VERSION "dbc-export 1 2025.20.8"

NS_ :

BS_:

BU_: APP BMS CC CMP CMPD CP DAS DI DIF DIR EPBL EPBR EVSE FC GTW HCML HCMR HVP ICR PCS PM PMF PMR PTC SCCM SCM SCS SDCR TAS UMC VC VCFRONT VCLEFT VCRIGHT VCSEC

BO_ 798 CP_alertMatrix: 8 CP
 SG_ CP_matrixIndex M : 0|4@1+ (1,0) [0|15] "" Vector__XXX
 SG_ CP_a001_canRx m0 : 4|1@1+ (1,0) [0|1] "" Vector__XXX
 SG_ CP_a002_canTx m0 : 5|1@1+ (1,0) [0|1] "" Vector__XXX
 SG_ CP_a003_canError m0 : 6|1@1+ (1,0) [0|1] "" Vector__XXX
 SG_ CP_a004_proximityRationality m0 : 7|1@1+ (1,0) [0|1] "" Vector__XXX
 SG_ CP_a005_gbdcLiveDisconnect m0 : 8|1@1+ (1,0) [0|1] "" Vector__XXX
 SG_ CP_a006_lostCommsBMS m0 : 9|1@1+ (1,0) [0|1] "" Vector__XXX
 SG_ CP_a007_watchdog m0 : 10|1@1+ (1,0) [0|1] "" Vector__XXX
 SG_ CP_a008_memoryError m0 : 11|1@1+ (1,0) [0|1] "" Vector__XXX
 SG_ CP_a009_coverOpenAllChgBlocked m0 : 12|1@1+ (1,0) [0|1] "" Vector__XXX
 SG_ CP_a010_pilotRationality m0 : 13|1@1+ (1,0) [0|1] "" Vector__XXX
 SG_ CP_a011_eeprom m0 : 14|1@1+ (1,0) [0|1] "" Vector__XXX
 SG_ CP_a012_ledDriver m0 : 15|1@1+ (1,0) [0|1] "" Vector__XXX
 SG_ CP_a013_lostCommsGTW m0 : 16|1@1+ (1,0) [0|1] "" Vector__XXX
 SG_ CP_a014_lostCommsCHG m0 : 17|1@1+ (1,0) [0|1] "" Vector__XXX
 SG_ CP_a015_apsVov m0 : 18|1@1+ (1,0) [0|1] "" Vector__XXX
 SG_ CP_a016_apsVuv m0 : 19|1@1+ (1,0) [0|1] "" Vector__XXX
 SG_ CP_a017_fiveVov m0 : 20|1@1+ (1,0) [0|1] "" Vector__XXX
 SG_ CP_a018_fiveVuv m0 : 21|1@1+ (1,0) [0|1] "" Vector__XXX
 SG_ CP_a019_threeVov m0 : 22|1@1+ (1,0) [0|1] "" Vector__XXX
 SG_ CP_a020_threeVuv m0 : 23|1@1+ (1,0) [0|1] "" Vector__XXX
 SG_ CP_a021_zeroVov m0 : 24|1@1+ (1,0) [0|1] "" Vector__XXX
 SG_ CP_a022_zeroVuv m0 : 25|1@1+ (1,0) [0|1] "" Vector__XXX
 SG_ CP_a023_gbdcSessionFailed m0 : 26|1@1+ (1,0) [0|1] "" Vector__XXX
 SG_ CP_a024_ledsUC m0 : 27|1@1+ (1,0) [0|1] "" Vector__XXX
 SG_ CP_a025_ledsOC m0 : 28|1@1+ (1,0) [0|1] "" Vector__XXX
 SG_ CP_a026_networkManagement m0 : 29|1@1+ (1,0) [0|1] "" Vector__XXX
 SG_ CP_a027_doorSensorOutOfSpec m0 : 30|1@1+ (1,0) [0|1] "" Vector__XXX
 SG_ CP_a028_insertEnableMismatch m0 : 31|1@1+ (1,0) [0|1] "" Vector__XXX
 SG_ CP_a029_doorClosedProxPilot m0 : 32|1@1+ (1,0) [0|1] "" Vector__XXX
 SG_ CP_a030_busOff m0 : 33|1@1+ (1,0) [0|1] "" Vector__XXX
 SG_ CP_a031_doorClosedCommandedOpen m0 : 34|1@1+ (1,0) [0|1] "" Vector__XXX
 SG_ CP_a032_doorOpenExpectedClosed m0 : 35|1@1+ (1,0) [0|1] "" Vector__XXX
 SG_ CP_a033_spiOpen m0 : 36|1@1+ (1,0) [0|1] "" Vector__XXX
 SG_ CP_a034_calibrationIncomplete m0 : 37|1@1+ (1,0) [0|1] "" Vector__XXX
 SG_ CP_a035_latchMovement_1 m0 : 38|1@1+ (1,0) [0|1] "" Vector__XXX
 SG_ CP_a036_latchNotDisengaged m0 : 39|1@1+ (1,0) [0|1] "" Vector__XXX
 SG_ CP_a037_latchNotEngaged m0 : 40|1@1+ (1,0) [0|1] "" Vector__XXX
 SG_ CP_a038_latchNotBlocking m0 : 41|1@1+ (1,0) [0|1] "" Vector__XXX
 SG_ CP_a039_latchMovement_2 m0 : 42|1@1+ (1,0) [0|1] "" Vector__XXX
 SG_ CP_a040_doNotUse m0 : 43|1@1+ (1,0) [0|1] "" Vector__XXX
 SG_ CP_a041_doorSensorUnplugged m0 : 44|1@1+ (1,0) [0|1] "" Vector__XXX
 SG_ CP_a042_doorAssemblyBroken m0 : 45|1@1+ (1,0) [0|1] "" Vector__XXX
 SG_ CP_a043_doorPotIrrational m0 : 46|1@1+ (1,0) [0|1] "" Vector__XXX
 SG_ CP_a044_lostCommsHVP m0 : 47|1@1+ (1,0) [0|1] "" Vector__XXX
 SG_ CP_a045_lostCommsVCSEC m0 : 48|1@1+ (1,0) [0|1] "" Vector__XXX
 SG_ CP_a046_lostCommsEVSE m0 : 49|1@1+ (1,0) [0|1] "" Vector__XXX
 SG_ CP_a047_lostCommsVCFRONT m0 : 50|1@1+ (1,0) [0|1] "" Vector__XXX
 SG_ CP_a048_lostCommsUI m0 : 51|1@1+ (1,0) [0|1] "" Vector__XXX
 SG_ CP_a049_multipleCablesDetected m0 : 52|1@1+ (1,0) [0|1] "" Vector__XXX
 SG_ CP_a050_latchNotConnected m0 : 53|1@1+ (1,0) [0|1] "" Vector__XXX
 SG_ CP_a051_doorInductiveSensorMIA m0 : 54|1@1+ (1,0) [0|1] "" Vector__XXX
 SG_ CP_a052_chademoNotSupported m0 : 55|1@1+ (1,0) [0|1] "" Vector__XXX
 SG_ CP_a053_proxLatchedNoPilot m0 : 56|1@1+ (1,0) [0|1] "" Vector__XXX
 SG_ CP_a054_cableNotSecured m0 : 57|1@1+ (1,0) [0|1] "" Vector__XXX
 SG_ CP_a055_chargeStoppedNoPilot m0 : 58|1@1+ (1,0) [0|1] "" Vector__XXX
 SG_ CP_a056_proxDisconnected m0 : 59|1@1+ (1,0) [0|1] "" Vector__XXX
 SG_ CP_a057_ccs1AdapterBtnPress m0 : 60|1@1+ (1,0) [0|1] "" Vector__XXX
 SG_ CP_a058_acChargeRetryPending m0 : 61|1@1+ (1,0) [0|1] "" Vector__XXX
 SG_ CP_a059_swcanError m0 : 62|1@1+ (1,0) [0|1] "" Vector__XXX
 SG_ CP_a060_lostCommsPCS m0 : 63|1@1+ (1,0) [0|1] "" Vector__XXX
 SG_ CP_a061_uhfReceiverMIA m1 : 4|1@1+ (1,0) [0|1] "" Vector__XXX
 SG_ CP_a062_scOutOfService m1 : 5|1@1+ (1,0) [0|1] "" Vector__XXX
 SG_ CP_a063_scUpdateInProgress m1 : 6|1@1+ (1,0) [0|1] "" Vector__XXX
 SG_ CP_a064_superchargingBlocked m1 : 7|1@1+ (1,0) [0|1] "" Vector__XXX
 SG_ CP_a065_selfTestFailed m1 : 8|1@1+ (1,0) [0|1] "" Vector__XXX
 SG_ CP_a066_proxLatchedIdlePilot m1 : 9|1@1+ (1,0) [0|1] "" Vector__XXX
 SG_ CP_a067_gbdcConnFault m1 : 10|1@1+ (1,0) [0|1] "" Vector__XXX
 SG_ CP_a068_doorSensorMismatch m1 : 11|1@1+ (1,0) [0|1] "" Vector__XXX
 SG_ CP_a069_doorInductiveSensorError m1 : 12|1@1+ (1,0) [0|1] "" Vector__XXX
 SG_ CP_a070_doorInductiveSensorReset m1 : 13|1@1+ (1,0) [0|1] "" Vector__XXX
 SG_ CP_a071_exiDecodeFailure m1 : 14|1@1+ (1,0) [0|1] "" Vector__XXX
 SG_ CP_a072_v2gEvccTimeout m1 : 15|1@1+ (1,0) [0|1] "" Vector__XXX
 SG_ CP_a073_iecComboShutdown m1 : 16|1@1+ (1,0) [0|1] "" Vector__XXX
 SG_ CP_a074_failedToEstablishV2gComm m1 : 17|1@1+ (1,0) [0|1] "" Vector__XXX
 SG_ CP_a075_v2gCommsFailure m1 : 18|1@1+ (1,0) [0|1] "" Vector__XXX
 SG_ CP_a076_LDC1612errorWatchdog m1 : 19|1@1+ (1,0) [0|1] "" Vector__XXX
 SG_ CP_a077_invalidMacAddress m1 : 20|1@1+ (1,0) [0|1] "" Vector__XXX
 SG_ CP_a078_latchNotDisengagedCold m1 : 21|1@1+ (1,0) [0|1] "" Vector__XXX
 SG_ CP_a079_cableNotSecuredCold m1 : 22|1@1+ (1,0) [0|1] "" Vector__XXX
 SG_ CP_a080_taskStackOverflow m1 : 23|1@1+ (1,0) [0|1] "" Vector__XXX
 SG_ CP_a081_swException m1 : 24|1@1+ (1,0) [0|1] "" Vector__XXX
 SG_ CP_a082_powerOnReset m1 : 25|1@1+ (1,0) [0|1] "" Vector__XXX
 SG_ CP_a083_watchdogTraceData m1 : 26|1@1+ (1,0) [0|1] "" Vector__XXX
 SG_ CP_a084_proxPeDisconnected_gb m1 : 27|1@1+ (1,0) [0|1] "" Vector__XXX
 SG_ CP_a085_dcPinTempFaulted m1 : 28|1@1+ (1,0) [0|1] "" Vector__XXX
 SG_ CP_a086_dcPinTempIrrational m1 : 29|1@1+ (1,0) [0|1] "" Vector__XXX
 SG_ CP_a087_dcTempModelFault m1 : 30|1@1+ (1,0) [0|1] "" Vector__XXX
 SG_ CP_a088_dcTempModelDeviation m1 : 31|1@1+ (1,0) [0|1] "" Vector__XXX
 SG_ CP_a089_plcConfigMismatch m1 : 32|1@1+ (1,0) [0|1] "" Vector__XXX
 SG_ CP_a090_ccsEvseLowIso m1 : 33|1@1+ (1,0) [0|1] "" Vector__XXX
 SG_ CP_a091_wrongSuperchargerHandle m1 : 34|1@1+ (1,0) [0|1] "" Vector__XXX
 SG_ CP_a092_modemAppLoadFailed m1 : 35|1@1+ (1,0) [0|1] "" Vector__XXX
 SG_ CP_a093_modemLoadedWithReset m1 : 36|1@1+ (1,0) [0|1] "" Vector__XXX
 SG_ CP_a094_inductiveResetSuccessful m1 : 37|1@1+ (1,0) [0|1] "" Vector__XXX
 SG_ CP_a095_thermalDcLimitActive m1 : 38|1@1+ (1,0) [0|1] "" Vector__XXX
 SG_ CP_a096_pilotWake m1 : 39|1@1+ (1,0) [0|1] "" Vector__XXX
 SG_ CP_a097_modeTransitionFailure m1 : 40|1@1+ (1,0) [0|1] "" Vector__XXX
 SG_ CP_a098_proximityWake m1 : 41|1@1+ (1,0) [0|1] "" Vector__XXX
 SG_ CP_a099_cableStateUnknown m1 : 42|1@1+ (1,0) [0|1] "" Vector__XXX
 SG_ CP_a100_inletHarnessIdIrrational m1 : 43|1@1+ (1,0) [0|1] "" Vector__XXX
 SG_ CP_a101_wcFoldbackActive m1 : 44|1@1+ (1,0) [0|1] "" Vector__XXX
 SG_ CP_a102_wcOvertempFault m1 : 45|1@1+ (1,0) [0|1] "" Vector__XXX
 SG_ CP_a103_proximityPeDisconnected m1 : 46|1@1+ (1,0) [0|1] "" Vector__XXX
 SG_ CP_a104_uhfResetSuccessful m1 : 47|1@1+ (1,0) [0|1] "" Vector__XXX
 SG_ CP_a105_hwUnableToSleep m1 : 48|1@1+ (1,0) [0|1] "" Vector__XXX
 SG_ CP_a106_uhfReceiverReset m1 : 49|1@1+ (1,0) [0|1] "" Vector__XXX
 SG_ CP_a107_chademoFoldbackActive m1 : 50|1@1+ (1,0) [0|1] "" Vector__XXX
 SG_ CP_a108_chademoOvertempFault m1 : 51|1@1+ (1,0) [0|1] "" Vector__XXX
 SG_ CP_a109_thermistorIrrational m1 : 52|1@1+ (1,0) [0|1] "" Vector__XXX
 SG_ CP_a110_thermalVelocityHigh m1 : 53|1@1+ (1,0) [0|1] "" Vector__XXX
 SG_ CP_a111_inletHeaterUnableToHeat m1 : 54|1@1+ (1,0) [0|1] "" Vector__XXX
 SG_ CP_a112_inletHeaterIrrationalTem m1 : 55|1@1+ (1,0) [0|1] "" Vector__XXX
 SG_ CP_a113_inletHeaterShortCircuit m1 : 56|1@1+ (1,0) [0|1] "" Vector__XXX
 SG_ CP_a114_ccsEvseFailed m1 : 57|1@1+ (1,0) [0|1] "" Vector__XXX
 SG_ CP_a115_unexpectedTcan1145State m1 : 58|1@1+ (1,0) [0|1] "" Vector__XXX
 SG_ CP_a116_misconfigurationDetected m1 : 59|1@1+ (1,0) [0|1] "" Vector__XXX
 SG_ CP_a117_inletHeaterUnableToRegul m1 : 60|1@1+ (1,0) [0|1] "" Vector__XXX
 SG_ CP_a118_iecComboLockUp m1 : 61|1@1+ (1,0) [0|1] "" Vector__XXX
 SG_ CP_a119_plcTransmitFailure m1 : 62|1@1+ (1,0) [0|1] "" Vector__XXX
 SG_ CP_a120_comboAdapterFoldback m1 : 63|1@1+ (1,0) [0|1] "" Vector__XXX
 SG_ CP_a121_PLCRLY_lostCommsCP m2 : 4|1@1+ (1,0) [0|1] "" Vector__XXX
 SG_ CP_a122_plcModemFailure m2 : 5|1@1+ (1,0) [0|1] "" Vector__XXX
 SG_ CP_a123_latchPotIrrational m2 : 6|1@1+ (1,0) [0|1] "" Vector__XXX
 SG_ CP_a124_ivledFault m2 : 7|1@1+ (1,0) [0|1] "" Vector__XXX
 SG_ CP_a125_unexpectedLVJuiceState m2 : 8|1@1+ (1,0) [0|1] "" Vector__XXX
 SG_ CP_a126_wakeOnUhfFault m2 : 9|1@1+ (1,0) [0|1] "" Vector__XXX
 SG_ CP_a127_lostCommsHVLINK m2 : 10|1@1+ (1,0) [0|1] "" Vector__XXX
 SG_ CP_a128_lostCommsVC m2 : 11|1@1+ (1,0) [0|1] "" Vector__XXX
 SG_ CP_a129_bldcDriverCommsFailed m2 : 12|1@1+ (1,0) [0|1] "" Vector__XXX
 SG_ CP_a130_bldcDriverCommsRecovered m2 : 13|1@1+ (1,0) [0|1] "" Vector__XXX
 SG_ CP_a131_evseCommTimeout m2 : 14|1@1+ (1,0) [0|1] "" Vector__XXX
 SG_ CP_a132_contractAuthTimeout m2 : 15|1@1+ (1,0) [0|1] "" Vector__XXX
 SG_ CP_a133_proxNeverLatched m2 : 16|1@1+ (1,0) [0|1] "" Vector__XXX
 SG_ CP_a134_plcModemNotExpected m2 : 17|1@1+ (1,0) [0|1] "" Vector__XXX
 SG_ CP_a135_sdpAttemptsFailed m2 : 18|1@1+ (1,0) [0|1] "" Vector__XXX
 SG_ CP_a136_sdpSideReqFailed m2 : 19|1@1+ (1,0) [0|1] "" Vector__XXX
 SG_ CP_a137_plcForwardError m2 : 20|1@1+ (1,0) [0|1] "" Vector__XXX
 SG_ CP_a138_swcanCommsAcEvseFaulted m2 : 21|1@1+ (1,0) [0|1] "" Vector__XXX
 SG_ CP_a139_pilotFaulted m2 : 22|1@1+ (1,0) [0|1] "" Vector__XXX
 SG_ CP_a140_superchargerFaulted m2 : 23|1@1+ (1,0) [0|1] "" Vector__XXX
 SG_ CP_a141_chademoAdapterFault m2 : 24|1@1+ (1,0) [0|1] "" Vector__XXX
 SG_ CP_a142_gbdcScConnFault m2 : 25|1@1+ (1,0) [0|1] "" Vector__XXX
 SG_ CP_a143_unsupportedChargeAdapter m2 : 26|1@1+ (1,0) [0|1] "" Vector__XXX
 SG_ CP_a144_nvmInitFailed m2 : 27|1@1+ (1,0) [0|1] "" Vector__XXX
 SG_ CP_a145_modemAppLoadFailedNA m2 : 28|1@1+ (1,0) [0|1] "" Vector__XXX
 SG_ CP_a146_ccsEvseMalfunction m2 : 29|1@1+ (1,0) [0|1] "" Vector__XXX
 SG_ CP_a147_inductiveRecoveredMia m2 : 30|1@1+ (1,0) [0|1] "" Vector__XXX
 SG_ CP_a148_bldcTachFeedbackMia m2 : 31|1@1+ (1,0) [0|1] "" Vector__XXX
 SG_ CP_a149_pilotPeriodInvalid m2 : 32|1@1+ (1,0) [0|1] "" Vector__XXX
 SG_ CP_a150_railToggleTimeout m2 : 33|1@1+ (1,0) [0|1] "" Vector__XXX
 SG_ CP_a151_badPilotDiodeDetected m2 : 34|1@1+ (1,0) [0|1] "" Vector__XXX
 SG_ CP_a152_pilotEdgeDetectionFailed m2 : 35|1@1+ (1,0) [0|1] "" Vector__XXX
 SG_ CP_a153_thermalAcLimitActive m2 : 36|1@1+ (1,0) [0|1] "" Vector__XXX
 SG_ CP_a154_acChargingStoppedOT m2 : 37|1@1+ (1,0) [0|1] "" Vector__XXX
 SG_ CP_a155_hallPresenceRationality m2 : 38|1@1+ (1,0) [0|1] "" Vector__XXX
 SG_ CP_a156_gbdcPrechargingConcern m2 : 39|1@1+ (1,0) [0|1] "" Vector__XXX
 SG_ CP_a157_doorOpenRateLimiter m2 : 40|1@1+ (1,0) [0|1] "" Vector__XXX
 SG_ CP_a158_doorCloseRateLimiter m2 : 41|1@1+ (1,0) [0|1] "" Vector__XXX
 SG_ CP_a159_swcanHealthCheckFailed m2 : 42|1@1+ (1,0) [0|1] "" Vector__XXX
 SG_ CP_a160_latchDisengageInDcCharge m2 : 43|1@1+ (1,0) [0|1] "" Vector__XXX
 SG_ CP_a161_badPilotDiodeDetectedCN m2 : 44|1@1+ (1,0) [0|1] "" Vector__XXX
 SG_ CP_a162_pilotEdgeDetectionFailed m2 : 45|1@1+ (1,0) [0|1] "" Vector__XXX
 SG_ CP_a163_coverOpenDcChgBlocked m2 : 46|1@1+ (1,0) [0|1] "" Vector__XXX
 SG_ CP_a164_latchRedisengageRequeste m2 : 47|1@1+ (1,0) [0|1] "" Vector__XXX
 SG_ CP_a165_proxWiggleDetected m2 : 48|1@1+ (1,0) [0|1] "" Vector__XXX
 SG_ CP_a166_faultLineMismatchDetecte m2 : 49|1@1+ (1,0) [0|1] "" Vector__XXX
 SG_ CP_a167_doorIdIrrational m2 : 50|1@1+ (1,0) [0|1] "" Vector__XXX
 SG_ CP_a172_triggerOdin m2 : 55|1@1+ (1,0) [0|1] "" Vector__XXX
 SG_ CP_a173_coverOpenAcChgBlocked m2 : 56|1@1+ (1,0) [0|1] "" Vector__XXX
 SG_ CP_a174_fwdedMsgLoadWarning m2 : 57|1@1+ (1,0) [0|1] "" Vector__XXX
 SG_ CP_a175_fwdedMsgDropped m2 : 58|1@1+ (1,0) [0|1] "" Vector__XXX
 SG_ CP_a177_incompatibleV2lDeviceDet m2 : 60|1@1+ (1,0) [0|1] "" Vector__XXX
 SG_ CP_a179_evseCommsTlsError m2 : 62|1@1+ (1,0) [0|1] "" Vector__XXX
 SG_ CP_a182_pncdCommsError m3 : 5|1@1+ (1,0) [0|1] "" Vector__XXX
 SG_ CP_a183_certManagerError m3 : 6|1@1+ (1,0) [0|1] "" Vector__XXX
 SG_ CP_a184_certChangeEvent m3 : 7|1@1+ (1,0) [0|1] "" Vector__XXX
 SG_ CP_a185_pncAuthRejection m3 : 8|1@1+ (1,0) [0|1] "" Vector__XXX
 SG_ CP_a186_spiDmaFailure m3 : 9|1@1+ (1,0) [0|1] "" Vector__XXX
 SG_ CP_a187_highStackUsage m3 : 10|1@1+ (1,0) [0|1] "" Vector__XXX

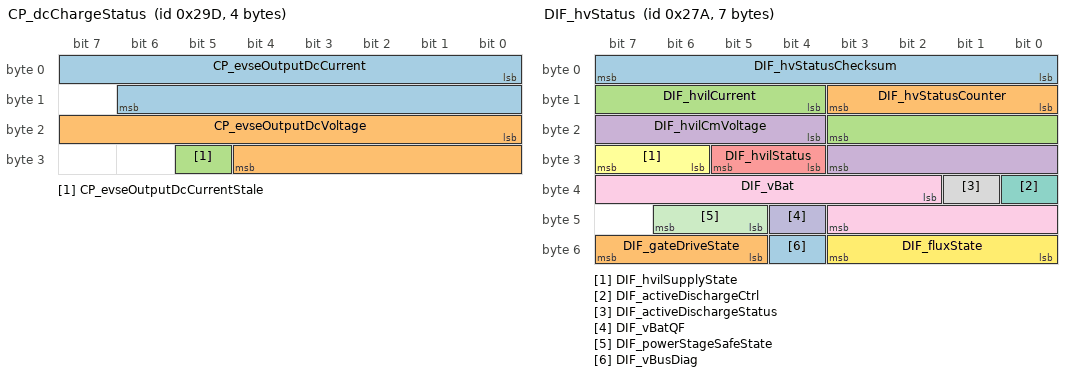
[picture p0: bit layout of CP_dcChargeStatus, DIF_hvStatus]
BO_ 669 CP_dcChargeStatus: 4 CP
 SG_ CP_evseOutputDcCurrent : 0|15@1- (0.125,0) [-2048|2047.875] "A" Vector__XXX
 SG_ CP_evseOutputDcVoltage : 16|13@1+ (0.07324219,0) [0|599.92675822] "V" Vector__XXX
 SG_ CP_evseOutputDcCurrentStale : 29|1@1+ (1,0) [0|1] "" Vector__XXX

BO_ 541 CP_evseStatus: 8 CP
 SG_ CP_evseAccept : 0|1@1+ (1,0) [0|1] "" Vector__XXX
 SG_ CP_evseRequest : 1|1@1+ (1,0) [0|1] "" Vector__XXX
 SG_ CP_proximity : 2|2@1+ (1,0) [1|3] "" Vector__XXX
 SG_ CP_pilot : 4|3@1+ (1,0) [0|6] "" Vector__XXX
 SG_ CP_digitalCommsEstablished : 7|1@1+ (1,0) [0|1] "" Vector__XXX
 SG_ CP_pilotCurrent : 8|8@1+ (0.5,0) [0|127.5] "A" Vector__XXX
 SG_ CP_cableType : 16|3@1+ (1,0) [0|7] "" Vector__XXX
 SG_ CP_iecPilotState : 19|4@1+ (1,0) [0|15] "" Vector__XXX
 SG_ CP_plcSupported : 23|1@1+ (1,0) [0|1] "" Vector__XXX
 SG_ CP_cableCurrentLimit : 24|7@1+ (1,0) [0|127] "A" Vector__XXX
 SG_ CP_teslaSwcanState : 34|4@1+ (1,0) [0|15] "" Vector__XXX
 SG_ CP_evseChargeType_UI : 38|2@1+ (1,0) [0|3] "" Vector__XXX
 SG_ CP_gbState : 40|4@1+ (1,0) [0|15] "" Vector__XXX
 SG_ CP_gbdcStopChargeReason : 44|4@1+ (1,0) [0|15] "" Vector__XXX
 SG_ CP_gbdcFailureReason : 48|2@1+ (1,0) [0|3] "" Vector__XXX
 SG_ CP_gbdcChargeAttempts : 50|2@1+ (1,0) [0|3] "" Vector__XXX
 SG_ CP_acChargeState : 52|3@1+ (1,0) [0|7] "" Vector__XXX
 SG_ CP_teslaDcState : 56|4@1+ (1,0) [0|15] "" Vector__XXX

BO_ 1342 CP_info: 8 CP
 SG_ CP_infoIndex M : 0|8@1+ (1,0) [0|255] "" Vector__XXX
 SG_ CP_buildType m10 : 8|3@1+ (1,0) [0|7] "" Vector__XXX
 SG_ CP_buildConfigId m10 : 16|16@1+ (1,0) [0|65535] "" Vector__XXX
 SG_ CP_hardwareId m10 : 32|16@1+ (1,0) [0|65535] "" Vector__XXX
 SG_ CP_componentId m10 : 48|16@1+ (1,0) [0|65535] "" Vector__XXX
 SG_ CP_pcbaId m11 : 16|8@1+ (1,0) [0|255] "" Vector__XXX
 SG_ CP_assemblyId m11 : 24|8@1+ (1,0) [0|255] "" Vector__XXX
 SG_ CP_usageId m11 : 32|16@1+ (1,0) [0|65535] "" Vector__XXX
 SG_ CP_subUsageId m11 : 48|16@1+ (1,0) [0|65535] "" Vector__XXX
 SG_ CP_platformType m13 : 8|8@1+ (1,0) [0|255] "" Vector__XXX
 SG_ CP_appCrc m13 : 32|32@1+ (1,0) [0|4294967295] "" Vector__XXX
 SG_ CP_appGitHash m17 : 8|56@1+ (1,0) [0|7.20575940379e+16] "" Vector__XXX
 SG_ CP_bootGitHash m18 : 8|56@1+ (1,0) [0|7.20575940379e+16] "" Vector__XXX
 SG_ CP_bootUdsProtoVersion m20 : 8|8@1+ (1,0) [0|255] "" Vector__XXX
 SG_ CP_bootCrc m20 : 32|32@1+ (1,0) [0|4294967295] "" Vector__XXX

BO_ 1885 CP_loggingFast: 8 CP
 SG_ CP_loggingFastSelect M : 0|4@1+ (1,0) [0|15] "" Vector__XXX
 SG_ CP_inductiveSensor_raw m0 : 4|28@1+ (1,0) [0|268435455] "" Vector__XXX
 SG_ CP_doorOpenActuationTime m0 : 32|14@1+ (1,0) [0|16383] "ms" Vector__XXX
 SG_ CP_doorCloseActuationTime m0 : 46|14@1+ (1,0) [0|16383] "ms" Vector__XXX
 SG_ CP_chargeCableSecured m0 : 60|1@1+ (1,0) [0|1] "" Vector__XXX
 SG_ CP_chargeCablePresent m0 : 61|1@1+ (1,0) [0|1] "" Vector__XXX
 SG_ CP_latchCheckAvailable m0 : 62|1@1+ (1,0) [0|1] "" Vector__XXX
 SG_ CP_UHF_controlState m2 : 4|4@1+ (1,0) [0|15] "" Vector__XXX
 SG_ CP_proximityV m2 : 8|16@1+ (0.0001,0) [0|6.5535] "V" Vector__XXX
 SG_ CP_proximityV_GBCC1 m2 : 24|14@1+ (0.001,0) [0|13.3] "V" Vector__XXX
 SG_ CP_proximityV_GBCC2 m2 : 38|14@1+ (0.001,0) [0|13.3] "V" Vector__XXX
 SG_ CP_doorPot m2 : 52|12@1+ (0.025,0) [0|100] "%" Vector__XXX
 SG_ CP_doorPresenceHallSensorV m3 : 4|12@1+ (0.001221,0) [0|4.999995] "V" Vector__XXX
 SG_ CP_doorOpenRequest m3 : 16|4@1+ (1,0) [0|15] "" Vector__XXX
 SG_ CP_doorOpenEndOfDriveReason m3 : 20|3@1+ (1,0) [0|7] "" Vector__XXX
 SG_ CP_coverClosed m3 : 23|1@1+ (1,0) [0|1] "" Vector__XXX
 SG_ CP_doorCloseEndOfDriveReason m3 : 24|3@1+ (1,0) [0|7] "" Vector__XXX
 SG_ CP_doorCloseRequest m3 : 27|5@1+ (1,0) [0|31] "" Vector__XXX
 SG_ CP_latchDisengagingTime m3 : 32|10@1+ (1,0) [0|1023] "ms" Vector__XXX
 SG_ CP_latchEngagingTime m3 : 42|10@1+ (1,0) [0|1023] "ms" Vector__XXX
 SG_ CP_latchDisengagingStopReason m3 : 52|3@1+ (1,0) [0|7] "" Vector__XXX
 SG_ CP_latchEngagingStopReason m3 : 56|3@1+ (1,0) [0|7] "" Vector__XXX
 SG_ CP_doorIdDetectionState m3 : 59|2@1+ (1,0) [1|3] "" Vector__XXX
 SG_ CP_doorIdDetectedBin m3 : 61|2@1+ (1,0) [0|3] "" Vector__XXX

BO_ 989 CP_loggingSlow: 8 CP
 SG_ CP_loggingSlowSelect M : 0|4@1+ (1,0) [0|15] "" Vector__XXX
 SG_ CP_UHF_chipState m3 : 4|3@1+ (1,0) [0|7] "" Vector__XXX
 SG_ CP_UHF_rssi m3 : 8|8@1+ (1,0) [0|255] "" Vector__XXX
 SG_ CP_UHF_rxOverflow m3 : 16|1@1+ (1,0) [0|1] "" Vector__XXX
 SG_ CP_UHF_rxNumBytes m3 : 17|8@1+ (1,0) [0|255] "" Vector__XXX
 SG_ CP_UHF_selfTestRssi m3 : 25|8@1+ (1,0) [0|255] "" Vector__XXX
 SG_ CP_latchI m3 : 33|12@1+ (0.0025,0) [0|10.2375] "A" Vector__XXX
 SG_ CP_inlet1HarnessIdState m3 : 45|2@1+ (1,0) [1|3] "" Vector__XXX
 SG_ CP_inlet1HarnessIdValue m3 : 47|3@1+ (1,0) [0|7] "" Vector__XXX
 SG_ CP_inlet2HarnessIdState m3 : 50|2@1+ (1,0) [1|3] "" Vector__XXX
 SG_ CP_inlet2HarnessIdValue m3 : 52|3@1+ (1,0) [0|7] "" Vector__XXX
 SG_ CP_inletHeaterState m3 : 55|2@1+ (1,0) [0|3] "" Vector__XXX
 SG_ CP_inletHeaterDuty m3 : 57|7@1+ (1,0) [0|100] "%" Vector__XXX
 SG_ CP_nvm_dataValid m5 : 4|1@1+ (1,0) [0|1] "" Vector__XXX
 SG_ CP_nvm_doorOpenCycles m5 : 8|16@1+ (1,0) [0|65535] "" Vector__XXX
 SG_ CP_nvm_doorCloseCycles m5 : 24|16@1+ (1,0) [0|65535] "" Vector__XXX
 SG_ CP_nvm_doorOpen m5 : 40|1@1+ (1,0) [0|1] "" Vector__XXX
 SG_ CP_nvm_doorPresent m5 : 41|1@1+ (1,0) [0|1] "" Vector__XXX
 SG_ CP_nvm_doorPresentValid m5 : 42|1@1+ (1,0) [0|1] "" Vector__XXX
 SG_ CP_nvm_badPilotDiodeDetected m5 : 43|1@1+ (1,0) [0|1] "" Vector__XXX
 SG_ CP_nvm_pilotDiodeFaultCount m5 : 44|3@1+ (1,0) [0|7] "" Vector__XXX
 SG_ CP_doorOpenLimiterMaxCount m5 : 47|4@1+ (1,0) [0|15] "counts" Vector__XXX
 SG_ CP_doorOpenLimiterMaxRequestType m5 : 51|4@1+ (1,0) [0|15] "" Vector__XXX
 SG_ CP_doorCloseLimiterMaxCount m5 : 55|4@1+ (1,0) [0|15] "counts" Vector__XXX
 SG_ CP_doorCloseLimiterMaxRequestTyp m5 : 59|5@1+ (1,0) [0|31] "" Vector__XXX

BO_ 605 CP_status: 8 CP
 SG_ CP_type : 0|2@1+ (1,0) [0|3] "" Vector__XXX
 SG_ CP_insertEnableLine : 2|1@1+ (1,0) [0|1] "" Vector__XXX
 SG_ CP_latchState : 3|2@1+ (1,0) [1|3] "" Vector__XXX
 SG_ CP_permanentPowerRequest : 5|1@1+ (1,0) [0|1] "" Vector__XXX
 SG_ CP_chargeDoorOpen : 6|1@1+ (1,0) [0|1] "" Vector__XXX
 SG_ CP_doorControlState : 8|3@1+ (1,0) [0|7] "" Vector__XXX
 SG_ CP_doorButtonPressed : 11|1@1+ (1,0) [0|1] "" Vector__XXX
 SG_ CP_swcanRelayClosed : 12|1@1+ (1,0) [0|1] "" Vector__XXX
 SG_ CP_inhibitOta : 13|1@1+ (1,0) [0|1] "" Vector__XXX
 SG_ CP_chargeCableState : 14|2@1+ (1,0) [1|3] "" Vector__XXX
 SG_ CP_latchControlState : 16|3@1+ (1,0) [0|7] "" Vector__XXX
 SG_ CP_ledColor : 19|4@1+ (1,0) [0|15] "" Vector__XXX
 SG_ CP_UHF_handleFound : 23|1@1+ (1,0) [0|1] "" Vector__XXX
 SG_ CP_faultLineSensed : 24|1@1+ (1,0) [0|1] "" Vector__XXX
 SG_ CP_doorPresenceState : 25|3@1+ (1,0) [0|7] "" Vector__XXX
 SG_ CP_inductiveSensorState : 28|3@1+ (1,0) [0|7] "" Vector__XXX
 SG_ CP_chargeDoorOpenUI : 31|1@1+ (1,0) [0|1] "" Vector__XXX
 SG_ CP_vehicleUnlockRequest : 32|1@1+ (1,0) [0|1] "" Vector__XXX
 SG_ CP_coldWeatherMode : 33|1@1+ (1,0) [0|1] "" Vector__XXX
 SG_ CP_hvInletExposed : 34|1@1+ (1,0) [0|1] "" Vector__XXX
 SG_ CP_latchEngaged : 35|1@1+ (1,0) [0|1] "" Vector__XXX
 SG_ CP_inletHeaterUiState : 40|3@1+ (1,0) [0|7] "" Vector__XXX

BO_ 893 CP_thermalStatus: 8 CP
 SG_ CP_thermalStatusSelect M : 0|1@1+ (1,0) [0|1] "" Vector__XXX
 SG_ CP_pinTemperature1 m1 : 8|8@1+ (0.8039216,-55) [-55|149.99] "C" Vector__XXX
 SG_ CP_pinTemperature2 m1 : 16|8@1+ (0.8039216,-55) [-55|149.99] "C" Vector__XXX
 SG_ CP_pinTemperature3 m1 : 24|8@1+ (0.8039216,-55) [-55|149.99] "C" Vector__XXX

BO_ 1001 DAS_bodyControls: 8 DAS
 SG_ DAS_headlightRequest : 0|2@1+ (1,0) [0|3] "" Vector__XXX
 SG_ DAS_hazardLightRequest : 2|2@1+ (1,0) [0|2] "" Vector__XXX
 SG_ DAS_wiperSpeed : 4|4@1+ (1,0) [0|15] "" Vector__XXX
 SG_ DAS_turnIndicatorRequest : 8|3@1+ (1,0) [0|7] "" Vector__XXX
 SG_ DAS_highLowBeamDecision : 11|2@1+ (1,0) [0|2] "" Vector__XXX
 SG_ DAS_heaterRequest : 13|2@1+ (1,0) [1|3] "" Vector__XXX
 SG_ DAS_highLowBeamOffReason : 15|3@1+ (1,0) [0|7] "" Vector__XXX
 SG_ DAS_forwardCamHeaterDutyCycle : 18|4@1+ (0.06666667,0) [0|1] "-" Vector__XXX
 SG_ DAS_dynamicBrakeLightRequest : 22|1@1+ (1,0) [0|1] "" Vector__XXX
 SG_ DAS_radarHeaterRequest : 23|1@1+ (1,0) [0|1] "" Vector__XXX
 SG_ DAS_ahlbOverride : 24|1@1+ (1,0) [0|1] "" Vector__XXX
 SG_ DAS_mirrorFoldRequest : 25|2@1+ (1,0) [0|2] "" Vector__XXX
 SG_ DAS_wiperWashRequest : 27|1@1+ (1,0) [0|1] "" Vector__XXX
 SG_ DAS_ulcConfirmationRequestActive : 28|1@1+ (1,0) [0|1] "" Vector__XXX
 SG_ DAS_overrideWiperSetting : 29|1@1+ (1,0) [0|1] "" Vector__XXX
 SG_ DAS_autoWiperState : 30|3@1+ (1,0) [0|7] "" Vector__XXX
 SG_ DAS_turnIndicatorRequestReason : 33|5@1+ (1,0) [0|31] "" Vector__XXX
 SG_ DAS_forwardRadarPowerRequest : 38|1@1+ (1,0) [0|1] "" Vector__XXX
 SG_ DAS_driverDomeLightRequest : 39|1@1+ (1,0) [0|1] "" Vector__XXX
 SG_ DAS_drivePowerStateRequest : 43|1@1+ (1,0) [0|1] "" Vector__XXX
 SG_ DAS_enableIcrDataCollection : 44|1@1+ (1,0) [0|1] "" Vector__XXX
 SG_ DAS_rPillarCamHeaterDutyCycle : 45|4@1+ (0.06666667,0) [0|1] "-" Vector__XXX
 SG_ DAS_adaptiveHighBeamIsFaulted : 49|1@1+ (1,0) [0|1] "" Vector__XXX
 SG_ DAS_restrictDoorReleaseLeft : 50|1@1+ (1,0) [0|1] "" Vector__XXX
 SG_ DAS_restrictDoorReleaseRight : 51|1@1+ (1,0) [0|1] "" Vector__XXX
 SG_ DAS_bodyControlsCounter : 52|4@1+ (1,0) [0|15] "" Vector__XXX
 SG_ DAS_bodyControlsChecksum : 56|8@1+ (1,0) [0|255] "" Vector__XXX

BO_ 1318 DIF_alertLog: 8 DIF
 SG_ DIF_alertID M : 0|8@1+ (1,0) [0|255] "" Vector__XXX
 SG_ DIF_alertState : 15|1@1+ (1,0) [0|1] "" Vector__XXX
 SG_ DIF_a001_thermalWarning_H m1 : 16|1@1+ (1,0) [0|1] "" Vector__XXX
 SG_ DIF_a001_thermalShutdown_H m1 : 17|1@1+ (1,0) [0|1] "" Vector__XXX
 SG_ DIF_a001_undervoltVL_H m1 : 18|1@1+ (1,0) [0|1] "" Vector__XXX
 SG_ DIF_a001_undervoltVH_H m1 : 19|1@1+ (1,0) [0|1] "" Vector__XXX
 SG_ DIF_a001_sense_H m1 : 20|1@1+ (1,0) [0|1] "" Vector__XXX
 SG_ DIF_a001_desat_H m1 : 21|1@1+ (1,0) [0|1] "" Vector__XXX
 SG_ DIF_a001_overvoltVL_H m1 : 22|1@1+ (1,0) [0|1] "" Vector__XXX
 SG_ DIF_a001_overvoltVH_H m1 : 23|1@1+ (1,0) [0|1] "" Vector__XXX
 SG_ DIF_a001_undervoltVCC_H m1 : 24|1@1+ (1,0) [0|1] "" Vector__XXX
 SG_ DIF_a001_asynchStop_H m1 : 25|1@1+ (1,0) [0|1] "" Vector__XXX
 SG_ DIF_a001_remoteRegError_H m1 : 26|1@1+ (1,0) [0|1] "" Vector__XXX
 SG_ DIF_a001_undervoltVDD_H m1 : 27|1@1+ (1,0) [0|1] "" Vector__XXX
 SG_ DIF_a001_overvoltVDD_H m1 : 28|1@1+ (1,0) [0|1] "" Vector__XXX
 SG_ DIF_a001_localRegError_H m1 : 29|1@1+ (1,0) [0|1] "" Vector__XXX
 SG_ DIF_a001_spiError_H m1 : 30|1@1+ (1,0) [0|1] "" Vector__XXX
 SG_ DIF_a001_deadtimeError_H m1 : 31|1@1+ (1,0) [0|1] "" Vector__XXX
 SG_ DIF_a001_thermalWarning_L m1 : 32|1@1+ (1,0) [0|1] "" Vector__XXX
 SG_ DIF_a001_thermalShutdown_L m1 : 33|1@1+ (1,0) [0|1] "" Vector__XXX
 SG_ DIF_a001_undervoltVL_L m1 : 34|1@1+ (1,0) [0|1] "" Vector__XXX
 SG_ DIF_a001_undervoltVH_L m1 : 35|1@1+ (1,0) [0|1] "" Vector__XXX
 SG_ DIF_a001_sense_L m1 : 36|1@1+ (1,0) [0|1] "" Vector__XXX
 SG_ DIF_a001_desat_L m1 : 37|1@1+ (1,0) [0|1] "" Vector__XXX
 SG_ DIF_a001_overvoltVL_L m1 : 38|1@1+ (1,0) [0|1] "" Vector__XXX
 SG_ DIF_a001_overvoltVH_L m1 : 39|1@1+ (1,0) [0|1] "" Vector__XXX
 SG_ DIF_a001_undervoltVCC_L m1 : 40|1@1+ (1,0) [0|1] "" Vector__XXX
 SG_ DIF_a001_asynchStop_L m1 : 41|1@1+ (1,0) [0|1] "" Vector__XXX
 SG_ DIF_a001_remoteRegError_L m1 : 42|1@1+ (1,0) [0|1] "" Vector__XXX
 SG_ DIF_a001_undervoltVDD_L m1 : 43|1@1+ (1,0) [0|1] "" Vector__XXX
 SG_ DIF_a001_overvoltVDD_L m1 : 44|1@1+ (1,0) [0|1] "" Vector__XXX
 SG_ DIF_a001_localRegError_L m1 : 45|1@1+ (1,0) [0|1] "" Vector__XXX
 SG_ DIF_a001_spiError_L m1 : 46|1@1+ (1,0) [0|1] "" Vector__XXX
 SG_ DIF_a001_deadtimeError_L m1 : 47|1@1+ (1,0) [0|1] "" Vector__XXX
 SG_ DIF_a001_gateDriveErrCounter m1 : 48|4@1+ (1,0) [0|15] "" Vector__XXX
 SG_ DIF_a001_remoteCommError_H m1 : 52|1@1+ (1,0) [0|1] "" Vector__XXX
 SG_ DIF_a001_localCommError_H m1 : 53|1@1+ (1,0) [0|1] "" Vector__XXX
 SG_ DIF_a001_remoteReset_H m1 : 54|1@1+ (1,0) [0|1] "" Vector__XXX
 SG_ DIF_a001_localReset_H m1 : 55|1@1+ (1,0) [0|1] "" Vector__XXX
 SG_ DIF_a001_remoteCommError_L m1 : 56|1@1+ (1,0) [0|1] "" Vector__XXX
 SG_ DIF_a001_localCommError_L m1 : 57|1@1+ (1,0) [0|1] "" Vector__XXX
 SG_ DIF_a001_remoteReset_L m1 : 58|1@1+ (1,0) [0|1] "" Vector__XXX
 SG_ DIF_a001_localReset_L m1 : 59|1@1+ (1,0) [0|1] "" Vector__XXX
 SG_ DIF_a001_faultLine1Gpio_H m1 : 60|1@1+ (1,0) [0|1] "" Vector__XXX
 SG_ DIF_a001_faultLine1Gpio_L m1 : 61|1@1+ (1,0) [0|1] "" Vector__XXX
 SG_ DIF_a002_thermalWarning_H m2 : 16|1@1+ (1,0) [0|1] "" Vector__XXX
 SG_ DIF_a002_thermalShutdown_H m2 : 17|1@1+ (1,0) [0|1] "" Vector__XXX
 SG_ DIF_a002_undervoltVL_H m2 : 18|1@1+ (1,0) [0|1] "" Vector__XXX
 SG_ DIF_a002_undervoltVH_H m2 : 19|1@1+ (1,0) [0|1] "" Vector__XXX
 SG_ DIF_a002_sense_H m2 : 20|1@1+ (1,0) [0|1] "" Vector__XXX
 SG_ DIF_a002_desat_H m2 : 21|1@1+ (1,0) [0|1] "" Vector__XXX
 SG_ DIF_a002_overvoltVL_H m2 : 22|1@1+ (1,0) [0|1] "" Vector__XXX
 SG_ DIF_a002_overvoltVH_H m2 : 23|1@1+ (1,0) [0|1] "" Vector__XXX
 SG_ DIF_a002_undervoltVCC_H m2 : 24|1@1+ (1,0) [0|1] "" Vector__XXX
 SG_ DIF_a002_asynchStop_H m2 : 25|1@1+ (1,0) [0|1] "" Vector__XXX
 SG_ DIF_a002_remoteRegError_H m2 : 26|1@1+ (1,0) [0|1] "" Vector__XXX
 SG_ DIF_a002_undervoltVDD_H m2 : 27|1@1+ (1,0) [0|1] "" Vector__XXX
 SG_ DIF_a002_overvoltVDD_H m2 : 28|1@1+ (1,0) [0|1] "" Vector__XXX
 SG_ DIF_a002_localRegError_H m2 : 29|1@1+ (1,0) [0|1] "" Vector__XXX
 SG_ DIF_a002_spiError_H m2 : 30|1@1+ (1,0) [0|1] "" Vector__XXX
 SG_ DIF_a002_deadtimeError_H m2 : 31|1@1+ (1,0) [0|1] "" Vector__XXX
 SG_ DIF_a002_thermalWarning_L m2 : 32|1@1+ (1,0) [0|1] "" Vector__XXX
 SG_ DIF_a002_thermalShutdown_L m2 : 33|1@1+ (1,0) [0|1] "" Vector__XXX
 SG_ DIF_a002_undervoltVL_L m2 : 34|1@1+ (1,0) [0|1] "" Vector__XXX
 SG_ DIF_a002_undervoltVH_L m2 : 35|1@1+ (1,0) [0|1] "" Vector__XXX
 SG_ DIF_a002_sense_L m2 : 36|1@1+ (1,0) [0|1] "" Vector__XXX
 SG_ DIF_a002_desat_L m2 : 37|1@1+ (1,0) [0|1] "" Vector__XXX
 SG_ DIF_a002_overvoltVL_L m2 : 38|1@1+ (1,0) [0|1] "" Vector__XXX
 SG_ DIF_a002_overvoltVH_L m2 : 39|1@1+ (1,0) [0|1] "" Vector__XXX
 SG_ DIF_a002_undervoltVCC_L m2 : 40|1@1+ (1,0) [0|1] "" Vector__XXX
 SG_ DIF_a002_asynchStop_L m2 : 41|1@1+ (1,0) [0|1] "" Vector__XXX
 SG_ DIF_a002_remoteRegError_L m2 : 42|1@1+ (1,0) [0|1] "" Vector__XXX
 SG_ DIF_a002_undervoltVDD_L m2 : 43|1@1+ (1,0) [0|1] "" Vector__XXX
 SG_ DIF_a002_overvoltVDD_L m2 : 44|1@1+ (1,0) [0|1] "" Vector__XXX
 SG_ DIF_a002_localRegError_L m2 : 45|1@1+ (1,0) [0|1] "" Vector__XXX
 SG_ DIF_a002_spiError_L m2 : 46|1@1+ (1,0) [0|1] "" Vector__XXX
 SG_ DIF_a002_deadtimeError_L m2 : 47|1@1+ (1,0) [0|1] "" Vector__XXX
 SG_ DIF_a002_gateDriveErrCounter m2 : 48|4@1+ (1,0) [0|15] "" Vector__XXX
 SG_ DIF_a002_selftestDesat_L m2 : 52|1@1+ (1,0) [0|1] "" Vector__XXX
 SG_ DIF_a002_selftestDesat_H m2 : 53|1@1+ (1,0) [0|1] "" Vector__XXX
 SG_ DIF_a002_remoteCommError_H m2 : 54|1@1+ (1,0) [0|1] "" Vector__XXX
 SG_ DIF_a002_localCommError_H m2 : 55|1@1+ (1,0) [0|1] "" Vector__XXX
 SG_ DIF_a002_remoteReset_H m2 : 56|1@1+ (1,0) [0|1] "" Vector__XXX
 SG_ DIF_a002_localReset_H m2 : 57|1@1+ (1,0) [0|1] "" Vector__XXX
 SG_ DIF_a002_remoteCommError_L m2 : 58|1@1+ (1,0) [0|1] "" Vector__XXX
 SG_ DIF_a002_localCommError_L m2 : 59|1@1+ (1,0) [0|1] "" Vector__XXX
 SG_ DIF_a002_remoteReset_L m2 : 60|1@1+ (1,0) [0|1] "" Vector__XXX
 SG_ DIF_a002_localReset_L m2 : 61|1@1+ (1,0) [0|1] "" Vector__XXX
 SG_ DIF_a002_faultLine1Gpio_H m2 : 62|1@1+ (1,0) [0|1] "" Vector__XXX
 SG_ DIF_a002_faultLine1Gpio_L m2 : 63|1@1+ (1,0) [0|1] "" Vector__XXX
 SG_ DIF_a003_thermalWarning_H m3 : 16|1@1+ (1,0) [0|1] "" Vector__XXX
 SG_ DIF_a003_thermalShutdown_H m3 : 17|1@1+ (1,0) [0|1] "" Vector__XXX
 SG_ DIF_a003_undervoltVL_H m3 : 18|1@1+ (1,0) [0|1] "" Vector__XXX
 SG_ DIF_a003_undervoltVH_H m3 : 19|1@1+ (1,0) [0|1] "" Vector__XXX
 SG_ DIF_a003_sense_H m3 : 20|1@1+ (1,0) [0|1] "" Vector__XXX
 SG_ DIF_a003_desat_H m3 : 21|1@1+ (1,0) [0|1] "" Vector__XXX
 SG_ DIF_a003_overvoltVL_H m3 : 22|1@1+ (1,0) [0|1] "" Vector__XXX
 SG_ DIF_a003_overvoltVH_H m3 : 23|1@1+ (1,0) [0|1] "" Vector__XXX
 SG_ DIF_a003_undervoltVCC_H m3 : 24|1@1+ (1,0) [0|1] "" Vector__XXX
 SG_ DIF_a003_asynchStop_H m3 : 25|1@1+ (1,0) [0|1] "" Vector__XXX
 SG_ DIF_a003_remoteRegError_H m3 : 26|1@1+ (1,0) [0|1] "" Vector__XXX
 SG_ DIF_a003_undervoltVDD_H m3 : 27|1@1+ (1,0) [0|1] "" Vector__XXX
 SG_ DIF_a003_overvoltVDD_H m3 : 28|1@1+ (1,0) [0|1] "" Vector__XXX
 SG_ DIF_a003_localRegError_H m3 : 29|1@1+ (1,0) [0|1] "" Vector__XXX
 SG_ DIF_a003_spiError_H m3 : 30|1@1+ (1,0) [0|1] "" Vector__XXX
 SG_ DIF_a003_deadtimeError_H m3 : 31|1@1+ (1,0) [0|1] "" Vector__XXX
 SG_ DIF_a003_thermalWarning_L m3 : 32|1@1+ (1,0) [0|1] "" Vector__XXX
 SG_ DIF_a003_thermalShutdown_L m3 : 33|1@1+ (1,0) [0|1] "" Vector__XXX
 SG_ DIF_a003_undervoltVL_L m3 : 34|1@1+ (1,0) [0|1] "" Vector__XXX
 SG_ DIF_a003_undervoltVH_L m3 : 35|1@1+ (1,0) [0|1] "" Vector__XXX
 SG_ DIF_a003_sense_L m3 : 36|1@1+ (1,0) [0|1] "" Vector__XXX
 SG_ DIF_a003_desat_L m3 : 37|1@1+ (1,0) [0|1] "" Vector__XXX
 SG_ DIF_a003_overvoltVL_L m3 : 38|1@1+ (1,0) [0|1] "" Vector__XXX
 SG_ DIF_a003_overvoltVH_L m3 : 39|1@1+ (1,0) [0|1] "" Vector__XXX
 SG_ DIF_a003_undervoltVCC_L m3 : 40|1@1+ (1,0) [0|1] "" Vector__XXX
 SG_ DIF_a003_asynchStop_L m3 : 41|1@1+ (1,0) [0|1] "" Vector__XXX
 SG_ DIF_a003_remoteRegError_L m3 : 42|1@1+ (1,0) [0|1] "" Vector__XXX
 SG_ DIF_a003_undervoltVDD_L m3 : 43|1@1+ (1,0) [0|1] "" Vector__XXX
 SG_ DIF_a003_overvoltVDD_L m3 : 44|1@1+ (1,0) [0|1] "" Vector__XXX
 SG_ DIF_a003_localRegError_L m3 : 45|1@1+ (1,0) [0|1] "" Vector__XXX
 SG_ DIF_a003_spiError_L m3 : 46|1@1+ (1,0) [0|1] "" Vector__XXX
 SG_ DIF_a003_deadtimeError_L m3 : 47|1@1+ (1,0) [0|1] "" Vector__XXX
 SG_ DIF_a003_gateDriveErrCounter m3 : 48|4@1+ (1,0) [0|15] "" Vector__XXX
 SG_ DIF_a003_selftestDesat_L m3 : 52|1@1+ (1,0) [0|1] "" Vector__XXX
 SG_ DIF_a003_selftestDesat_H m3 : 53|1@1+ (1,0) [0|1] "" Vector__XXX
 SG_ DIF_a003_remoteCommError_H m3 : 54|1@1+ (1,0) [0|1] "" Vector__XXX
 SG_ DIF_a003_localCommError_H m3 : 55|1@1+ (1,0) [0|1] "" Vector__XXX
 SG_ DIF_a003_remoteReset_H m3 : 56|1@1+ (1,0) [0|1] "" Vector__XXX
 SG_ DIF_a003_localReset_H m3 : 57|1@1+ (1,0) [0|1] "" Vector__XXX
 SG_ DIF_a003_remoteCommError_L m3 : 58|1@1+ (1,0) [0|1] "" Vector__XXX
 SG_ DIF_a003_localCommError_L m3 : 59|1@1+ (1,0) [0|1] "" Vector__XXX
 SG_ DIF_a003_remoteReset_L m3 : 60|1@1+ (1,0) [0|1] "" Vector__XXX
 SG_ DIF_a003_localReset_L m3 : 61|1@1+ (1,0) [0|1] "" Vector__XXX
 SG_ DIF_a003_faultLine1Gpio_H m3 : 62|1@1+ (1,0) [0|1] "" Vector__XXX
 SG_ DIF_a003_faultLine1Gpio_L m3 : 63|1@1+ (1,0) [0|1] "" Vector__XXX
 SG_ DIF_a007_phaseAcurrent m7 : 16|8@1+ (8,0) [0|2040] "A" Vector__XXX
 SG_ DIF_a007_phaseBcurrent m7 : 24|8@1+ (8,0) [0|2040] "A" Vector__XXX
 SG_ DIF_a007_offsetError m7 : 32|14@1- (0.0003834952,0) [-3.1415926784|3.1412091832] "rad" Vector__XXX
 SG_ DIF_a007_idFdbStdDeviation m7 : 46|8@1+ (4,0) [0|1020] "A" Vector__XXX
 SG_ DIF_a007_iqFdbStdDeviation m7 : 54|8@1+ (4,0) [0|1020] "A" Vector__XXX
 SG_ DIF_a007_motorShift m7 : 62|1@1+ (1,0) [0|1] "" Vector__XXX
 SG_ DIF_a007_motorShort m7 : 63|1@1+ (1,0) [0|1] "" Vector__XXX
 SG_ DIF_a010_sccReset m10 : 16|1@1+ (1,0) [0|1] "" Vector__XXX
 SG_ DIF_a010_hibernate m10 : 17|1@1+ (1,0) [0|1] "" Vector__XXX
 SG_ DIF_a010_hwBist m10 : 18|1@1+ (1,0) [0|1] "" Vector__XXX
 SG_ DIF_a010_nmiWatchdog m10 : 19|1@1+ (1,0) [0|1] "" Vector__XXX
 SG_ DIF_a010_watchdog m10 : 20|1@1+ (1,0) [0|1] "" Vector__XXX
 SG_ DIF_a010_clockFailNmi m10 : 21|1@1+ (1,0) [0|1] "" Vector__XXX
 SG_ DIF_a010_ramUncErrorNmi m10 : 22|1@1+ (1,0) [0|1] "" Vector__XXX
 SG_ DIF_a010_flashUncErrorNmi m10 : 23|1@1+ (1,0) [0|1] "" Vector__XXX
 SG_ DIF_a010_cpu1signMismatchNmi m10 : 24|1@1+ (1,0) [0|1] "" Vector__XXX
 SG_ DIF_a010_cpu2signMismatchNmi m10 : 25|1@1+ (1,0) [0|1] "" Vector__XXX
 SG_ DIF_a010_pieVectErrorNmi m10 : 26|1@1+ (1,0) [0|1] "" Vector__XXX
 SG_ DIF_a010_sysDbgNmi m10 : 27|1@1+ (1,0) [0|1] "" Vector__XXX
 SG_ DIF_a010_rlNmi m10 : 28|1@1+ (1,0) [0|1] "" Vector__XXX
 SG_ DIF_a010_ovfNmi m10 : 29|1@1+ (1,0) [0|1] "" Vector__XXX
 SG_ DIF_a010_wdtFlags m10 : 32|16@1+ (1,0) [0|65535] "" Vector__XXX
 SG_ DIF_a011_reason m11 : 16|3@1+ (1,0) [0|7] "" Vector__XXX
 SG_ DIF_a011_phaseAHigh m11 : 19|1@1+ (1,0) [0|1] "" Vector__XXX
 SG_ DIF_a011_phaseALow m11 : 20|1@1+ (1,0) [0|1] "" Vector__XXX
 SG_ DIF_a011_phaseBHigh m11 : 21|1@1+ (1,0) [0|1] "" Vector__XXX
 SG_ DIF_a011_phaseBLow m11 : 22|1@1+ (1,0) [0|1] "" Vector__XXX
 SG_ DIF_a011_phaseCHigh m11 : 23|1@1+ (1,0) [0|1] "" Vector__XXX
 SG_ DIF_a011_phaseCLow m11 : 24|1@1+ (1,0) [0|1] "" Vector__XXX
 SG_ DIF_a011_regAddress m11 : 25|5@1+ (1,0) [0|31] "" Vector__XXX
 SG_ DIF_a011_badGateDriveIC m11 : 32|3@1+ (1,0) [0|7] "" Vector__XXX
 SG_ DIF_a011_badDataRead m11 : 40|8@1+ (1,0) [0|255] "" Vector__XXX
 SG_ DIF_a011_badDataExpected m11 : 48|8@1+ (1,0) [0|255] "" Vector__XXX
 SG_ DIF_a011_codeBranch m11 : 56|4@1+ (1,0) [0|15] "" Vector__XXX
 SG_ DIF_a012_hvilStatus m12 : 16|2@1+ (1,0) [0|2] "" Vector__XXX
 SG_ DIF_a012_hvilCmVoltage m12 : 24|8@1+ (0.08,0) [0|20.4] "V" Vector__XXX
 SG_ DIF_a012_hvilCurrent m12 : 32|8@1+ (0.1,0) [0|25.5] "mA" Vector__XXX
 SG_ DIF_a012_hvilFaultGpio m12 : 40|1@1+ (1,0) [0|1] "" Vector__XXX
 SG_ DIF_a012_hvilSupplyPinDI m12 : 41|1@1+ (1,0) [0|1] "" Vector__XXX
 SG_ DIF_a012_hvilSupplyPinPM m12 : 42|1@1+ (1,0) [0|1] "" Vector__XXX
 SG_ DIF_a012_activeDisOn3V3 m12 : 43|1@1+ (1,0) [0|1] "" Vector__XXX
 SG_ DIF_a012_hvilHeaderFault m12 : 44|1@1+ (1,0) [0|1] "" Vector__XXX
 SG_ DIF_a013_address m13 : 16|32@1+ (1,0) [0|4294967295] "" Vector__XXX
 SG_ DIF_a013_errorType m13 : 48|4@1+ (1,0) [0|15] "" Vector__XXX
 SG_ DIF_a014_motorSpeed m14 : 16|14@1- (2,0) [-16384|16382] "RPM" Vector__XXX
 SG_ DIF_a014_adState m14 : 30|2@1+ (1,0) [0|3] "" Vector__XXX
 SG_ DIF_a014_torqueCommandFwd m14 : 32|10@1- (2,0) [-1024|1022] "Nm" Vector__XXX
 SG_ DIF_a014_brakeMasterCylPress m14 : 42|10@1+ (0.25,-42.5) [-42.5|213.25] "bar" Vector__XXX
 SG_ DIF_a014_rmsTorqueError m14 : 52|10@1+ (1,0) [0|1023] "Nm" Vector__XXX
 SG_ DIF_a014_tcEnabled m14 : 62|1@1+ (1,0) [0|1] "" Vector__XXX
 SG_ DIF_a016_newSafeState m16 : 16|2@1+ (1,0) [0|3] "" Vector__XXX
 SG_ DIF_a016_oldSafeState m16 : 18|2@1+ (1,0) [0|3] "" Vector__XXX
 SG_ DIF_a016_gateDriveFaultLine m16 : 20|1@1+ (1,0) [0|1] "" Vector__XXX
 SG_ DIF_a016_ascMonitor m16 : 21|1@1+ (1,0) [0|1] "" Vector__XXX
 SG_ DIF_a016_uncontrolledRegenZone m16 : 22|1@1+ (1,0) [0|1] "" Vector__XXX
 SG_ DIF_a016_pedalMonitorPreWatchdog m16 : 23|1@1+ (1,0) [0|1] "" Vector__XXX
 SG_ DIF_a016_motorRPM m16 : 24|16@1- (1,0) [-32768|32767] "RPM" Vector__XXX
 SG_ DIF_a016_torqueMotor m16 : 40|16@1- (1,0) [-32768|32767] "Nm" Vector__XXX
 SG_ DIF_a016_safetyICfaultLine m16 : 56|1@1+ (1,0) [0|1] "" Vector__XXX
 SG_ DIF_a016_triggerEvent m16 : 57|5@1+ (1,0) [0|31] "" Vector__XXX
 SG_ DIF_a024_vBat m24 : 16|8@1+ (2,0) [0|510] "V" Vector__XXX
 SG_ DIF_a024_failReason m24 : 24|3@1+ (1,0) [0|7] "" Vector__XXX
 SG_ DIF_a024_state m24 : 27|4@1+ (1,0) [0|15] "" Vector__XXX
 SG_ DIF_a024_Ia m24 : 31|7@1- (22.5,0) [-1440|1417.5] "A" Vector__XXX
 SG_ DIF_a024_Ib m24 : 38|7@1- (22.5,0) [-1440|1417.5] "A" Vector__XXX
 SG_ DIF_a024_maxCurrMagSqrd m24 : 45|12@1+ (500,0) [0|2047500] "A2" Vector__XXX
 SG_ DIF_a024_rotorAngle m24 : 57|7@1- (3,0) [-192|189] "degrees" Vector__XXX
 SG_ DIF_a025_Ia m25 : 16|16@1- (0.1,0) [-3276.8|3276.7] "A" Vector__XXX
 SG_ DIF_a025_torqueMotor m25 : 32|13@1- (0.25,0) [-1024|1023.75] "Nm" Vector__XXX
 SG_ DIF_a025_motorSpeed m25 : 48|16@1- (1,0) [-32768|32767] "RPM" Vector__XXX
 SG_ DIF_a026_Ib m26 : 16|16@1- (0.1,0) [-3276.8|3276.7] "A" Vector__XXX
 SG_ DIF_a026_torqueMotor m26 : 32|13@1- (0.25,0) [-1024|1023.75] "Nm" Vector__XXX
 SG_ DIF_a026_motorSpeed m26 : 48|16@1- (1,0) [-32768|32767] "RPM" Vector__XXX
 SG_ DIF_a027_Ic m27 : 16|16@1- (0.1,0) [-3276.8|3276.7] "A" Vector__XXX
 SG_ DIF_a027_torqueMotor m27 : 32|13@1- (0.25,0) [-1024|1023.75] "Nm" Vector__XXX
 SG_ DIF_a027_motorSpeed m27 : 48|16@1- (1,0) [-32768|32767] "RPM" Vector__XXX
 SG_ DIF_a028_phaseAirms m28 : 16|16@1+ (1,0) [0|65535] "A" Vector__XXX
 SG_ DIF_a028_iArmsTorque m28 : 32|16@1+ (0.25,0) [0|16383.75] "Nm" Vector__XXX
 SG_ DIF_a028_iArmsSpeed m28 : 48|16@1+ (1,0) [0|65535] "RPM" Vector__XXX
 SG_ DIF_a029_phaseBirms m29 : 16|16@1+ (1,0) [0|65535] "A" Vector__XXX
 SG_ DIF_a029_iBrmsTorque m29 : 32|16@1+ (0.25,0) [0|16383.75] "Nm" Vector__XXX
 SG_ DIF_a029_iBrmsSpeed m29 : 48|16@1+ (1,0) [0|65535] "RPM" Vector__XXX
 SG_ DIF_a030_phaseCirms m30 : 16|16@1+ (1,0) [0|65535] "A" Vector__XXX
 SG_ DIF_a030_iCrmsTorque m30 : 32|16@1+ (0.25,0) [0|16383.75] "Nm" Vector__XXX
 SG_ DIF_a030_iCrmsSpeed m30 : 48|16@1+ (1,0) [0|65535] "RPM" Vector__XXX
 SG_ DIF_a031_phaseAoffset m31 : 16|16@1- (0.002,0) [-65.536|65.534] "A" Vector__XXX
 SG_ DIF_a032_phaseBoffset m32 : 16|16@1- (0.002,0) [-65.536|65.534] "A" Vector__XXX
 SG_ DIF_a033_phaseAcurrent m33 : 16|16@1- (1,0) [-32768|32767] "A" Vector__XXX
 SG_ DIF_a033_deltaIa m33 : 32|16@1- (1,0) [-32768|32767] "A" Vector__XXX
 SG_ DIF_a033_vRefIa m33 : 48|16@1- (0.001,0) [-32.768|32.767] "V" Vector__XXX
 SG_ DIF_a034_phaseBcurrent m34 : 16|16@1- (1,0) [-32768|32767] "A" Vector__XXX
 SG_ DIF_a034_deltaIb m34 : 32|16@1- (1,0) [-32768|32767] "A" Vector__XXX
 SG_ DIF_a034_vRefIb m34 : 48|16@1- (0.001,0) [-32.768|32.767] "V" Vector__XXX
 SG_ DIF_a035_phaseAerror m35 : 16|1@1+ (1,0) [0|1] "" Vector__XXX
 SG_ DIF_a035_phaseBerror m35 : 17|1@1+ (1,0) [0|1] "" Vector__XXX
 SG_ DIF_a035_phaseCerror m35 : 18|1@1+ (1,0) [0|1] "" Vector__XXX
 SG_ DIF_a035_standbyCurrent m35 : 19|1@1+ (1,0) [0|1] "" Vector__XXX
 SG_ DIF_a035_unbalancedCurrent m35 : 20|1@1+ (1,0) [0|1] "" Vector__XXX
 SG_ DIF_a035_wontMoveCurrent m35 : 21|1@1+ (1,0) [0|1] "" Vector__XXX
 SG_ DIF_a035_reportingPhase m35 : 22|2@1+ (1,0) [0|3] "" Vector__XXX
 SG_ DIF_a035_noDriveCurrent m35 : 24|1@1+ (1,0) [0|1] "" Vector__XXX
 SG_ DIF_a035_phaseDifference m35 : 25|7@1+ (1,0) [0|127] "%" Vector__XXX
 SG_ DIF_a035_phaseCurrent m35 : 32|16@1+ (1,0) [0|65535] "A" Vector__XXX
 SG_ DIF_a035_frequency m35 : 48|10@1+ (1,0) [0|1023] "Hz" Vector__XXX
 SG_ DIF_a036_busVoltage m36 : 16|16@1+ (0.1,0) [0|6553.5] "V" Vector__XXX
 SG_ DIF_a036_busHighLimit m36 : 32|16@1+ (0.1,0) [0|6553.5] "V" Vector__XXX
 SG_ DIF_a037_busVoltage m37 : 16|16@1+ (0.1,0) [0|6553.5] "V" Vector__XXX
 SG_ DIF_a037_busLowLimit m37 : 32|16@1+ (0.1,0) [0|6553.5] "V" Vector__XXX
 SG_ DIF_a038_vBMS m38 : 16|13@1+ (0.2,0) [0|1638.2] "V" Vector__XXX
 SG_ DIF_a038_vBat m38 : 32|13@1+ (0.2,0) [0|1638.2] "V" Vector__XXX
 SG_ DIF_a038_iBat m38 : 48|13@1+ (0.5,0) [0|4095.5] "A" Vector__XXX
 SG_ DIF_a038_reason m38 : 61|2@1+ (1,0) [0|3] "" Vector__XXX
 SG_ DIF_a040_torque m40 : 16|1@1+ (1,0) [0|1] "" Vector__XXX
 SG_ DIF_a040_capability m40 : 17|1@1+ (1,0) [0|1] "" Vector__XXX
 SG_ DIF_a040_power m40 : 18|1@1+ (1,0) [0|1] "" Vector__XXX
 SG_ DIF_a040_status m40 : 19|1@1+ (1,0) [0|1] "" Vector__XXX
 SG_ DIF_a040_capability2 m40 : 20|1@1+ (1,0) [0|1] "" Vector__XXX
 SG_ DIF_a040_hvStatus m40 : 21|1@1+ (1,0) [0|1] "" Vector__XXX
 SG_ DIF_a040_temperature m40 : 22|1@1+ (1,0) [0|1] "" Vector__XXX
 SG_ DIF_a041_uartRxDataAvailable m41 : 16|1@1+ (1,0) [0|1] "" Vector__XXX
 SG_ DIF_a041_SDC_status_MIA m41 : 17|1@1+ (1,0) [0|1] "" Vector__XXX
 SG_ DIF_a041_diUartRxVersion m41 : 18|4@1+ (1,0) [0|15] "" Vector__XXX
 SG_ DIF_a041_sdcUartRxVersion m41 : 24|4@1+ (1,0) [0|15] "" Vector__XXX
 SG_ DIF_a043_outletTemp m43 : 16|16@1- (0.1,0) [-3276.8|3276.7] "C" Vector__XXX
 SG_ DIF_a044_outletTemp m44 : 16|16@1- (0.1,0) [-3276.8|3276.7] "C" Vector__XXX
 SG_ DIF_a045_inletTemp m45 : 16|10@1+ (0.25,-60) [-60|195.75] "DegC" Vector__XXX
 SG_ DIF_a045_outletTemp m45 : 26|10@1+ (0.25,-60) [-60|195.75] "DegC" Vector__XXX
 SG_ DIF_a045_heatsinkTemp m45 : 36|10@1+ (0.25,-60) [-60|195.75] "DegC" Vector__XXX
 SG_ DIF_a045_outletTempSlope m45 : 48|8@1- (0.5,0) [-64|63.5] "DegC/s" Vector__XXX
 SG_ DIF_a046_statorTemp1 m46 : 16|16@1- (0.1,0) [-3276.8|3276.7] "DegC" Vector__XXX
 SG_ DIF_a046_statorTemp2 m46 : 32|16@1- (0.1,0) [-3276.8|3276.7] "DegC" Vector__XXX
 SG_ DIF_a047_statorTemp1 m47 : 16|16@1- (0.1,0) [-3276.8|3276.7] "DegC" Vector__XXX
 SG_ DIF_a047_statorTslope1 m47 : 32|16@1- (0.1,0) [-3276.8|3276.7] "DegC/s" Vector__XXX
 SG_ DIF_a050_statorTemp1 m50 : 16|16@1- (0.1,0) [-3276.8|3276.7] "DegC" Vector__XXX
 SG_ DIF_a050_statorTemp2 m50 : 32|16@1- (0.1,0) [-3276.8|3276.7] "DegC" Vector__XXX
 SG_ DIF_a052_torque m52 : 16|1@1+ (1,0) [0|1] "" Vector__XXX
 SG_ DIF_a052_capability m52 : 17|1@1+ (1,0) [0|1] "" Vector__XXX
 SG_ DIF_a052_power m52 : 18|1@1+ (1,0) [0|1] "" Vector__XXX
 SG_ DIF_a052_status m52 : 19|1@1+ (1,0) [0|1] "" Vector__XXX
 SG_ DIF_a052_capability2 m52 : 20|1@1+ (1,0) [0|1] "" Vector__XXX
 SG_ DIF_a052_hvStatus m52 : 21|1@1+ (1,0) [0|1] "" Vector__XXX
 SG_ DIF_a052_temperature m52 : 22|1@1+ (1,0) [0|1] "" Vector__XXX
 SG_ DIF_a054_outletTemp m54 : 16|16@1- (0.1,0) [-3276.8|3276.7] "C" Vector__XXX
 SG_ DIF_a054_heatsinkTemp m54 : 32|16@1- (0.1,0) [-3276.8|3276.7] "C" Vector__XXX
 SG_ DIF_a055_parameterDI m55 : 16|13@1- (0.25,0) [-1024|1023.75] "Nm" Vector__XXX
 SG_ DIF_a055_parameterPM m55 : 32|13@1- (0.25,0) [-1024|1023.75] "Nm" Vector__XXX
 SG_ DIF_a055_torqueType m55 : 45|2@1+ (1,0) [0|3] "" Vector__XXX
 SG_ DIF_a055_motorRPM m55 : 48|16@1- (1,0) [-32768|32767] "RPM" Vector__XXX
 SG_ DIF_a056_pcbTemp m56 : 16|16@1- (0.1,0) [-3276.8|3276.7] "C" Vector__XXX
 SG_ DIF_a057_pcbTemp m57 : 16|16@1- (0.1,0) [-3276.8|3276.7] "C" Vector__XXX
 SG_ DIF_a058_pcbTemp m58 : 16|10@1+ (0.25,-60) [-60|195.75] "DegC" Vector__XXX
 SG_ DIF_a058_outletTemp m58 : 26|10@1+ (0.25,-60) [-60|195.75] "DegC" Vector__XXX
 SG_ DIF_a058_heatsinkTemp m58 : 36|10@1+ (0.25,-60) [-60|195.75] "DegC" Vector__XXX
 SG_ DIF_a058_pcbTempSlope m58 : 48|8@1- (0.5,0) [-64|63.5] "DegC/s" Vector__XXX
 SG_ DIF_a059_heatsinkTemp m59 : 16|16@1- (0.1,0) [-3276.8|3276.7] "C" Vector__XXX
 SG_ DIF_a060_heatsinkTemp m60 : 16|16@1- (0.1,0) [-3276.8|3276.7] "C" Vector__XXX
 SG_ DIF_a061_sensor m61 : 16|2@1+ (1,0) [0|3] "" Vector__XXX
 SG_ DIF_a061_reason m61 : 18|1@1+ (1,0) [0|1] "" Vector__XXX
 SG_ DIF_a061_phTemp m61 : 24|16@1- (0.1,0) [-3276.8|3276.7] "C" Vector__XXX
 SG_ DIF_a061_otherTemp m61 : 40|16@1- (0.1,0) [-3276.8|3276.7] "C" Vector__XXX
 SG_ DIF_a062_limpReason m62 : 16|6@1+ (1,0) [0|63] "" Vector__XXX
 SG_ DIF_a063_BB_status m63 : 16|1@1+ (1,0) [0|1] "" Vector__XXX
 SG_ DIF_a064_interventionType m64 : 16|4@1+ (1,0) [0|15] "" Vector__XXX
 SG_ DIF_a064_torqueCmdState m64 : 20|4@1+ (1,0) [1|15] "" Vector__XXX
 SG_ DIF_a066_badValue1 m66 : 16|16@1+ (1,0) [0|65535] "" Vector__XXX
 SG_ DIF_a066_badValue2 m66 : 32|16@1+ (1,0) [0|65535] "" Vector__XXX
 SG_ DIF_a066_canID m66 : 48|12@1+ (1,0) [0|4095] "" Vector__XXX
 SG_ DIF_a066_errorType m66 : 60|3@1+ (1,0) [0|7] "" Vector__XXX
 SG_ DIF_a069_motorSpeed m69 : 16|16@1- (1,0) [-32768|32767] "RPM" Vector__XXX
 SG_ DIF_a069_rotorCoolingPower m69 : 32|8@1+ (20,0) [0|5100] "W" Vector__XXX
 SG_ DIF_a069_rotorMagnetTemp m69 : 40|10@1+ (0.25,-60) [-60|195.75] "DegC" Vector__XXX
 SG_ DIF_a069_fittedTorqueLimit m69 : 50|13@1- (0.25,0) [-1024|1023.75] "Nm" Vector__XXX
 SG_ DIF_a072_reason m72 : 16|2@1+ (1,0) [0|3] "" Vector__XXX
 SG_ DIF_a073_motorSpeedrpm m73 : 16|16@1- (1,0) [-32768|32767] "RPM" Vector__XXX
 SG_ DIF_a075_motorSpeed m75 : 16|16@1+ (1,0) [0|65535] "RPM" Vector__XXX
 SG_ DIF_a075_absSpeed m75 : 32|16@1+ (1,0) [0|65535] "RPM" Vector__XXX
 SG_ DIF_a076_lvSupplyV m76 : 16|16@1+ (0.001,0) [0|65.535] "V" Vector__XXX
 SG_ DIF_a077_lvSupplyV m77 : 16|16@1+ (0.001,0) [0|65.535] "V" Vector__XXX
 SG_ DIF_a078_adcRefChan m78 : 16|4@1+ (1,0) [0|15] "" Vector__XXX
 SG_ DIF_a078_adcRefLowAvg m78 : 24|16@1+ (1,0) [0|65535] "" Vector__XXX
 SG_ DIF_a079_adcRefChan m79 : 16|4@1+ (1,0) [0|15] "" Vector__XXX
 SG_ DIF_a079_adcRefHighAvg m79 : 24|16@1+ (1,0) [0|65535] "" Vector__XXX
 SG_ DIF_a087_gtwCarConfig m87 : 16|1@1+ (1,0) [0|1] "" Vector__XXX
 SG_ DIF_a087_gtwTime m87 : 17|1@1+ (1,0) [0|1] "" Vector__XXX
 SG_ DIF_a087_gtwUpdateStatus m87 : 18|1@1+ (1,0) [0|1] "" Vector__XXX
 SG_ DIF_a087_gearControl m87 : 19|1@1+ (1,0) [0|1] "" Vector__XXX
 SG_ DIF_a087_carState m87 : 20|1@1+ (1,0) [0|1] "" Vector__XXX
 SG_ DIF_a090_reason m90 : 16|1@1+ (1,0) [0|1] "" Vector__XXX
 SG_ DIF_a090_systemState m90 : 17|1@1+ (1,0) [0|1] "" Vector__XXX
 SG_ DIF_a090_state m90 : 18|1@1+ (1,0) [0|1] "" Vector__XXX
 SG_ DIF_a090_locState m90 : 19|1@1+ (1,0) [0|1] "" Vector__XXX
 SG_ DIF_a090_state2 m90 : 20|1@1+ (1,0) [0|1] "" Vector__XXX
 SG_ DIF_a090_state4 m90 : 21|1@1+ (1,0) [0|1] "" Vector__XXX
 SG_ DIF_a091_ESP_brakeTorque m91 : 16|1@1+ (1,0) [0|1] "" Vector__XXX
 SG_ DIF_a091_ESP_wheelSpeeds m91 : 17|1@1+ (1,0) [0|1] "" Vector__XXX
 SG_ DIF_a091_ESP_wheelRotation m91 : 18|1@1+ (1,0) [0|1] "" Vector__XXX
 SG_ DIF_a091_ESP_motorLimits m91 : 19|1@1+ (1,0) [0|1] "" Vector__XXX
 SG_ DIF_a091_ESP_offsets m91 : 20|1@1+ (1,0) [0|1] "" Vector__XXX
 SG_ DIF_a091_ESP_status m91 : 21|1@1+ (1,0) [0|1] "" Vector__XXX
 SG_ DIF_a091_ESP_party3 m91 : 22|1@1+ (1,0) [0|1] "" Vector__XXX
 SG_ DIF_a092_bmsStatus m92 : 16|1@1+ (1,0) [0|1] "" Vector__XXX
 SG_ DIF_a092_bmsDriveLimits m92 : 17|1@1+ (1,0) [0|1] "" Vector__XXX
 SG_ DIF_a092_bmsHvBusStatus m92 : 18|1@1+ (1,0) [0|1] "" Vector__XXX
 SG_ DIF_a092_bmsPowerAvailable m92 : 19|1@1+ (1,0) [0|1] "" Vector__XXX
 SG_ DIF_a092_bmsBmbMinMax m92 : 20|1@1+ (1,0) [0|1] "" Vector__XXX
 SG_ DIF_a092_bmsSocStatus m92 : 21|1@1+ (1,0) [0|1] "" Vector__XXX
 SG_ DIF_a092_bmsThermalStatus m92 : 22|1@1+ (1,0) [0|1] "" Vector__XXX
 SG_ DIF_a092_bmsCtrStatus m92 : 23|1@1+ (1,0) [0|1] "" Vector__XXX
 SG_ DIF_a092_bmsVoltageRegGain m92 : 24|1@1+ (1,0) [0|1] "" Vector__XXX
 SG_ DIF_a092_bmsPackConfig m92 : 25|1@1+ (1,0) [0|1] "" Vector__XXX
 SG_ DIF_a092_bmsSystemStatus m92 : 26|1@1+ (1,0) [0|1] "" Vector__XXX
 SG_ DIF_a094_canID m94 : 16|12@1+ (1,0) [0|4095] "" Vector__XXX
 SG_ DIF_a094_errorType m94 : 28|3@1+ (1,0) [0|7] "" Vector__XXX
 SG_ DIF_a094_badValue1 m94 : 32|16@1+ (1,0) [0|65535] "" Vector__XXX
 SG_ DIF_a094_badValue2 m94 : 48|16@1+ (1,0) [0|65535] "" Vector__XXX
 SG_ DIF_a096_const_fast m96 : 16|1@1+ (1,0) [0|1] "" Vector__XXX
 SG_ DIF_a096_text_fast m96 : 17|1@1+ (1,0) [0|1] "" Vector__XXX
 SG_ DIF_a096_text_flash m96 : 18|1@1+ (1,0) [0|1] "" Vector__XXX
 SG_ DIF_a096_mem_data m96 : 19|1@1+ (1,0) [0|1] "" Vector__XXX
 SG_ DIF_a096_mem_regs m96 : 20|1@1+ (1,0) [0|1] "" Vector__XXX
 SG_ DIF_a096_boot_flash m96 : 21|1@1+ (1,0) [0|1] "" Vector__XXX
 SG_ DIF_a096_word1 m96 : 24|16@1+ (1,0) [0|65535] "" Vector__XXX
 SG_ DIF_a096_word2 m96 : 40|16@1+ (1,0) [0|65535] "" Vector__XXX
 SG_ DIF_a097_errorType m97 : 16|3@1+ (1,0) [0|7] "" Vector__XXX
 SG_ DIF_a097_lineNumber m97 : 24|16@1+ (1,0) [0|65535] "" Vector__XXX
 SG_ DIF_a097_argument m97 : 40|16@1+ (1,0) [0|65535] "" Vector__XXX
 SG_ DIF_a098_pwmCount m98 : 16|16@1+ (1,0) [0|65535] "" Vector__XXX
 SG_ DIF_a098_fluxState m98 : 32|4@1+ (1,0) [0|15] "" Vector__XXX
 SG_ DIF_a103_fluidTorDeltaT m103 : 16|8@1- (2.007874,68.2677154541) [-188.740156546|323.267713454] "C" Vector__XXX
 SG_ DIF_a103_noFlowDetected m103 : 24|1@1+ (1,0) [0|1] "" Vector__XXX
 SG_ DIF_a103_lowFlowDetected m103 : 25|1@1+ (1,0) [0|1] "" Vector__XXX
 SG_ DIF_a103_fluidImplausible m103 : 26|1@1+ (1,0) [0|1] "" Vector__XXX
 SG_ DIF_a103_inverterTemp m103 : 27|8@1- (2.007874,68.2677154541) [-188.740156546|323.267713454] "C" Vector__XXX
 SG_ DIF_a103_rmsCurrent m103 : 35|10@1- (12.8199605942,0) [-6563.81982423|6550.99986364] "A" Vector__XXX
 SG_ DIF_a103_ambientTemp m103 : 45|7@1- (1.5873016119,11.1111106873) [-90.4761924743|111.111112237] "C" Vector__XXX
 SG_ DIF_a103_sensorTempEst m103 : 52|8@1- (1.25984251499,40.31496) [-120.944881919|200.314959404] "C" Vector__XXX
 SG_ DIF_a107_fpgaVersion m107 : 16|16@1+ (1,0) [0|65535] "" Vector__XXX
 SG_ DIF_a107_fpgaBootVersion m107 : 32|16@1+ (1,0) [0|65535] "" Vector__XXX
 SG_ DIF_a107_fpgaMasterActive m107 : 48|1@1+ (1,0) [0|1] "" Vector__XXX
 SG_ DIF_a107_fpgaFaultActive m107 : 49|1@1+ (1,0) [0|1] "" Vector__XXX
 SG_ DIF_a107_fpgaWarningActive m107 : 50|1@1+ (1,0) [0|1] "" Vector__XXX
 SG_ DIF_a108_fromState m108 : 16|8@1+ (1,0) [0|255] "" Vector__XXX
 SG_ DIF_a108_toState m108 : 24|8@1+ (1,0) [0|255] "" Vector__XXX
 SG_ DIF_a108_blockingAlert m108 : 32|8@1+ (1,0) [0|255] "" Vector__XXX
 SG_ DIF_a110_EPBL_status m110 : 16|1@1+ (1,0) [0|1] "" Vector__XXX
 SG_ DIF_a110_EPBR_status m110 : 17|1@1+ (1,0) [0|1] "" Vector__XXX
 SG_ DIF_a111_phAcalib m111 : 16|16@1+ (1,0) [0|65535] "" Vector__XXX
 SG_ DIF_a111_phBcalib m111 : 32|16@1+ (1,0) [0|65535] "" Vector__XXX
 SG_ DIF_a112_phaseAcurrent m112 : 16|16@1+ (1,0) [0|65535] "A" Vector__XXX
 SG_ DIF_a112_phaseBcurrent m112 : 32|16@1+ (1,0) [0|65535] "A" Vector__XXX
 SG_ DIF_a113_heatsink1Temp m113 : 16|16@1- (0.1,0) [-3276.8|3276.7] "C" Vector__XXX
 SG_ DIF_a113_heatsink2Temp m113 : 32|16@1- (0.1,0) [-3276.8|3276.7] "C" Vector__XXX
 SG_ DIF_a113_heatsink3Temp m113 : 48|16@1- (0.1,0) [-3276.8|3276.7] "C" Vector__XXX
 SG_ DIF_a115_faultAddress m115 : 16|32@1+ (1,0) [0|4294967295] "" Vector__XXX
 SG_ DIF_a115_isWriteNotRead m115 : 48|1@1+ (1,0) [0|1] "" Vector__XXX
 SG_ DIF_a117_torque m117 : 16|1@1+ (1,0) [0|1] "" Vector__XXX
 SG_ DIF_a117_slaveCommand m117 : 17|1@1+ (1,0) [0|1] "" Vector__XXX
 SG_ DIF_a117_power m117 : 18|1@1+ (1,0) [0|1] "" Vector__XXX
 SG_ DIF_a117_slaveCommand2 m117 : 19|1@1+ (1,0) [0|1] "" Vector__XXX
 SG_ DIF_a117_speed m117 : 20|1@1+ (1,0) [0|1] "" Vector__XXX
 SG_ DIF_a117_chassisControl m117 : 21|1@1+ (1,0) [0|1] "" Vector__XXX
 SG_ DIF_a117_systemStatus m117 : 22|1@1+ (1,0) [0|1] "" Vector__XXX
 SG_ DIF_a117_temperature m117 : 23|1@1+ (1,0) [0|1] "" Vector__XXX
 SG_ DIF_a117_vehicle m117 : 24|1@1+ (1,0) [0|1] "" Vector__XXX
 SG_ DIF_a117_AddTcLimit m117 : 26|1@1+ (1,0) [0|1] "" Vector__XXX
 SG_ DIF_a117_dixCommand m117 : 27|1@1+ (1,0) [0|1] "" Vector__XXX
 SG_ DIF_a117_odometerStatus m117 : 30|1@1+ (1,0) [0|1] "" Vector__XXX
 SG_ DIF_a117_maxRatedPower m117 : 31|1@1+ (1,0) [0|1] "" Vector__XXX
 SG_ DIF_a119_hvpFaults m119 : 16|1@1+ (1,0) [0|1] "" Vector__XXX
 SG_ DIF_a120_dcLinkInfo m120 : 16|1@1+ (1,0) [0|1] "" Vector__XXX
 SG_ DIF_a121_badRegReason m121 : 16|3@1+ (1,0) [0|7] "" Vector__XXX
 SG_ DIF_a121_torqueDelta m121 : 19|13@1- (0.25,0) [-1024|1023.75] "Nm" Vector__XXX
 SG_ DIF_a121_badCurrent m121 : 32|16@1- (0.1,0) [-3276.8|3276.7] "A" Vector__XXX
 SG_ DIF_a121_badFlux m121 : 48|16@1+ (0.0001,0) [0|6.5535] "Wb" Vector__XXX
 SG_ DIF_a123_lossReason m123 : 16|3@1+ (1,0) [0|7] "" Vector__XXX
 SG_ DIF_a123_busVoltage m123 : 19|6@1+ (4,250) [250|502] "V" Vector__XXX
 SG_ DIF_a123_badFlux m123 : 25|7@1+ (0.0015,0) [0|0.1905] "Wb" Vector__XXX
 SG_ DIF_a123_lossRequest m123 : 32|7@1+ (0.1,0) [0|12.7] "kW" Vector__XXX
 SG_ DIF_a123_badCurrent m123 : 39|9@1- (10,0) [-2560|2550] "A" Vector__XXX
 SG_ DIF_a123_motorRPM m123 : 48|8@1- (150,0) [-19200|19050] "RPM" Vector__XXX
 SG_ DIF_a123_varianceD m123 : 56|4@1+ (20,0) [0|300] "A" Vector__XXX
 SG_ DIF_a123_varianceQ m123 : 60|4@1+ (20,0) [0|300] "A" Vector__XXX
 SG_ DIF_a126_limpReason m126 : 16|6@1+ (1,0) [0|63] "" Vector__XXX
 SG_ DIF_a127_gpoReason m127 : 16|4@1+ (1,0) [0|15] "" Vector__XXX
 SG_ DIF_a127_temp m127 : 24|16@1- (0.1,0) [-3276.8|3276.7] "C" Vector__XXX
 SG_ DIF_a133_capacitorTemp m133 : 16|16@1- (0.1,0) [-3276.8|3276.7] "C" Vector__XXX
 SG_ DIF_a133_badValue1 m133 : 32|16@1- (0.1,0) [-3276.8|3276.7] "C" Vector__XXX
 SG_ DIF_a133_badValue2 m133 : 48|16@1- (0.1,0) [-3276.8|3276.7] "C" Vector__XXX
 SG_ DIF_a134_wheelSpeedDiffFrL m134 : 16|12@1- (0.0625,0) [-128|127.9375] "kph" Vector__XXX
 SG_ DIF_a134_wheelSpeedDiffFrR m134 : 28|12@1- (0.0625,0) [-128|127.9375] "kph" Vector__XXX
 SG_ DIF_a134_wheelSpeedDiffReL m134 : 40|12@1- (0.0625,0) [-128|127.9375] "kph" Vector__XXX
 SG_ DIF_a134_wheelSpeedDiffReR m134 : 52|12@1- (0.0625,0) [-128|127.9375] "kph" Vector__XXX
 SG_ DIF_a136_spiError_BL m136 : 16|1@1+ (1,0) [0|1] "" Vector__XXX
 SG_ DIF_a136_crcError_BL m136 : 17|1@1+ (1,0) [0|1] "" Vector__XXX
 SG_ DIF_a136_busyError_BL m136 : 18|1@1+ (1,0) [0|1] "" Vector__XXX
 SG_ DIF_a136_spiError_BH m136 : 19|1@1+ (1,0) [0|1] "" Vector__XXX
 SG_ DIF_a136_crcError_BH m136 : 20|1@1+ (1,0) [0|1] "" Vector__XXX
 SG_ DIF_a136_busyError_BH m136 : 21|1@1+ (1,0) [0|1] "" Vector__XXX
 SG_ DIF_a136_spiError_CL m136 : 22|1@1+ (1,0) [0|1] "" Vector__XXX
 SG_ DIF_a136_crcError_CL m136 : 23|1@1+ (1,0) [0|1] "" Vector__XXX
 SG_ DIF_a136_busyError_CL m136 : 24|1@1+ (1,0) [0|1] "" Vector__XXX
 SG_ DIF_a136_spiError_CH m136 : 25|1@1+ (1,0) [0|1] "" Vector__XXX
 SG_ DIF_a136_crcError_CH m136 : 26|1@1+ (1,0) [0|1] "" Vector__XXX
 SG_ DIF_a136_busyError_CH m136 : 27|1@1+ (1,0) [0|1] "" Vector__XXX
 SG_ DIF_a136_spiError_AL m136 : 28|1@1+ (1,0) [0|1] "" Vector__XXX
 SG_ DIF_a136_crcError_AL m136 : 29|1@1+ (1,0) [0|1] "" Vector__XXX
 SG_ DIF_a136_busyError_AL m136 : 30|1@1+ (1,0) [0|1] "" Vector__XXX
 SG_ DIF_a136_spiError_AH m136 : 31|1@1+ (1,0) [0|1] "" Vector__XXX
 SG_ DIF_a136_crcError_AH m136 : 32|1@1+ (1,0) [0|1] "" Vector__XXX
 SG_ DIF_a136_busyError_AH m136 : 33|1@1+ (1,0) [0|1] "" Vector__XXX
 SG_ DIF_a144_autopilot m144 : 16|1@1+ (1,0) [0|1] "" Vector__XXX
 SG_ DIF_a144_chassisType m144 : 17|1@1+ (1,0) [0|1] "" Vector__XXX
 SG_ DIF_a144_drivetrainType m144 : 18|1@1+ (1,0) [0|1] "" Vector__XXX
 SG_ DIF_a144_packEnergy m144 : 19|1@1+ (1,0) [0|1] "" Vector__XXX
 SG_ DIF_a144_packPerformanceDeviatio m144 : 20|1@1+ (1,0) [0|1] "" Vector__XXX
 SG_ DIF_a144_performancePackage m144 : 21|1@1+ (1,0) [0|1] "" Vector__XXX
 SG_ DIF_a144_vdcType m144 : 22|1@1+ (1,0) [0|1] "" Vector__XXX
 SG_ DIF_a144_brakeHWType m144 : 23|1@1+ (1,0) [0|1] "" Vector__XXX
 SG_ DIF_a144_inverterHardware m144 : 24|1@1+ (1,0) [0|1] "" Vector__XXX
 SG_ DIF_a144_cabinPTCHeaterType m144 : 25|1@1+ (1,0) [0|1] "" Vector__XXX
 SG_ DIF_a144_frunkLatchType m144 : 26|1@1+ (1,0) [0|1] "" Vector__XXX
 SG_ DIF_a144_platformMaxBusVoltage m144 : 27|1@1+ (1,0) [0|1] "" Vector__XXX
 SG_ DIF_a144_oilPump1HwType m144 : 28|1@1+ (1,0) [0|1] "" Vector__XXX
 SG_ DIF_a144_oilPump2HwType m144 : 29|1@1+ (1,0) [0|1] "" Vector__XXX
 SG_ DIF_a144_heatsinkType m144 : 30|1@1+ (1,0) [0|1] "" Vector__XXX
 SG_ DIF_a144_softPerformanceLimit m144 : 31|1@1+ (1,0) [0|1] "" Vector__XXX
 SG_ DIF_a144_brakeActuationType m144 : 32|1@1+ (1,0) [0|1] "" Vector__XXX
 SG_ DIF_a144_dasHw m144 : 33|1@1+ (1,0) [0|1] "" Vector__XXX
 SG_ DIF_a144_chassisSubType m144 : 34|1@1+ (1,0) [0|1] "" Vector__XXX
 SG_ DIF_a147_overtorque1UsedCount m147 : 16|8@1+ (1,0) [0|255] "" Vector__XXX
 SG_ DIF_a147_overtorque2UsedCount m147 : 24|10@1+ (1,0) [0|1023] "" Vector__XXX
 SG_ DIF_a147_accumulatedWear m147 : 34|10@1+ (0.005,0) [0|5.115] "1" Vector__XXX
 SG_ DIF_a147_wearIsValid m147 : 44|1@1+ (1,0) [0|1] "" Vector__XXX
 SG_ DIF_a149_flow m149 : 16|8@1+ (0.1,0) [0|25.4] "LPM" Vector__XXX
 SG_ DIF_a149_voltage m149 : 24|8@1+ (0.1,0) [0|25.5] "V" Vector__XXX
 SG_ DIF_a149_temperature m149 : 32|8@1+ (1,-40) [-40|215] "DegC" Vector__XXX
 SG_ DIF_a149_state m149 : 40|3@1+ (1,0) [0|6] "" Vector__XXX
 SG_ DIF_a149_fluidTempSNA m149 : 43|1@1+ (1,0) [0|1] "" Vector__XXX
 SG_ DIF_a149_insufficientFlow m149 : 44|1@1+ (1,0) [0|1] "" Vector__XXX
 SG_ DIF_a149_motorOpenPhase m149 : 45|1@1+ (1,0) [0|1] "" Vector__XXX
 SG_ DIF_a149_motorShorted m149 : 46|1@1+ (1,0) [0|1] "" Vector__XXX
 SG_ DIF_a149_motorFlowSNA m149 : 47|1@1+ (1,0) [0|1] "" Vector__XXX
 SG_ DIF_a149_responseError m149 : 48|1@1+ (1,0) [0|1] "" Vector__XXX
 SG_ DIF_a149_pcbaID m149 : 49|1@1+ (1,0) [0|1] "" Vector__XXX
 SG_ DIF_a150_vBatRawMinusFiltered m150 : 16|10@1- (1,0) [-512|511] "V" Vector__XXX
 SG_ DIF_a150_vBatFilteredRate m150 : 32|8@1- (100,0) [-12800|12700] "V/s" Vector__XXX
 SG_ DIF_a150_elapsedMs m150 : 40|8@1+ (1,0) [0|255] "ms" Vector__XXX
 SG_ DIF_a150_energy m150 : 48|16@1+ (1,0) [0|65535] "J" Vector__XXX
 SG_ DIF_a152_errorType m152 : 16|3@1+ (1,0) [0|7] "" Vector__XXX
 SG_ DIF_a152_frameId m152 : 24|8@1+ (1,0) [0|255] "" Vector__XXX
 SG_ DIF_a152_badValue m152 : 32|8@1+ (1,0) [0|255] "" Vector__XXX
 SG_ DIF_a152_expectedValue m152 : 40|8@1+ (1,0) [0|255] "" Vector__XXX
 SG_ DIF_a153_oilFlow m153 : 16|8@1+ (0.1,0) [0|25.4] "LPM" Vector__XXX
 SG_ DIF_a153_oilTemperature m153 : 24|8@1+ (1,-40) [-40|214] "DegC" Vector__XXX
 SG_ DIF_a153_phaseCurrent m153 : 32|8@1+ (0.1,0) [0|25.4] "A" Vector__XXX
 SG_ DIF_a153_dcVoltage m153 : 40|8@1+ (0.3,0) [0|76.2] "V" Vector__XXX
 SG_ DIF_a153_lowPressPlausibility m153 : 48|5@1+ (3.3,0) [0|102.3] "%" Vector__XXX
 SG_ DIF_a153_state m153 : 53|3@1+ (1,0) [0|6] "" Vector__XXX
 SG_ DIF_a153_oilPumpAlert m153 : 56|5@1+ (1,0) [0|31] "" Vector__XXX
 SG_ DIF_a153_reason m153 : 61|3@1+ (1,0) [0|7] "" Vector__XXX
 SG_ DIF_a154_motorRPM m154 : 16|16@1- (1,0) [-32768|32767] "RPM" Vector__XXX
 SG_ DIF_a154_phaseError m154 : 32|8@1- (0.004,0) [-0.512|0.508] "1" Vector__XXX
 SG_ DIF_a154_commonGain m154 : 40|8@1+ (0.02,0) [0|5.1] "1" Vector__XXX
 SG_ DIF_a154_noCalibration m154 : 48|1@1+ (1,0) [0|1] "" Vector__XXX
 SG_ DIF_a154_noPhaseLock m154 : 49|1@1+ (1,0) [0|1] "" Vector__XXX
 SG_ DIF_a154_noCarrier m154 : 50|1@1+ (1,0) [0|1] "" Vector__XXX
 SG_ DIF_a154_notReady m154 : 51|1@1+ (1,0) [0|1] "" Vector__XXX
 SG_ DIF_a154_errorTableInvalid m154 : 52|1@1+ (1,0) [0|1] "" Vector__XXX
 SG_ DIF_a154_carrierOffset m154 : 53|1@1+ (1,0) [0|1] "" Vector__XXX
 SG_ DIF_a154_trackerIrrational m154 : 54|1@1+ (1,0) [0|1] "" Vector__XXX
 SG_ DIF_a154_claMIA m154 : 55|1@1+ (1,0) [0|1] "" Vector__XXX
 SG_ DIF_a155_sensors m155 : 16|1@1+ (1,0) [0|1] "" Vector__XXX
 SG_ DIF_a155_coolant m155 : 17|1@1+ (1,0) [0|1] "" Vector__XXX
 SG_ DIF_a155_LVPowerState m155 : 18|1@1+ (1,0) [0|1] "" Vector__XXX
 SG_ DIF_a155_vehicleStatus m155 : 19|1@1+ (1,0) [0|1] "" Vector__XXX
 SG_ DIF_a155_status m155 : 20|1@1+ (1,0) [0|1] "" Vector__XXX
 SG_ DIF_a155_leftDoorStatus m155 : 21|1@1+ (1,0) [0|1] "" Vector__XXX
 SG_ DIF_a155_rightDoorStatus m155 : 22|1@1+ (1,0) [0|1] "" Vector__XXX
 SG_ DIF_a155_vcleftSwitchStatus m155 : 23|1@1+ (1,0) [0|1] "" Vector__XXX
 SG_ DIF_a155_restraintStatus m155 : 24|1@1+ (1,0) [0|1] "" Vector__XXX
 SG_ DIF_a155_systemStatus m155 : 25|1@1+ (1,0) [0|1] "" Vector__XXX
 SG_ DIF_a155_prndStatus m155 : 26|1@1+ (1,0) [0|1] "" Vector__XXX
 SG_ DIF_a155_liftgateStatus m155 : 27|1@1+ (1,0) [0|1] "" Vector__XXX
 SG_ DIF_a157_RCM_inertial1 m157 : 16|1@1+ (1,0) [0|1] "" Vector__XXX
 SG_ DIF_a157_RCM_inertial2 m157 : 17|1@1+ (1,0) [0|1] "" Vector__XXX
 SG_ DIF_a158_IBST_party1 m158 : 16|1@1+ (1,0) [0|1] "" Vector__XXX
 SG_ DIF_a158_BUS1_IBST_status m158 : 17|1@1+ (1,0) [0|1] "" Vector__XXX
 SG_ DIF_a158_BUS2_IBST_status m158 : 18|1@1+ (1,0) [0|1] "" Vector__XXX
 SG_ DIF_a160_vBatRawMinusFiltered m160 : 16|10@1- (1,0) [-512|511] "V" Vector__XXX
 SG_ DIF_a160_vBatFilteredRate m160 : 32|8@1- (100,0) [-12800|12700] "V/s" Vector__XXX
 SG_ DIF_a160_elapsedMs m160 : 40|8@1+ (1,0) [0|255] "ms" Vector__XXX
 SG_ DIF_a160_energy m160 : 48|16@1+ (1,0) [0|65535] "J" Vector__XXX
 SG_ DIF_a161_EPAS3P_sysStatus m161 : 16|1@1+ (1,0) [0|1] "" Vector__XXX
 SG_ DIF_a161_EPAS3P_angleCalib m161 : 17|1@1+ (1,0) [0|1] "" Vector__XXX
 SG_ DIF_a202_reason m202 : 16|4@1+ (1,0) [0|15] "" Vector__XXX
 SG_ DIF_a202_movement m202 : 20|9@1+ (0.005,0) [0|2.555] "m" Vector__XXX
 SG_ DIF_a202_sysStateExitCondition m202 : 32|5@1+ (1,0) [0|31] "" Vector__XXX
 SG_ DIF_a233_missedMsgCount m233 : 16|4@1+ (1,0) [0|15] "" Vector__XXX
 SG_ DIF_a233_serviceModeActive m233 : 20|1@1+ (1,0) [0|1] "" Vector__XXX
 SG_ DIF_a234_PCS_dcdcStatus m234 : 16|1@1+ (1,0) [0|1] "" Vector__XXX
 SG_ DIF_a236_states m236 : 16|1@1+ (1,0) [0|1] "" Vector__XXX
 SG_ DIF_a242_RotorOffset m242 : 16|1@1+ (1,0) [0|1] "" Vector__XXX
 SG_ DIF_a242_RotorFlux m242 : 17|1@1+ (1,0) [0|1] "" Vector__XXX
 SG_ DIF_a242_ResolverError m242 : 18|1@1+ (1,0) [0|1] "" Vector__XXX
 SG_ DIF_a244_desatHighSide m244 : 16|1@1+ (1,0) [0|1] "" Vector__XXX
 SG_ DIF_a244_desatLowSide m244 : 17|1@1+ (1,0) [0|1] "" Vector__XXX
 SG_ DIF_a244_singleSwitchShort m244 : 18|1@1+ (1,0) [0|1] "" Vector__XXX
 SG_ DIF_a244_flybackFault m244 : 19|1@1+ (1,0) [0|1] "" Vector__XXX
 SG_ DIF_a244_postShortTestFailed m244 : 20|1@1+ (1,0) [0|1] "" Vector__XXX
 SG_ DIF_a244_udsSelfTest m244 : 21|1@1+ (1,0) [0|1] "" Vector__XXX
 SG_ DIF_a244_irSensorV m244 : 24|6@1+ (0.1,0) [0|6.3] "V" Vector__XXX
 SG_ DIF_a244_gateDriveICUndervoltage m244 : 30|1@1+ (1,0) [0|1] "" Vector__XXX
 SG_ DIF_a244_plausibleSingleSwitchSh m244 : 31|1@1+ (1,0) [0|1] "" Vector__XXX
 SG_ DIF_a246_atSpeedDIResetCount m246 : 16|4@1+ (1,4294967295) [4294967295|4294967310] "" Vector__XXX
 SG_ DIF_a246_didPMCauseASC m246 : 20|1@1+ (1,0) [0|1] "" Vector__XXX
 SG_ DIF_a246_currentSensorRational m246 : 21|1@1+ (1,0) [0|1] "" Vector__XXX
 SG_ DIF_a246_observerDetectedLS3PS m246 : 22|1@1+ (1,0) [0|1] "" Vector__XXX
 SG_ DIF_a246_hvIsGood m246 : 23|1@1+ (1,0) [0|1] "" Vector__XXX
 SG_ DIF_a246_lvIsGood m246 : 24|1@1+ (1,0) [0|1] "" Vector__XXX
 SG_ DIF_a246_codeBranch m246 : 25|2@1+ (1,0) [0|3] "" Vector__XXX
 SG_ DIF_a246_motorRPM m246 : 32|8@1- (150,0) [-19200|19050] "RPM" Vector__XXX
 SG_ DIF_a246_eepromOffsetIa m246 : 40|6@1- (0.763,0) [-24.416|23.653] "A" Vector__XXX
 SG_ DIF_a246_eepromOffsetIb m246 : 48|6@1- (0.763,0) [-24.416|23.653] "A" Vector__XXX
 SG_ DIF_a247_rotorOffsetEst m247 : 16|10@1- (0.05,0) [-25.6|25.55] "degrees" Vector__XXX
 SG_ DIF_a247_motorRPM m247 : 32|16@1- (1,0) [-32768|32767] "RPM" Vector__XXX
 SG_ DIF_a247_torqueMotor m247 : 48|16@1- (1,0) [-32768|32767] "Nm" Vector__XXX
 SG_ DIF_a251_oilFlow m251 : 16|8@1+ (0.1,0) [0|25.4] "LPM" Vector__XXX
 SG_ DIF_a251_oilTemperature m251 : 24|8@1+ (1,-40) [-40|214] "DegC" Vector__XXX
 SG_ DIF_a251_dcVoltage m251 : 32|8@1+ (0.3,0) [0|76.2] "V" Vector__XXX
 SG_ DIF_a251_dcCurrent m251 : 40|8@1+ (0.1,0) [0|25.4] "A" Vector__XXX
 SG_ DIF_a251_phaseCurrent m251 : 48|8@1+ (0.1,0) [0|25.4] "A" Vector__XXX
 SG_ DIF_a251_leadAngle m251 : 56|4@1+ (1.875,0) [0|28.125] "degrees" Vector__XXX
 SG_ DIF_a251_reason m251 : 60|3@1+ (1,0) [0|7] "" Vector__XXX

BO_ 634 DIF_hvStatus: 7 DIF
 SG_ DIF_hvStatusChecksum : 0|8@1+ (1,0) [0|255] "" Vector__XXX
 SG_ DIF_hvStatusCounter : 8|4@1+ (1,0) [0|15] "" Vector__XXX
 SG_ DIF_hvilCurrent : 12|8@1+ (0.1,0) [0|25.5] "mA" Vector__XXX
 SG_ DIF_hvilCmVoltage : 20|8@1+ (0.08,0) [0|20.4] "V" Vector__XXX
 SG_ DIF_hvilStatus : 28|2@1+ (1,0) [0|2] "" Vector__XXX
 SG_ DIF_hvilSupplyState : 30|2@1+ (1,0) [0|3] "" Vector__XXX
 SG_ DIF_activeDischargeCtrl : 32|1@1+ (1,0) [0|1] "" Vector__XXX
 SG_ DIF_activeDischargeStatus : 33|1@1+ (1,0) [0|1] "" Vector__XXX
 SG_ DIF_vBat : 34|10@1+ (1,0) [0|1023] "V" Vector__XXX
 SG_ DIF_vBatQF : 44|1@1+ (1,0) [0|1] "" Vector__XXX
 SG_ DIF_powerStageSafeState : 45|2@1+ (1,0) [0|3] "" Vector__XXX
 SG_ DIF_fluxState : 48|4@1+ (1,0) [0|15] "" Vector__XXX
 SG_ DIF_vBusDiag : 52|1@1+ (1,0) [0|1] "" Vector__XXX
 SG_ DIF_gateDriveState : 53|3@1+ (1,0) [0|7] "" Vector__XXX

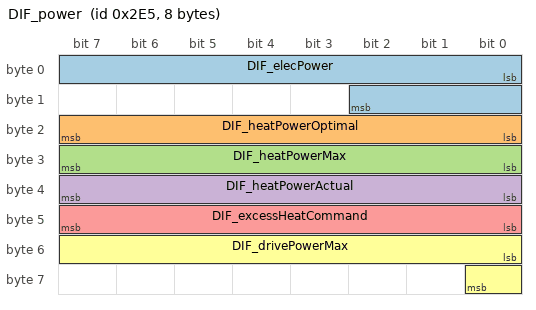
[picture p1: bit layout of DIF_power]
BO_ 741 DIF_power: 8 DIF
 SG_ DIF_elecPower : 0|11@1- (0.5,0) [-500|500] "kW" Vector__XXX
 SG_ DIF_heatPowerOptimal : 16|8@1+ (0.08,0) [0|20] "kW" Vector__XXX
 SG_ DIF_heatPowerMax : 24|8@1+ (0.08,0) [0|20] "kW" Vector__XXX
 SG_ DIF_heatPowerActual : 32|8@1+ (0.08,0) [0|20] "kW" Vector__XXX
 SG_ DIF_excessHeatCommand : 40|8@1+ (0.08,0) [0|20] "kW" Vector__XXX
 SG_ DIF_drivePowerMax : 48|9@1+ (1,0) [0|400] "kW" Vector__XXX

BO_TX_BU_ 798 : CP;
BO_TX_BU_ 669 : CP;
BO_TX_BU_ 541 : CP;
BO_TX_BU_ 1342 : CP;
BO_TX_BU_ 1885 : CP;
BO_TX_BU_ 989 : CP;
BO_TX_BU_ 605 : CP;
BO_TX_BU_ 893 : CP;
BO_TX_BU_ 1001 : DAS;
BO_TX_BU_ 1318 : DIF;
BO_TX_BU_ 634 : DIF;
BO_TX_BU_ 741 : DIF;
CM_ BO_ 798 "Charge port controller message: alert matrix";
CM_ SG_ 798 CP_matrixIndex "Charge port controller: matrix index";
CM_ SG_ 798 CP_a001_canRx "Charge port controller: a001 can rx";
CM_ SG_ 798 CP_a002_canTx "Charge port controller: a002 can tx";
CM_ SG_ 798 CP_a003_canError "Charge port controller: a003 can error";
CM_ SG_ 798 CP_a004_proximityRationality "Charge port controller: a004 proximity rationality";
CM_ SG_ 798 CP_a005_gbdcLiveDisconnect "Charge port controller: a005 gbdc live disconnect";
CM_ SG_ 798 CP_a006_lostCommsBMS "Charge port controller: a006 lost comms BMS";
CM_ SG_ 798 CP_a007_watchdog "Charge port controller: a007 watchdog";
CM_ SG_ 798 CP_a008_memoryError "Charge port controller: a008 memory error";
CM_ SG_ 798 CP_a009_coverOpenAllChgBlocked "Charge port controller: a009 cover open all chg blocked";
CM_ SG_ 798 CP_a010_pilotRationality "Charge port controller: a010 pilot rationality";
CM_ SG_ 798 CP_a011_eeprom "Charge port controller: a011 eeprom";
CM_ SG_ 798 CP_a012_ledDriver "Charge port controller: a012 led driver";
CM_ SG_ 798 CP_a013_lostCommsGTW "Charge port controller: a013 lost comms GTW";
CM_ SG_ 798 CP_a014_lostCommsCHG "Charge port controller: a014 lost comms CHG";
CM_ SG_ 798 CP_a015_apsVov "Charge port controller: a015 aps vov";
CM_ SG_ 798 CP_a016_apsVuv "Charge port controller: a016 aps vuv";
CM_ SG_ 798 CP_a017_fiveVov "Charge port controller: a017 five vov";
CM_ SG_ 798 CP_a018_fiveVuv "Charge port controller: a018 five vuv";
CM_ SG_ 798 CP_a019_threeVov "Charge port controller: a019 three vov";
CM_ SG_ 798 CP_a020_threeVuv "Charge port controller: a020 three vuv";
CM_ SG_ 798 CP_a021_zeroVov "Charge port controller: a021 zero vov";
CM_ SG_ 798 CP_a022_zeroVuv "Charge port controller: a022 zero vuv";
CM_ SG_ 798 CP_a023_gbdcSessionFailed "Charge port controller: a023 gbdc session failed";
CM_ SG_ 798 CP_a024_ledsUC "Charge port controller: a024 leds UC";
CM_ SG_ 798 CP_a025_ledsOC "Charge port controller: a025 leds OC";
CM_ SG_ 798 CP_a026_networkManagement "Charge port controller: a026 network management";
CM_ SG_ 798 CP_a027_doorSensorOutOfSpec "Charge port controller: a027 door sensor out of spec";
CM_ SG_ 798 CP_a028_insertEnableMismatch "Charge port controller: a028 insert enable mismatch";
CM_ SG_ 798 CP_a029_doorClosedProxPilot "Charge port controller: a029 door closed prox pilot";
CM_ SG_ 798 CP_a030_busOff "Charge port controller: a030 bus off";
CM_ SG_ 798 CP_a031_doorClosedCommandedOpen "Charge port controller: a031 door closed commanded open";
CM_ SG_ 798 CP_a032_doorOpenExpectedClosed "Charge port controller: a032 door open expected closed";
CM_ SG_ 798 CP_a033_spiOpen "Charge port controller: a033 spi open";
CM_ SG_ 798 CP_a034_calibrationIncomplete "Charge port controller: a034 calibration incomplete";
CM_ SG_ 798 CP_a035_latchMovement_1 "Charge port controller: a035 latch movement 1";
CM_ SG_ 798 CP_a036_latchNotDisengaged "Charge port controller: a036 latch not disengaged";
CM_ SG_ 798 CP_a037_latchNotEngaged "Charge port controller: a037 latch not engaged";
CM_ SG_ 798 CP_a038_latchNotBlocking "Charge port controller: a038 latch not blocking";
CM_ SG_ 798 CP_a039_latchMovement_2 "Charge port controller: a039 latch movement 2";
CM_ SG_ 798 CP_a040_doNotUse "Charge port controller: a040 do not use";
CM_ SG_ 798 CP_a041_doorSensorUnplugged "Charge port controller: a041 door sensor unplugged";
CM_ SG_ 798 CP_a042_doorAssemblyBroken "Charge port controller: a042 door assembly broken";
CM_ SG_ 798 CP_a043_doorPotIrrational "Charge port controller: a043 door pot irrational";
CM_ SG_ 798 CP_a044_lostCommsHVP "Charge port controller: a044 lost comms HVP";
CM_ SG_ 798 CP_a045_lostCommsVCSEC "Charge port controller: a045 lost comms VCSEC";
CM_ SG_ 798 CP_a046_lostCommsEVSE "Charge port controller: a046 lost comms EVSE";
CM_ SG_ 798 CP_a047_lostCommsVCFRONT "Charge port controller: a047 lost comms VCFRONT";
CM_ SG_ 798 CP_a048_lostCommsUI "Charge port controller: a048 lost comms UI";
CM_ SG_ 798 CP_a049_multipleCablesDetected "Charge port controller: a049 multiple cables detected";
CM_ SG_ 798 CP_a050_latchNotConnected "Charge port controller: a050 latch not connected";
CM_ SG_ 798 CP_a051_doorInductiveSensorMIA "Charge port controller: a051 door inductive sensor MIA";
CM_ SG_ 798 CP_a052_chademoNotSupported "Charge port controller: a052 chademo not supported";
CM_ SG_ 798 CP_a053_proxLatchedNoPilot "Charge port controller: a053 prox latched no pilot";
CM_ SG_ 798 CP_a054_cableNotSecured "Charge port controller: a054 cable not secured";
CM_ SG_ 798 CP_a055_chargeStoppedNoPilot "Charge port controller: a055 charge stopped no pilot";
CM_ SG_ 798 CP_a056_proxDisconnected "Charge port controller: a056 prox disconnected";
CM_ SG_ 798 CP_a057_ccs1AdapterBtnPress "Charge port controller: a057 ccs1 adapter btn press";
CM_ SG_ 798 CP_a058_acChargeRetryPending "Charge port controller: a058 ac charge retry pending";
CM_ SG_ 798 CP_a059_swcanError "Charge port controller: a059 swcan error";
CM_ SG_ 798 CP_a060_lostCommsPCS "Charge port controller: a060 lost comms PCS";
CM_ SG_ 798 CP_a061_uhfReceiverMIA "Charge port controller: a061 uhf receiver MIA";
CM_ SG_ 798 CP_a062_scOutOfService "Charge port controller: a062 sc out of service";
CM_ SG_ 798 CP_a063_scUpdateInProgress "Charge port controller: a063 sc update in progress";
CM_ SG_ 798 CP_a064_superchargingBlocked "Charge port controller: a064 supercharging blocked";
CM_ SG_ 798 CP_a065_selfTestFailed "Charge port controller: a065 self test failed";
CM_ SG_ 798 CP_a066_proxLatchedIdlePilot "Charge port controller: a066 prox latched idle pilot";
CM_ SG_ 798 CP_a067_gbdcConnFault "Charge port controller: a067 gbdc conn fault";
CM_ SG_ 798 CP_a068_doorSensorMismatch "Charge port controller: a068 door sensor mismatch";
CM_ SG_ 798 CP_a069_doorInductiveSensorError "Charge port controller: a069 door inductive sensor error";
CM_ SG_ 798 CP_a070_doorInductiveSensorReset "Charge port controller: a070 door inductive sensor reset";
CM_ SG_ 798 CP_a071_exiDecodeFailure "Charge port controller: a071 exi decode failure";
CM_ SG_ 798 CP_a072_v2gEvccTimeout "Charge port controller: a072 v2g evcc timeout";
CM_ SG_ 798 CP_a073_iecComboShutdown "Charge port controller: a073 iec combo shutdown";
CM_ SG_ 798 CP_a074_failedToEstablishV2gComm "Charge port controller: a074 failed to establish v2g comm";
CM_ SG_ 798 CP_a075_v2gCommsFailure "Charge port controller: a075 v2g comms failure";
CM_ SG_ 798 CP_a076_LDC1612errorWatchdog "Charge port controller: a076 ldc1612error watchdog";
CM_ SG_ 798 CP_a077_invalidMacAddress "Charge port controller: a077 invalid mac address";
CM_ SG_ 798 CP_a078_latchNotDisengagedCold "Charge port controller: a078 latch not disengaged cold";
CM_ SG_ 798 CP_a079_cableNotSecuredCold "Charge port controller: a079 cable not secured cold";
CM_ SG_ 798 CP_a080_taskStackOverflow "Charge port controller: a080 task stack overflow";
CM_ SG_ 798 CP_a081_swException "Charge port controller: a081 sw exception";
CM_ SG_ 798 CP_a082_powerOnReset "Charge port controller: a082 power on reset";
CM_ SG_ 798 CP_a083_watchdogTraceData "Charge port controller: a083 watchdog trace data";
CM_ SG_ 798 CP_a084_proxPeDisconnected_gb "Charge port controller: a084 prox pe disconnected gb";
CM_ SG_ 798 CP_a085_dcPinTempFaulted "Charge port controller: a085 dc pin temp faulted";
CM_ SG_ 798 CP_a086_dcPinTempIrrational "Charge port controller: a086 dc pin temp irrational";
CM_ SG_ 798 CP_a087_dcTempModelFault "Charge port controller: a087 dc temp model fault";
CM_ SG_ 798 CP_a088_dcTempModelDeviation "Charge port controller: a088 dc temp model deviation";
CM_ SG_ 798 CP_a089_plcConfigMismatch "Charge port controller: a089 plc config mismatch";
CM_ SG_ 798 CP_a090_ccsEvseLowIso "Charge port controller: a090 ccs evse low iso";
CM_ SG_ 798 CP_a091_wrongSuperchargerHandle "Charge port controller: a091 wrong supercharger handle";
CM_ SG_ 798 CP_a092_modemAppLoadFailed "Charge port controller: a092 modem app load failed";
CM_ SG_ 798 CP_a093_modemLoadedWithReset "Charge port controller: a093 modem loaded with reset";
CM_ SG_ 798 CP_a094_inductiveResetSuccessful "Charge port controller: a094 inductive reset successful";
CM_ SG_ 798 CP_a095_thermalDcLimitActive "Charge port controller: a095 thermal dc limit active";
CM_ SG_ 798 CP_a096_pilotWake "Charge port controller: a096 pilot wake";
CM_ SG_ 798 CP_a097_modeTransitionFailure "Charge port controller: a097 mode transition failure";
CM_ SG_ 798 CP_a098_proximityWake "Charge port controller: a098 proximity wake";
CM_ SG_ 798 CP_a099_cableStateUnknown "Charge port controller: a099 cable state unknown";
CM_ SG_ 798 CP_a100_inletHarnessIdIrrational "Charge port controller: a100 inlet harness id irrational";
CM_ SG_ 798 CP_a101_wcFoldbackActive "Charge port controller: a101 wc foldback active";
CM_ SG_ 798 CP_a102_wcOvertempFault "Charge port controller: a102 wc overtemp fault";
CM_ SG_ 798 CP_a103_proximityPeDisconnected "Charge port controller: a103 proximity pe disconnected";
CM_ SG_ 798 CP_a104_uhfResetSuccessful "Charge port controller: a104 uhf reset successful";
CM_ SG_ 798 CP_a105_hwUnableToSleep "Charge port controller: a105 hw unable to sleep";
CM_ SG_ 798 CP_a106_uhfReceiverReset "Charge port controller: a106 uhf receiver reset";
CM_ SG_ 798 CP_a107_chademoFoldbackActive "Charge port controller: a107 chademo foldback active";
CM_ SG_ 798 CP_a108_chademoOvertempFault "Charge port controller: a108 chademo overtemp fault";
CM_ SG_ 798 CP_a109_thermistorIrrational "Charge port controller: a109 thermistor irrational";
CM_ SG_ 798 CP_a110_thermalVelocityHigh "Charge port controller: a110 thermal velocity high";
CM_ SG_ 798 CP_a111_inletHeaterUnableToHeat "Charge port controller: a111 inlet heater unable to heat";
CM_ SG_ 798 CP_a112_inletHeaterIrrationalTem "Charge port controller: a112 inlet heater irrational temperature";
CM_ SG_ 798 CP_a113_inletHeaterShortCircuit "Charge port controller: a113 inlet heater short circuit";
CM_ SG_ 798 CP_a114_ccsEvseFailed "Charge port controller: a114 ccs evse failed";
CM_ SG_ 798 CP_a115_unexpectedTcan1145State "Charge port controller: a115 unexpected tcan1145 state";
CM_ SG_ 798 CP_a116_misconfigurationDetected "Charge port controller: a116 misconfiguration detected";
CM_ SG_ 798 CP_a117_inletHeaterUnableToRegul "Charge port controller: a117 inlet heater unable to regulate";
CM_ SG_ 798 CP_a118_iecComboLockUp "Charge port controller: a118 iec combo lock up";
CM_ SG_ 798 CP_a119_plcTransmitFailure "Charge port controller: a119 plc transmit failure";
CM_ SG_ 798 CP_a120_comboAdapterFoldback "Charge port controller: a120 combo adapter foldback";
CM_ SG_ 798 CP_a121_PLCRLY_lostCommsCP "Charge port controller: a121 PLCRLY lost comms CP";
CM_ SG_ 798 CP_a122_plcModemFailure "Charge port controller: a122 plc modem failure";
CM_ SG_ 798 CP_a123_latchPotIrrational "Charge port controller: a123 latch pot irrational";
CM_ SG_ 798 CP_a124_ivledFault "Charge port controller: a124 ivled fault";
CM_ SG_ 798 CP_a125_unexpectedLVJuiceState "Charge port controller: a125 unexpected LV juice state";
CM_ SG_ 798 CP_a126_wakeOnUhfFault "Charge port controller: a126 wake on uhf fault";
CM_ SG_ 798 CP_a127_lostCommsHVLINK "Charge port controller: a127 lost comms HVLINK";
CM_ SG_ 798 CP_a128_lostCommsVC "Charge port controller: a128 lost comms VC";
CM_ SG_ 798 CP_a129_bldcDriverCommsFailed "Charge port controller: a129 bldc driver comms failed";
CM_ SG_ 798 CP_a130_bldcDriverCommsRecovered "Charge port controller: a130 bldc driver comms recovered";
CM_ SG_ 798 CP_a131_evseCommTimeout "Charge port controller: a131 evse comm timeout";
CM_ SG_ 798 CP_a132_contractAuthTimeout "Charge port controller: a132 contract auth timeout";
CM_ SG_ 798 CP_a133_proxNeverLatched "Charge port controller: a133 prox never latched";
CM_ SG_ 798 CP_a134_plcModemNotExpected "Charge port controller: a134 plc modem not expected";
CM_ SG_ 798 CP_a135_sdpAttemptsFailed "Charge port controller: a135 sdp attempts failed";
CM_ SG_ 798 CP_a136_sdpSideReqFailed "Charge port controller: a136 sdp side req failed";
CM_ SG_ 798 CP_a137_plcForwardError "Charge port controller: a137 plc forward error";
CM_ SG_ 798 CP_a138_swcanCommsAcEvseFaulted "Charge port controller: a138 swcan comms ac evse faulted";
CM_ SG_ 798 CP_a139_pilotFaulted "Charge port controller: a139 pilot faulted";
CM_ SG_ 798 CP_a140_superchargerFaulted "Charge port controller: a140 supercharger faulted";
CM_ SG_ 798 CP_a141_chademoAdapterFault "Charge port controller: a141 chademo adapter fault";
CM_ SG_ 798 CP_a142_gbdcScConnFault "Charge port controller: a142 gbdc sc conn fault";
CM_ SG_ 798 CP_a143_unsupportedChargeAdapter "Charge port controller: a143 unsupported charge adapter";
CM_ SG_ 798 CP_a144_nvmInitFailed "Charge port controller: a144 nvm init failed";
CM_ SG_ 798 CP_a145_modemAppLoadFailedNA "Charge port controller: a145 modem app load failed NA";
CM_ SG_ 798 CP_a146_ccsEvseMalfunction "Charge port controller: a146 ccs evse malfunction";
CM_ SG_ 798 CP_a147_inductiveRecoveredMia "Charge port controller: a147 inductive recovered mia";
CM_ SG_ 798 CP_a148_bldcTachFeedbackMia "Charge port controller: a148 bldc tach feedback mia";
CM_ SG_ 798 CP_a149_pilotPeriodInvalid "Charge port controller: a149 pilot period invalid";
CM_ SG_ 798 CP_a150_railToggleTimeout "Charge port controller: a150 rail toggle timeout";
CM_ SG_ 798 CP_a151_badPilotDiodeDetected "Charge port controller: a151 bad pilot diode detected";
CM_ SG_ 798 CP_a152_pilotEdgeDetectionFailed "Charge port controller: a152 pilot edge detection failed";
CM_ SG_ 798 CP_a153_thermalAcLimitActive "Charge port controller: a153 thermal ac limit active";
CM_ SG_ 798 CP_a154_acChargingStoppedOT "Charge port controller: a154 ac charging stopped OT";
CM_ SG_ 798 CP_a155_hallPresenceRationality "Charge port controller: a155 hall presence rationality";
CM_ SG_ 798 CP_a156_gbdcPrechargingConcern "Charge port controller: a156 gbdc precharging concern";
CM_ SG_ 798 CP_a157_doorOpenRateLimiter "Charge port controller: a157 door open rate limiter";
CM_ SG_ 798 CP_a158_doorCloseRateLimiter "Charge port controller: a158 door close rate limiter";
CM_ SG_ 798 CP_a159_swcanHealthCheckFailed "Charge port controller: a159 swcan health check failed";
CM_ SG_ 798 CP_a160_latchDisengageInDcCharge "Charge port controller: a160 latch disengage in dc charge";
CM_ SG_ 798 CP_a161_badPilotDiodeDetectedCN "Charge port controller: a161 bad pilot diode detected CN";
CM_ SG_ 798 CP_a162_pilotEdgeDetectionFailed "Charge port controller: a162 pilot edge detection failed CN";
CM_ SG_ 798 CP_a163_coverOpenDcChgBlocked "Charge port controller: a163 cover open dc chg blocked";
CM_ SG_ 798 CP_a164_latchRedisengageRequeste "Charge port controller: a164 latch redisengage requested";
CM_ SG_ 798 CP_a165_proxWiggleDetected "Charge port controller: a165 prox wiggle detected";
CM_ SG_ 798 CP_a166_faultLineMismatchDetecte "Charge port controller: a166 fault line mismatch detected";
CM_ SG_ 798 CP_a167_doorIdIrrational "Charge port controller: a167 door id irrational";
CM_ SG_ 798 CP_a172_triggerOdin "Signal reported by Charge port controller";
CM_ SG_ 798 CP_a173_coverOpenAcChgBlocked "Charge port controller: a173 cover open ac chg blocked";
CM_ SG_ 798 CP_a174_fwdedMsgLoadWarning "Charge port controller: a174 fwded msg load warning";
CM_ SG_ 798 CP_a175_fwdedMsgDropped "Charge port controller: a175 fwded msg dropped";
CM_ SG_ 798 CP_a177_incompatibleV2lDeviceDet "Charge port controller: a177 incompatible v2l device detected";
CM_ SG_ 798 CP_a179_evseCommsTlsError "Charge port controller: a179 evse comms tls error";
CM_ SG_ 798 CP_a182_pncdCommsError "Charge port controller: a182 pncd comms error";
CM_ SG_ 798 CP_a183_certManagerError "Charge port controller: a183 cert manager error";
CM_ SG_ 798 CP_a184_certChangeEvent "Charge port controller: a184 cert change event";
CM_ SG_ 798 CP_a185_pncAuthRejection "Charge port controller: a185 pnc auth rejection";
CM_ SG_ 798 CP_a186_spiDmaFailure "Charge port controller: a186 spi dma failure";
CM_ SG_ 798 CP_a187_highStackUsage "Charge port controller: a187 high stack usage";
CM_ BO_ 669 "Charge port controller message: dc charge status";
CM_ SG_ 669 CP_evseOutputDcCurrent "The DC EVSE's measured output current";
CM_ SG_ 669 CP_evseOutputDcVoltage "The DC EVSE's measured output voltage";
CM_ SG_ 669 CP_evseOutputDcCurrentStale "Indicates whether the data in CP_evseOutputDcCurrent has not been updated with new info from the DC EVSE recently";
CM_ BO_ 541 "Charge port controller message: evse status";
CM_ SG_ 541 CP_evseAccept "State of pilot EVSE accept state";
CM_ SG_ 541 CP_evseRequest "Request to close AC EVSE relays, used when digital communications have been established";
CM_ SG_ 541 CP_proximity "Sensed state of proximity for all inlets; raw 0 = signal not available (SNA)";
CM_ SG_ 541 CP_pilot "State of EVSE pilot signal sensed by the charge port; raw 7 = signal not available (SNA)";
CM_ SG_ 541 CP_digitalCommsEstablished "Indicates whether digital communications have been established with an EVSE";
CM_ SG_ 541 CP_pilotCurrent "Line current limit detected from pilot signal";
CM_ SG_ 541 CP_cableType "Type of charge cable detected; raw 4 = signal not available (SNA)";
CM_ SG_ 541 CP_iecPilotState "State of the control pilot as defined in IEC-61851-1; raw 9 = signal not available (SNA)";
CM_ SG_ 541 CP_plcSupported "Indicates whether PLC hardware is populated for CCS charging support";
CM_ SG_ 541 CP_cableCurrentLimit "Charge port controller: cable current limit";
CM_ SG_ 541 CP_teslaSwcanState "Charge port controller: tesla swcan state";
CM_ SG_ 541 CP_evseChargeType_UI "Reports the type of Electric Vehicle Supply Equipment (EVSE) connected.";
CM_ SG_ 541 CP_gbState "State of GB DC charging";
CM_ SG_ 541 CP_gbdcStopChargeReason "Reason for stopping GB DC charging";
CM_ SG_ 541 CP_gbdcFailureReason "Reason for failure of GB DC charging";
CM_ SG_ 541 CP_gbdcChargeAttempts "Number of GB DC charging retries used";
CM_ SG_ 541 CP_acChargeState "Charge port controller: ac charge state";
CM_ SG_ 541 CP_teslaDcState "Reports the state of the Tesla direct current (DC) state machine.";
CM_ BO_ 1342 "Charge port controller message: info";
CM_ SG_ 1342 CP_infoIndex "Charge port controller: info index";
CM_ SG_ 1342 CP_buildType "Charge port controller: build type";
CM_ SG_ 1342 CP_buildConfigId "Charge port controller: build config id";
CM_ SG_ 1342 CP_hardwareId "Charge port controller: hardware id";
CM_ SG_ 1342 CP_componentId "Charge port controller: component id";
CM_ SG_ 1342 CP_pcbaId "Charge port controller: pcba id";
CM_ SG_ 1342 CP_assemblyId "Charge port controller: assembly id";
CM_ SG_ 1342 CP_usageId "Charge port controller: usage id";
CM_ SG_ 1342 CP_subUsageId "Charge port controller: sub usage id";
CM_ SG_ 1342 CP_platformType "Charge port controller: platform type";
CM_ SG_ 1342 CP_appCrc "Charge port controller: app crc";
CM_ SG_ 1342 CP_appGitHash "Charge port controller: app git hash";
CM_ SG_ 1342 CP_bootGitHash "Charge port controller: boot git hash";
CM_ SG_ 1342 CP_bootUdsProtoVersion "Charge port controller: boot uds proto version";
CM_ SG_ 1342 CP_bootCrc "Charge port controller: boot crc";
CM_ BO_ 1885 "Charge port controller message: logging fast";
CM_ SG_ 1885 CP_loggingFastSelect "Charge port controller: logging fast select";
CM_ SG_ 1885 CP_inductiveSensor_raw "Charge port controller: inductive sensor raw";
CM_ SG_ 1885 CP_doorOpenActuationTime "Charge port controller: door open actuation time";
CM_ SG_ 1885 CP_doorCloseActuationTime "Charge port controller: door close actuation time";
CM_ SG_ 1885 CP_chargeCableSecured "Indicates whether a charge cable is secured in any inlet";
CM_ SG_ 1885 CP_chargeCablePresent "Indicates whether a charge cable is present in any inlet";
CM_ SG_ 1885 CP_latchCheckAvailable "Charge port controller: latch check available";
CM_ SG_ 1885 CP_UHF_controlState "Control state of UHF receiver";
CM_ SG_ 1885 CP_proximityV "Charge port controller: proximity v";
CM_ SG_ 1885 CP_proximityV_GBCC1 "Sensed voltage of GB DC inlet CC1 connection";
CM_ SG_ 1885 CP_proximityV_GBCC2 "Sensed voltage of GB DC inlet CC2 connection";
CM_ SG_ 1885 CP_doorPot "Position of the charge port door potentiometer";
CM_ SG_ 1885 CP_doorPresenceHallSensorV "Charge port controller: door presence hall sensor v";
CM_ SG_ 1885 CP_doorOpenRequest "Door open request trigger";
CM_ SG_ 1885 CP_doorOpenEndOfDriveReason "Reason why the door stopped moving in the open direction";
CM_ SG_ 1885 CP_coverClosed "Charge port controller: cover closed";
CM_ SG_ 1885 CP_doorCloseEndOfDriveReason "Reason why the door stopped moving in the closing direction";
CM_ SG_ 1885 CP_doorCloseRequest "Door close request trigger";
CM_ SG_ 1885 CP_latchDisengagingTime "Charge port controller: latch disengaging time";
CM_ SG_ 1885 CP_latchEngagingTime "Charge port controller: latch engaging time";
CM_ SG_ 1885 CP_latchDisengagingStopReason "Reason why the latch stopped moving in the engaged direction";
CM_ SG_ 1885 CP_latchEngagingStopReason "Reason why the latch stopped moving in the engaged direction";
CM_ SG_ 1885 CP_doorIdDetectionState "Charge port controller: door id detection state; raw 0 = signal not available (SNA)";
CM_ SG_ 1885 CP_doorIdDetectedBin "Charge port controller: door id detected bin";
CM_ BO_ 989 "Charge port controller message: logging slow";
CM_ SG_ 989 CP_loggingSlowSelect "Charge port controller: logging slow select";
CM_ SG_ 989 CP_UHF_chipState "Charge port controller: UHF chip state";
CM_ SG_ 989 CP_UHF_rssi "Signal strength of received UHF signal";
CM_ SG_ 989 CP_UHF_rxOverflow "Charge port controller: UHF rx overflow";
CM_ SG_ 989 CP_UHF_rxNumBytes "Charge port controller: UHF rx num bytes";
CM_ SG_ 989 CP_UHF_selfTestRssi "Signal strength of received self-test UHF signal";
CM_ SG_ 989 CP_latchI "Charge port controller: latch i";
CM_ SG_ 989 CP_inlet1HarnessIdState "State of the CP's inlet 1 harness pedigree; raw 0 = signal not available (SNA)";
CM_ SG_ 989 CP_inlet1HarnessIdValue "Pedigree of the CP's inlet 1 harness";
CM_ SG_ 989 CP_inlet2HarnessIdState "State of the CP's inlet 2 harness pedigree; raw 0 = signal not available (SNA)";
CM_ SG_ 989 CP_inlet2HarnessIdValue "Pedigree of the CP's inlet 2 harness";
CM_ SG_ 989 CP_inletHeaterState "Reports the present state of the inlet heater.";
CM_ SG_ 989 CP_inletHeaterDuty "Inlet heater PWM duty cycle";
CM_ SG_ 989 CP_nvm_dataValid "Charge port controller: nvm data valid";
CM_ SG_ 989 CP_nvm_doorOpenCycles "Charge port controller: nvm door open cycles";
CM_ SG_ 989 CP_nvm_doorCloseCycles "Charge port controller: nvm door close cycles";
CM_ SG_ 989 CP_nvm_doorOpen "Charge port controller: nvm door open";
CM_ SG_ 989 CP_nvm_doorPresent "Charge port controller: nvm door present";
CM_ SG_ 989 CP_nvm_doorPresentValid "Charge port controller: nvm door present valid";
CM_ SG_ 989 CP_nvm_badPilotDiodeDetected "Charge port controller: nvm bad pilot diode detected";
CM_ SG_ 989 CP_nvm_pilotDiodeFaultCount "Charge port controller: nvm pilot diode fault count";
CM_ SG_ 989 CP_doorOpenLimiterMaxCount "Charge port controller: door open limiter max count";
CM_ SG_ 989 CP_doorOpenLimiterMaxRequestType "Charge port controller: door open limiter max request type";
CM_ SG_ 989 CP_doorCloseLimiterMaxCount "Charge port controller: door close limiter max count";
CM_ SG_ 989 CP_doorCloseLimiterMaxRequestTyp "Charge port controller: door close limiter max request type";
CM_ BO_ 605 "Charge port controller message: status";
CM_ SG_ 605 CP_type "Charge port controller: type";
CM_ SG_ 605 CP_insertEnableLine "Sensed state of the charge port latch drive enable hardline";
CM_ SG_ 605 CP_latchState "Sensed state of the charge port latch; raw 0 = signal not available (SNA)";
CM_ SG_ 605 CP_permanentPowerRequest "Charge port controller: permanent power request";
CM_ SG_ 605 CP_chargeDoorOpen "Indicates whether the charge port door is open based on all door sensors";
CM_ SG_ 605 CP_doorControlState "State of the charge port door controller";
CM_ SG_ 605 CP_doorButtonPressed "Indicates whether the charge door button has been pressed";
CM_ SG_ 605 CP_swcanRelayClosed "Indicates whether the single wire CAN relay is closed";
CM_ SG_ 605 CP_inhibitOta "Reports the charge port's request to prevent scheduled Over-The-Air (OTA) updates during critical charging operations.";
CM_ SG_ 605 CP_chargeCableState "Charge cable connection state; raw 0 = signal not available (SNA)";
CM_ SG_ 605 CP_latchControlState "Control state of the charge port latch";
CM_ SG_ 605 CP_ledColor "Color of the charge port LED";
CM_ SG_ 605 CP_UHF_handleFound "Indicates whether a charge handle has been found with UHF";
CM_ SG_ 605 CP_faultLineSensed "A signal indicating the set / cleared state of the CP-HVP bi-directional fault line, as sensed by the CP";
CM_ SG_ 605 CP_doorPresenceState "State of door as detected by the presence sensor";
CM_ SG_ 605 CP_inductiveSensorState "State of inductive door sensor";
CM_ SG_ 605 CP_chargeDoorOpenUI "Indicates whether the charge port door is open based only on the door poteniometer";
CM_ SG_ 605 CP_vehicleUnlockRequest "Request to unlock the vehicle";
CM_ SG_ 605 CP_coldWeatherMode "Indicates whether the charge port is in cold weather mode";
CM_ SG_ 605 CP_hvInletExposed "Charge port controller: hv inlet exposed";
CM_ SG_ 605 CP_latchEngaged "Charge port controller: latch engaged";
CM_ SG_ 605 CP_inletHeaterUiState "Reports to the User Interface (UI) the state of the inlet heater.";
CM_ BO_ 893 "Charge port controller message: thermal status";
CM_ SG_ 893 CP_thermalStatusSelect "Charge port controller: thermal status select";
CM_ SG_ 893 CP_pinTemperature1 "Sensed temperature of the charge port inlet pins";
CM_ SG_ 893 CP_pinTemperature2 "Sensed temperature of the charge port inlet pins";
CM_ SG_ 893 CP_pinTemperature3 "Sensed temperature of the charge port inlet pins";
CM_ BO_ 1001 "Driver assistance computer message: body controls";
CM_ SG_ 1001 DAS_headlightRequest "The DAS request to the body controls ecu to turn on headlights.";
CM_ SG_ 1001 DAS_hazardLightRequest "The command from DAS to body controls to turn on the hazard lights.; raw 3 = signal not available (SNA)";
CM_ SG_ 1001 DAS_wiperSpeed "The auto wiper algorithm speed request to the body controller.";
CM_ SG_ 1001 DAS_turnIndicatorRequest "Reports Driver Assistance System (DAS) request to body controls to turn on/off the left or right turn indicator.";
CM_ SG_ 1001 DAS_highLowBeamDecision "The output of the automatic high beam algorithm, to turn the highbeams on or off.; raw 3 = signal not available (SNA)";
CM_ SG_ 1001 DAS_heaterRequest "The DAS request to the body controller to turn on the front glass heater in front of the triple camera.; raw 0 = signal not available (SNA)";
CM_ SG_ 1001 DAS_highLowBeamOffReason "The reason why automatic high beams are surpressed.; raw 5 = signal not available (SNA)";
CM_ SG_ 1001 DAS_forwardCamHeaterDutyCycle "Supplies the requested duty cycle of the front windshield camera heater";
CM_ SG_ 1001 DAS_dynamicBrakeLightRequest "Indicates if the dynamic brake light alogirthm is requesting pulsing brake lights.";
CM_ SG_ 1001 DAS_radarHeaterRequest "Reports the request from Driver Assistance System (DAS) to body controls to turn on heater to clear out fascia in front of the radar.";
CM_ SG_ 1001 DAS_ahlbOverride "Indicates if body controller should override UI switch and stalk state to allow auto high beam functionality";
CM_ SG_ 1001 DAS_mirrorFoldRequest "DAS request to fold or present mirrors.; raw 3 = signal not available (SNA)";
CM_ SG_ 1001 DAS_wiperWashRequest "Autowiper requests that the windshield be washed";
CM_ SG_ 1001 DAS_ulcConfirmationRequestActive "Driver assistance computer: ulc confirmation request active";
CM_ SG_ 1001 DAS_overrideWiperSetting "Autopilot wants to override the user's wiper setting to enable auto-wiper";
CM_ SG_ 1001 DAS_autoWiperState "DAS auto wiper internal state; raw 5 = signal not available (SNA)";
CM_ SG_ 1001 DAS_turnIndicatorRequestReason "Reports the reason that Driver Assistance System (DAS) is requesting a change to the turn indicator state from body controls.";
CM_ SG_ 1001 DAS_forwardRadarPowerRequest "Driver assistance computer: forward radar power request";
CM_ SG_ 1001 DAS_driverDomeLightRequest "DAS requests that driver side dome light be illuminated";
CM_ SG_ 1001 DAS_drivePowerStateRequest "Reports DAS request for vehicle power state Drive.";
CM_ SG_ 1001 DAS_enableIcrDataCollection "Driver assistance computer: enable icr data collection";
CM_ SG_ 1001 DAS_rPillarCamHeaterDutyCycle "Supplies the requested duty cycle of the right pillar camera heater";
CM_ SG_ 1001 DAS_adaptiveHighBeamIsFaulted "Indicates malfunctioning or unavailable input to the Adaptive High Beam system.";
CM_ SG_ 1001 DAS_restrictDoorReleaseLeft "Reports requests to inhibit left doors from being released.";
CM_ SG_ 1001 DAS_restrictDoorReleaseRight "Reports requests to inhibit right doors from being released.";
CM_ SG_ 1001 DAS_bodyControlsCounter "Driver assistance computer: body controls counter";
CM_ SG_ 1001 DAS_bodyControlsChecksum "Driver assistance computer: body controls checksum";
CM_ BO_ 1318 "Front drive inverter message: alert log";
CM_ SG_ 1318 DIF_alertID "Front drive inverter: alert ID";
CM_ SG_ 1318 DIF_alertState "Front drive inverter: alert state";
CM_ SG_ 1318 DIF_a001_thermalWarning_H "Front drive inverter: a001 thermal warning h";
CM_ SG_ 1318 DIF_a001_thermalShutdown_H "Front drive inverter: a001 thermal shutdown h";
CM_ SG_ 1318 DIF_a001_undervoltVL_H "Front drive inverter: a001 undervolt VL h";
CM_ SG_ 1318 DIF_a001_undervoltVH_H "Front drive inverter: a001 undervolt VH h";
CM_ SG_ 1318 DIF_a001_sense_H "Front drive inverter: a001 sense h";
CM_ SG_ 1318 DIF_a001_desat_H "Front drive inverter: a001 desat h";
CM_ SG_ 1318 DIF_a001_overvoltVL_H "Front drive inverter: a001 overvolt VL h";
CM_ SG_ 1318 DIF_a001_overvoltVH_H "Front drive inverter: a001 overvolt VH h";
CM_ SG_ 1318 DIF_a001_undervoltVCC_H "Front drive inverter: a001 undervolt VCC h";
CM_ SG_ 1318 DIF_a001_asynchStop_H "Front drive inverter: a001 asynch stop h";
CM_ SG_ 1318 DIF_a001_remoteRegError_H "Front drive inverter: a001 remote reg error h";
CM_ SG_ 1318 DIF_a001_undervoltVDD_H "Front drive inverter: a001 undervolt VDD h";
CM_ SG_ 1318 DIF_a001_overvoltVDD_H "Front drive inverter: a001 overvolt VDD h";
CM_ SG_ 1318 DIF_a001_localRegError_H "Front drive inverter: a001 local reg error h";
CM_ SG_ 1318 DIF_a001_spiError_H "Front drive inverter: a001 spi error h";
CM_ SG_ 1318 DIF_a001_deadtimeError_H "Front drive inverter: a001 deadtime error h";
CM_ SG_ 1318 DIF_a001_thermalWarning_L "Front drive inverter: a001 thermal warning l";
CM_ SG_ 1318 DIF_a001_thermalShutdown_L "Front drive inverter: a001 thermal shutdown l";
CM_ SG_ 1318 DIF_a001_undervoltVL_L "Front drive inverter: a001 undervolt VL l";
CM_ SG_ 1318 DIF_a001_undervoltVH_L "Front drive inverter: a001 undervolt VH l";
CM_ SG_ 1318 DIF_a001_sense_L "Front drive inverter: a001 sense l";
CM_ SG_ 1318 DIF_a001_desat_L "Front drive inverter: a001 desat l";
CM_ SG_ 1318 DIF_a001_overvoltVL_L "Front drive inverter: a001 overvolt VL l";
CM_ SG_ 1318 DIF_a001_overvoltVH_L "Front drive inverter: a001 overvolt VH l";
CM_ SG_ 1318 DIF_a001_undervoltVCC_L "Front drive inverter: a001 undervolt VCC l";
CM_ SG_ 1318 DIF_a001_asynchStop_L "Front drive inverter: a001 asynch stop l";
CM_ SG_ 1318 DIF_a001_remoteRegError_L "Front drive inverter: a001 remote reg error l";
CM_ SG_ 1318 DIF_a001_undervoltVDD_L "Front drive inverter: a001 undervolt VDD l";
CM_ SG_ 1318 DIF_a001_overvoltVDD_L "Front drive inverter: a001 overvolt VDD l";
CM_ SG_ 1318 DIF_a001_localRegError_L "Front drive inverter: a001 local reg error l";
CM_ SG_ 1318 DIF_a001_spiError_L "Front drive inverter: a001 spi error l";
CM_ SG_ 1318 DIF_a001_deadtimeError_L "Front drive inverter: a001 deadtime error l";
CM_ SG_ 1318 DIF_a001_gateDriveErrCounter "Front drive inverter: a001 gate drive err counter";
CM_ SG_ 1318 DIF_a001_remoteCommError_H "Front drive inverter: a001 remote comm error h";
CM_ SG_ 1318 DIF_a001_localCommError_H "Front drive inverter: a001 local comm error h";
CM_ SG_ 1318 DIF_a001_remoteReset_H "Front drive inverter: a001 remote reset h";
CM_ SG_ 1318 DIF_a001_localReset_H "Front drive inverter: a001 local reset h";
CM_ SG_ 1318 DIF_a001_remoteCommError_L "Front drive inverter: a001 remote comm error l";
CM_ SG_ 1318 DIF_a001_localCommError_L "Front drive inverter: a001 local comm error l";
CM_ SG_ 1318 DIF_a001_remoteReset_L "Front drive inverter: a001 remote reset l";
CM_ SG_ 1318 DIF_a001_localReset_L "Front drive inverter: a001 local reset l";
CM_ SG_ 1318 DIF_a001_faultLine1Gpio_H "Front drive inverter: a001 fault line1 gpio h";
CM_ SG_ 1318 DIF_a001_faultLine1Gpio_L "Front drive inverter: a001 fault line1 gpio l";
CM_ SG_ 1318 DIF_a002_thermalWarning_H "Front drive inverter: a002 thermal warning h";
CM_ SG_ 1318 DIF_a002_thermalShutdown_H "Front drive inverter: a002 thermal shutdown h";
CM_ SG_ 1318 DIF_a002_undervoltVL_H "Front drive inverter: a002 undervolt VL h";
CM_ SG_ 1318 DIF_a002_undervoltVH_H "Front drive inverter: a002 undervolt VH h";
CM_ SG_ 1318 DIF_a002_sense_H "Front drive inverter: a002 sense h";
CM_ SG_ 1318 DIF_a002_desat_H "Front drive inverter: a002 desat h";
CM_ SG_ 1318 DIF_a002_overvoltVL_H "Front drive inverter: a002 overvolt VL h";
CM_ SG_ 1318 DIF_a002_overvoltVH_H "Front drive inverter: a002 overvolt VH h";
CM_ SG_ 1318 DIF_a002_undervoltVCC_H "Front drive inverter: a002 undervolt VCC h";
CM_ SG_ 1318 DIF_a002_asynchStop_H "Front drive inverter: a002 asynch stop h";
CM_ SG_ 1318 DIF_a002_remoteRegError_H "Front drive inverter: a002 remote reg error h";
CM_ SG_ 1318 DIF_a002_undervoltVDD_H "Front drive inverter: a002 undervolt VDD h";
CM_ SG_ 1318 DIF_a002_overvoltVDD_H "Front drive inverter: a002 overvolt VDD h";
CM_ SG_ 1318 DIF_a002_localRegError_H "Front drive inverter: a002 local reg error h";
CM_ SG_ 1318 DIF_a002_spiError_H "Front drive inverter: a002 spi error h";
CM_ SG_ 1318 DIF_a002_deadtimeError_H "Front drive inverter: a002 deadtime error h";
CM_ SG_ 1318 DIF_a002_thermalWarning_L "Front drive inverter: a002 thermal warning l";
CM_ SG_ 1318 DIF_a002_thermalShutdown_L "Front drive inverter: a002 thermal shutdown l";
CM_ SG_ 1318 DIF_a002_undervoltVL_L "Front drive inverter: a002 undervolt VL l";
CM_ SG_ 1318 DIF_a002_undervoltVH_L "Front drive inverter: a002 undervolt VH l";
CM_ SG_ 1318 DIF_a002_sense_L "Front drive inverter: a002 sense l";
CM_ SG_ 1318 DIF_a002_desat_L "Front drive inverter: a002 desat l";
CM_ SG_ 1318 DIF_a002_overvoltVL_L "Front drive inverter: a002 overvolt VL l";
CM_ SG_ 1318 DIF_a002_overvoltVH_L "Front drive inverter: a002 overvolt VH l";
CM_ SG_ 1318 DIF_a002_undervoltVCC_L "Front drive inverter: a002 undervolt VCC l";
CM_ SG_ 1318 DIF_a002_asynchStop_L "Front drive inverter: a002 asynch stop l";
CM_ SG_ 1318 DIF_a002_remoteRegError_L "Front drive inverter: a002 remote reg error l";
CM_ SG_ 1318 DIF_a002_undervoltVDD_L "Front drive inverter: a002 undervolt VDD l";
CM_ SG_ 1318 DIF_a002_overvoltVDD_L "Front drive inverter: a002 overvolt VDD l";
CM_ SG_ 1318 DIF_a002_localRegError_L "Front drive inverter: a002 local reg error l";
CM_ SG_ 1318 DIF_a002_spiError_L "Front drive inverter: a002 spi error l";
CM_ SG_ 1318 DIF_a002_deadtimeError_L "Front drive inverter: a002 deadtime error l";
CM_ SG_ 1318 DIF_a002_gateDriveErrCounter "Front drive inverter: a002 gate drive err counter";
CM_ SG_ 1318 DIF_a002_selftestDesat_L "Front drive inverter: a002 selftest desat l";
CM_ SG_ 1318 DIF_a002_selftestDesat_H "Front drive inverter: a002 selftest desat h";
CM_ SG_ 1318 DIF_a002_remoteCommError_H "Front drive inverter: a002 remote comm error h";
CM_ SG_ 1318 DIF_a002_localCommError_H "Front drive inverter: a002 local comm error h";
CM_ SG_ 1318 DIF_a002_remoteReset_H "Front drive inverter: a002 remote reset h";
CM_ SG_ 1318 DIF_a002_localReset_H "Front drive inverter: a002 local reset h";
CM_ SG_ 1318 DIF_a002_remoteCommError_L "Front drive inverter: a002 remote comm error l";
CM_ SG_ 1318 DIF_a002_localCommError_L "Front drive inverter: a002 local comm error l";
CM_ SG_ 1318 DIF_a002_remoteReset_L "Front drive inverter: a002 remote reset l";
CM_ SG_ 1318 DIF_a002_localReset_L "Front drive inverter: a002 local reset l";
CM_ SG_ 1318 DIF_a002_faultLine1Gpio_H "Front drive inverter: a002 fault line1 gpio h";
CM_ SG_ 1318 DIF_a002_faultLine1Gpio_L "Front drive inverter: a002 fault line1 gpio l";
CM_ SG_ 1318 DIF_a003_thermalWarning_H "Front drive inverter: a003 thermal warning h";
CM_ SG_ 1318 DIF_a003_thermalShutdown_H "Front drive inverter: a003 thermal shutdown h";
CM_ SG_ 1318 DIF_a003_undervoltVL_H "Front drive inverter: a003 undervolt VL h";
CM_ SG_ 1318 DIF_a003_undervoltVH_H "Front drive inverter: a003 undervolt VH h";
CM_ SG_ 1318 DIF_a003_sense_H "Front drive inverter: a003 sense h";
CM_ SG_ 1318 DIF_a003_desat_H "Front drive inverter: a003 desat h";
CM_ SG_ 1318 DIF_a003_overvoltVL_H "Front drive inverter: a003 overvolt VL h";
CM_ SG_ 1318 DIF_a003_overvoltVH_H "Front drive inverter: a003 overvolt VH h";
CM_ SG_ 1318 DIF_a003_undervoltVCC_H "Front drive inverter: a003 undervolt VCC h";
CM_ SG_ 1318 DIF_a003_asynchStop_H "Front drive inverter: a003 asynch stop h";
CM_ SG_ 1318 DIF_a003_remoteRegError_H "Front drive inverter: a003 remote reg error h";
CM_ SG_ 1318 DIF_a003_undervoltVDD_H "Front drive inverter: a003 undervolt VDD h";
CM_ SG_ 1318 DIF_a003_overvoltVDD_H "Front drive inverter: a003 overvolt VDD h";
CM_ SG_ 1318 DIF_a003_localRegError_H "Front drive inverter: a003 local reg error h";
CM_ SG_ 1318 DIF_a003_spiError_H "Front drive inverter: a003 spi error h";
CM_ SG_ 1318 DIF_a003_deadtimeError_H "Front drive inverter: a003 deadtime error h";
CM_ SG_ 1318 DIF_a003_thermalWarning_L "Front drive inverter: a003 thermal warning l";
CM_ SG_ 1318 DIF_a003_thermalShutdown_L "Front drive inverter: a003 thermal shutdown l";
CM_ SG_ 1318 DIF_a003_undervoltVL_L "Front drive inverter: a003 undervolt VL l";
CM_ SG_ 1318 DIF_a003_undervoltVH_L "Front drive inverter: a003 undervolt VH l";
CM_ SG_ 1318 DIF_a003_sense_L "Front drive inverter: a003 sense l";
CM_ SG_ 1318 DIF_a003_desat_L "Front drive inverter: a003 desat l";
CM_ SG_ 1318 DIF_a003_overvoltVL_L "Front drive inverter: a003 overvolt VL l";
CM_ SG_ 1318 DIF_a003_overvoltVH_L "Front drive inverter: a003 overvolt VH l";
CM_ SG_ 1318 DIF_a003_undervoltVCC_L "Front drive inverter: a003 undervolt VCC l";
CM_ SG_ 1318 DIF_a003_asynchStop_L "Front drive inverter: a003 asynch stop l";
CM_ SG_ 1318 DIF_a003_remoteRegError_L "Front drive inverter: a003 remote reg error l";
CM_ SG_ 1318 DIF_a003_undervoltVDD_L "Front drive inverter: a003 undervolt VDD l";
CM_ SG_ 1318 DIF_a003_overvoltVDD_L "Front drive inverter: a003 overvolt VDD l";
CM_ SG_ 1318 DIF_a003_localRegError_L "Front drive inverter: a003 local reg error l";
CM_ SG_ 1318 DIF_a003_spiError_L "Front drive inverter: a003 spi error l";
CM_ SG_ 1318 DIF_a003_deadtimeError_L "Front drive inverter: a003 deadtime error l";
CM_ SG_ 1318 DIF_a003_gateDriveErrCounter "Front drive inverter: a003 gate drive err counter";
CM_ SG_ 1318 DIF_a003_selftestDesat_L "Front drive inverter: a003 selftest desat l";
CM_ SG_ 1318 DIF_a003_selftestDesat_H "Front drive inverter: a003 selftest desat h";
CM_ SG_ 1318 DIF_a003_remoteCommError_H "Front drive inverter: a003 remote comm error h";
CM_ SG_ 1318 DIF_a003_localCommError_H "Front drive inverter: a003 local comm error h";
CM_ SG_ 1318 DIF_a003_remoteReset_H "Front drive inverter: a003 remote reset h";
CM_ SG_ 1318 DIF_a003_localReset_H "Front drive inverter: a003 local reset h";
CM_ SG_ 1318 DIF_a003_remoteCommError_L "Front drive inverter: a003 remote comm error l";
CM_ SG_ 1318 DIF_a003_localCommError_L "Front drive inverter: a003 local comm error l";
CM_ SG_ 1318 DIF_a003_remoteReset_L "Front drive inverter: a003 remote reset l";
CM_ SG_ 1318 DIF_a003_localReset_L "Front drive inverter: a003 local reset l";
CM_ SG_ 1318 DIF_a003_faultLine1Gpio_H "Front drive inverter: a003 fault line1 gpio h";
CM_ SG_ 1318 DIF_a003_faultLine1Gpio_L "Front drive inverter: a003 fault line1 gpio l";
CM_ SG_ 1318 DIF_a007_phaseAcurrent "Front drive inverter: a007 phase acurrent";
CM_ SG_ 1318 DIF_a007_phaseBcurrent "Front drive inverter: a007 phase bcurrent";
CM_ SG_ 1318 DIF_a007_offsetError "Front drive inverter: a007 offset error";
CM_ SG_ 1318 DIF_a007_idFdbStdDeviation "Front drive inverter: a007 id fdb std deviation";
CM_ SG_ 1318 DIF_a007_iqFdbStdDeviation "Front drive inverter: a007 iq fdb std deviation";
CM_ SG_ 1318 DIF_a007_motorShift "Front drive inverter: a007 motor shift";
CM_ SG_ 1318 DIF_a007_motorShort "Front drive inverter: a007 motor short";
CM_ SG_ 1318 DIF_a010_sccReset "Front drive inverter: a010 scc reset";
CM_ SG_ 1318 DIF_a010_hibernate "Front drive inverter: a010 hibernate";
CM_ SG_ 1318 DIF_a010_hwBist "Front drive inverter: a010 hw bist";
CM_ SG_ 1318 DIF_a010_nmiWatchdog "Front drive inverter: a010 nmi watchdog";
CM_ SG_ 1318 DIF_a010_watchdog "Front drive inverter: a010 watchdog";
CM_ SG_ 1318 DIF_a010_clockFailNmi "Front drive inverter: a010 clock fail nmi";
CM_ SG_ 1318 DIF_a010_ramUncErrorNmi "Front drive inverter: a010 ram unc error nmi";
CM_ SG_ 1318 DIF_a010_flashUncErrorNmi "Front drive inverter: a010 flash unc error nmi";
CM_ SG_ 1318 DIF_a010_cpu1signMismatchNmi "Front drive inverter: a010 cpu1sign mismatch nmi";
CM_ SG_ 1318 DIF_a010_cpu2signMismatchNmi "Front drive inverter: a010 cpu2sign mismatch nmi";
CM_ SG_ 1318 DIF_a010_pieVectErrorNmi "Front drive inverter: a010 pie vect error nmi";
CM_ SG_ 1318 DIF_a010_sysDbgNmi "Front drive inverter: a010 sys dbg nmi";
CM_ SG_ 1318 DIF_a010_rlNmi "Front drive inverter: a010 rl nmi";
CM_ SG_ 1318 DIF_a010_ovfNmi "Front drive inverter: a010 ovf nmi";
CM_ SG_ 1318 DIF_a010_wdtFlags "Front drive inverter: a010 wdt flags";
CM_ SG_ 1318 DIF_a011_reason "Front drive inverter: a011 reason";
CM_ SG_ 1318 DIF_a011_phaseAHigh "Front drive inverter: a011 phase a high";
CM_ SG_ 1318 DIF_a011_phaseALow "Front drive inverter: a011 phase a low";
CM_ SG_ 1318 DIF_a011_phaseBHigh "Front drive inverter: a011 phase b high";
CM_ SG_ 1318 DIF_a011_phaseBLow "Front drive inverter: a011 phase b low";
CM_ SG_ 1318 DIF_a011_phaseCHigh "Front drive inverter: a011 phase c high";
CM_ SG_ 1318 DIF_a011_phaseCLow "Front drive inverter: a011 phase c low";
CM_ SG_ 1318 DIF_a011_regAddress "Front drive inverter: a011 reg address";
CM_ SG_ 1318 DIF_a011_badGateDriveIC "Front drive inverter: a011 bad gate drive IC";
CM_ SG_ 1318 DIF_a011_badDataRead "Front drive inverter: a011 bad data read";
CM_ SG_ 1318 DIF_a011_badDataExpected "Front drive inverter: a011 bad data expected";
CM_ SG_ 1318 DIF_a011_codeBranch "Front drive inverter: a011 code branch";
CM_ SG_ 1318 DIF_a012_hvilStatus "Front drive inverter: a012 hvil status; raw 3 = signal not available (SNA)";
CM_ SG_ 1318 DIF_a012_hvilCmVoltage "Front drive inverter: a012 hvil cm voltage";
CM_ SG_ 1318 DIF_a012_hvilCurrent "Front drive inverter: a012 hvil current";
CM_ SG_ 1318 DIF_a012_hvilFaultGpio "Front drive inverter: a012 hvil fault gpio";
CM_ SG_ 1318 DIF_a012_hvilSupplyPinDI "Front drive inverter: a012 hvil supply pin DI";
CM_ SG_ 1318 DIF_a012_hvilSupplyPinPM "Front drive inverter: a012 hvil supply pin PM";
CM_ SG_ 1318 DIF_a012_activeDisOn3V3 "Front drive inverter: a012 active dis on3 V3";
CM_ SG_ 1318 DIF_a012_hvilHeaderFault "Front drive inverter: a012 hvil header fault";
CM_ SG_ 1318 DIF_a013_address "Front drive inverter: a013 address";
CM_ SG_ 1318 DIF_a013_errorType "Front drive inverter: a013 error type";
CM_ SG_ 1318 DIF_a014_motorSpeed "Front drive inverter: a014 motor speed";
CM_ SG_ 1318 DIF_a014_adState "Front drive inverter: a014 ad state";
CM_ SG_ 1318 DIF_a014_torqueCommandFwd "Front drive inverter: a014 torque command fwd";
CM_ SG_ 1318 DIF_a014_brakeMasterCylPress "Front drive inverter: a014 brake master cyl press";
CM_ SG_ 1318 DIF_a014_rmsTorqueError "Front drive inverter: a014 rms torque error";
CM_ SG_ 1318 DIF_a014_tcEnabled "Front drive inverter: a014 tc enabled";
CM_ SG_ 1318 DIF_a016_newSafeState "Front drive inverter: a016 new safe state";
CM_ SG_ 1318 DIF_a016_oldSafeState "Front drive inverter: a016 old safe state";
CM_ SG_ 1318 DIF_a016_gateDriveFaultLine "Front drive inverter: a016 gate drive fault line";
CM_ SG_ 1318 DIF_a016_ascMonitor "Front drive inverter: a016 asc monitor";
CM_ SG_ 1318 DIF_a016_uncontrolledRegenZone "Front drive inverter: a016 uncontrolled regen zone";
CM_ SG_ 1318 DIF_a016_pedalMonitorPreWatchdog "Front drive inverter: a016 pedal monitor pre watchdog";
CM_ SG_ 1318 DIF_a016_motorRPM "Front drive inverter: a016 motor RPM";
CM_ SG_ 1318 DIF_a016_torqueMotor "Front drive inverter: a016 torque motor";
CM_ SG_ 1318 DIF_a016_safetyICfaultLine "Front drive inverter: a016 safety i cfault line";
CM_ SG_ 1318 DIF_a016_triggerEvent "Front drive inverter: a016 trigger event";
CM_ SG_ 1318 DIF_a024_vBat "Front drive inverter: a024 v bat";
CM_ SG_ 1318 DIF_a024_failReason "Front drive inverter: a024 fail reason";
CM_ SG_ 1318 DIF_a024_state "Front drive inverter: a024 state";
CM_ SG_ 1318 DIF_a024_Ia "Front drive inverter: a024 ia";
CM_ SG_ 1318 DIF_a024_Ib "Front drive inverter: a024 ib";
CM_ SG_ 1318 DIF_a024_maxCurrMagSqrd "Front drive inverter: a024 max curr mag sqrd";
CM_ SG_ 1318 DIF_a024_rotorAngle "Front drive inverter: a024 rotor angle";
CM_ SG_ 1318 DIF_a025_Ia "Front drive inverter: a025 ia";
CM_ SG_ 1318 DIF_a025_torqueMotor "Front drive inverter: a025 torque motor";
CM_ SG_ 1318 DIF_a025_motorSpeed "Front drive inverter: a025 motor speed";
CM_ SG_ 1318 DIF_a026_Ib "Front drive inverter: a026 ib";
CM_ SG_ 1318 DIF_a026_torqueMotor "Front drive inverter: a026 torque motor";
CM_ SG_ 1318 DIF_a026_motorSpeed "Front drive inverter: a026 motor speed";
CM_ SG_ 1318 DIF_a027_Ic "Front drive inverter: a027 ic";
CM_ SG_ 1318 DIF_a027_torqueMotor "Front drive inverter: a027 torque motor";
CM_ SG_ 1318 DIF_a027_motorSpeed "Front drive inverter: a027 motor speed";
CM_ SG_ 1318 DIF_a028_phaseAirms "Front drive inverter: a028 phase airms";
CM_ SG_ 1318 DIF_a028_iArmsTorque "Front drive inverter: a028 i arms torque";
CM_ SG_ 1318 DIF_a028_iArmsSpeed "Front drive inverter: a028 i arms speed";
CM_ SG_ 1318 DIF_a029_phaseBirms "Front drive inverter: a029 phase birms";
CM_ SG_ 1318 DIF_a029_iBrmsTorque "Front drive inverter: a029 i brms torque";
CM_ SG_ 1318 DIF_a029_iBrmsSpeed "Front drive inverter: a029 i brms speed";
CM_ SG_ 1318 DIF_a030_phaseCirms "Front drive inverter: a030 phase cirms";
CM_ SG_ 1318 DIF_a030_iCrmsTorque "Front drive inverter: a030 i crms torque";
CM_ SG_ 1318 DIF_a030_iCrmsSpeed "Front drive inverter: a030 i crms speed";
CM_ SG_ 1318 DIF_a031_phaseAoffset "Front drive inverter: a031 phase aoffset";
CM_ SG_ 1318 DIF_a032_phaseBoffset "Front drive inverter: a032 phase boffset";
CM_ SG_ 1318 DIF_a033_phaseAcurrent "Front drive inverter: a033 phase acurrent";
CM_ SG_ 1318 DIF_a033_deltaIa "Front drive inverter: a033 delta ia";
CM_ SG_ 1318 DIF_a033_vRefIa "Front drive inverter: a033 v ref ia";
CM_ SG_ 1318 DIF_a034_phaseBcurrent "Front drive inverter: a034 phase bcurrent";
CM_ SG_ 1318 DIF_a034_deltaIb "Front drive inverter: a034 delta ib";
CM_ SG_ 1318 DIF_a034_vRefIb "Front drive inverter: a034 v ref ib";
CM_ SG_ 1318 DIF_a035_phaseAerror "Front drive inverter: a035 phase aerror";
CM_ SG_ 1318 DIF_a035_phaseBerror "Front drive inverter: a035 phase berror";
CM_ SG_ 1318 DIF_a035_phaseCerror "Front drive inverter: a035 phase cerror";
CM_ SG_ 1318 DIF_a035_standbyCurrent "Front drive inverter: a035 standby current";
CM_ SG_ 1318 DIF_a035_unbalancedCurrent "Front drive inverter: a035 unbalanced current";
CM_ SG_ 1318 DIF_a035_wontMoveCurrent "Front drive inverter: a035 wont move current";
CM_ SG_ 1318 DIF_a035_reportingPhase "Front drive inverter: a035 reporting phase";
CM_ SG_ 1318 DIF_a035_noDriveCurrent "Front drive inverter: a035 no drive current";
CM_ SG_ 1318 DIF_a035_phaseDifference "Front drive inverter: a035 phase difference";
CM_ SG_ 1318 DIF_a035_phaseCurrent "Front drive inverter: a035 phase current";
CM_ SG_ 1318 DIF_a035_frequency "Front drive inverter: a035 frequency";
CM_ SG_ 1318 DIF_a036_busVoltage "Front drive inverter: a036 bus voltage";
CM_ SG_ 1318 DIF_a036_busHighLimit "Front drive inverter: a036 bus high limit";
CM_ SG_ 1318 DIF_a037_busVoltage "Front drive inverter: a037 bus voltage";
CM_ SG_ 1318 DIF_a037_busLowLimit "Front drive inverter: a037 bus low limit";
CM_ SG_ 1318 DIF_a038_vBMS "Front drive inverter: a038 v BMS";
CM_ SG_ 1318 DIF_a038_vBat "Front drive inverter: a038 v bat";
CM_ SG_ 1318 DIF_a038_iBat "Front drive inverter: a038 i bat";
CM_ SG_ 1318 DIF_a038_reason "Front drive inverter: a038 reason";
CM_ SG_ 1318 DIF_a040_torque "Front drive inverter: a040 torque";
CM_ SG_ 1318 DIF_a040_capability "Front drive inverter: a040 capability";
CM_ SG_ 1318 DIF_a040_power "Front drive inverter: a040 power";
CM_ SG_ 1318 DIF_a040_status "Front drive inverter: a040 status";
CM_ SG_ 1318 DIF_a040_capability2 "Front drive inverter: a040 capability2";
CM_ SG_ 1318 DIF_a040_hvStatus "Front drive inverter: a040 hv status";
CM_ SG_ 1318 DIF_a040_temperature "Front drive inverter: a040 temperature";
CM_ SG_ 1318 DIF_a041_uartRxDataAvailable "Front drive inverter: a041 uart rx data available";
CM_ SG_ 1318 DIF_a041_SDC_status_MIA "Front drive inverter: a041 SDC status MIA";
CM_ SG_ 1318 DIF_a041_diUartRxVersion "Front drive inverter: a041 di uart rx version";
CM_ SG_ 1318 DIF_a041_sdcUartRxVersion "Front drive inverter: a041 sdc uart rx version";
CM_ SG_ 1318 DIF_a043_outletTemp "Front drive inverter: a043 outlet temp";
CM_ SG_ 1318 DIF_a044_outletTemp "Front drive inverter: a044 outlet temp";
CM_ SG_ 1318 DIF_a045_inletTemp "Front drive inverter: a045 inlet temp";
CM_ SG_ 1318 DIF_a045_outletTemp "Front drive inverter: a045 outlet temp";
CM_ SG_ 1318 DIF_a045_heatsinkTemp "Front drive inverter: a045 heatsink temp";
CM_ SG_ 1318 DIF_a045_outletTempSlope "Front drive inverter: a045 outlet temp slope";
CM_ SG_ 1318 DIF_a046_statorTemp1 "Front drive inverter: a046 stator temp1";
CM_ SG_ 1318 DIF_a046_statorTemp2 "Front drive inverter: a046 stator temp2";
CM_ SG_ 1318 DIF_a047_statorTemp1 "Front drive inverter: a047 stator temp1";
CM_ SG_ 1318 DIF_a047_statorTslope1 "Front drive inverter: a047 stator tslope1";
CM_ SG_ 1318 DIF_a050_statorTemp1 "Front drive inverter: a050 stator temp1";
CM_ SG_ 1318 DIF_a050_statorTemp2 "Front drive inverter: a050 stator temp2";
CM_ SG_ 1318 DIF_a052_torque "Front drive inverter: a052 torque";
CM_ SG_ 1318 DIF_a052_capability "Front drive inverter: a052 capability";
CM_ SG_ 1318 DIF_a052_power "Front drive inverter: a052 power";
CM_ SG_ 1318 DIF_a052_status "Front drive inverter: a052 status";
CM_ SG_ 1318 DIF_a052_capability2 "Front drive inverter: a052 capability2";
CM_ SG_ 1318 DIF_a052_hvStatus "Front drive inverter: a052 hv status";
CM_ SG_ 1318 DIF_a052_temperature "Front drive inverter: a052 temperature";
CM_ SG_ 1318 DIF_a054_outletTemp "Front drive inverter: a054 outlet temp";
CM_ SG_ 1318 DIF_a054_heatsinkTemp "Front drive inverter: a054 heatsink temp";
CM_ SG_ 1318 DIF_a055_parameterDI "Front drive inverter: a055 parameter DI";
CM_ SG_ 1318 DIF_a055_parameterPM "Front drive inverter: a055 parameter PM";
CM_ SG_ 1318 DIF_a055_torqueType "Front drive inverter: a055 torque type";
CM_ SG_ 1318 DIF_a055_motorRPM "Front drive inverter: a055 motor RPM";
CM_ SG_ 1318 DIF_a056_pcbTemp "Front drive inverter: a056 pcb temp";
CM_ SG_ 1318 DIF_a057_pcbTemp "Front drive inverter: a057 pcb temp";
CM_ SG_ 1318 DIF_a058_pcbTemp "Front drive inverter: a058 pcb temp";
CM_ SG_ 1318 DIF_a058_outletTemp "Front drive inverter: a058 outlet temp";
CM_ SG_ 1318 DIF_a058_heatsinkTemp "Front drive inverter: a058 heatsink temp";
CM_ SG_ 1318 DIF_a058_pcbTempSlope "Front drive inverter: a058 pcb temp slope";
CM_ SG_ 1318 DIF_a059_heatsinkTemp "Front drive inverter: a059 heatsink temp";
CM_ SG_ 1318 DIF_a060_heatsinkTemp "Front drive inverter: a060 heatsink temp";
CM_ SG_ 1318 DIF_a061_sensor "Front drive inverter: a061 sensor";
CM_ SG_ 1318 DIF_a061_reason "Front drive inverter: a061 reason";
CM_ SG_ 1318 DIF_a061_phTemp "Front drive inverter: a061 ph temp";
CM_ SG_ 1318 DIF_a061_otherTemp "Front drive inverter: a061 other temp";
CM_ SG_ 1318 DIF_a062_limpReason "Front drive inverter: a062 limp reason";
CM_ SG_ 1318 DIF_a063_BB_status "Front drive inverter: a063 BB status";
CM_ SG_ 1318 DIF_a064_interventionType "Front drive inverter: a064 intervention type";
CM_ SG_ 1318 DIF_a064_torqueCmdState "Front drive inverter: a064 torque cmd state; raw 0 = signal not available (SNA)";
CM_ SG_ 1318 DIF_a066_badValue1 "Front drive inverter: a066 bad value1";
CM_ SG_ 1318 DIF_a066_badValue2 "Front drive inverter: a066 bad value2";
CM_ SG_ 1318 DIF_a066_canID "Front drive inverter: a066 can ID";
CM_ SG_ 1318 DIF_a066_errorType "Front drive inverter: a066 error type";
CM_ SG_ 1318 DIF_a069_motorSpeed "Front drive inverter: a069 motor speed";
CM_ SG_ 1318 DIF_a069_rotorCoolingPower "Front drive inverter: a069 rotor cooling power";
CM_ SG_ 1318 DIF_a069_rotorMagnetTemp "Front drive inverter: a069 rotor magnet temp";
CM_ SG_ 1318 DIF_a069_fittedTorqueLimit "Front drive inverter: a069 fitted torque limit";
CM_ SG_ 1318 DIF_a072_reason "Front drive inverter: a072 reason";
CM_ SG_ 1318 DIF_a073_motorSpeedrpm "Front drive inverter: a073 motor speedrpm";
CM_ SG_ 1318 DIF_a075_motorSpeed "Front drive inverter: a075 motor speed";
CM_ SG_ 1318 DIF_a075_absSpeed "Front drive inverter: a075 abs speed";
CM_ SG_ 1318 DIF_a076_lvSupplyV "Front drive inverter: a076 lv supply v";
CM_ SG_ 1318 DIF_a077_lvSupplyV "Front drive inverter: a077 lv supply v";
CM_ SG_ 1318 DIF_a078_adcRefChan "Front drive inverter: a078 adc ref chan";
CM_ SG_ 1318 DIF_a078_adcRefLowAvg "Front drive inverter: a078 adc ref low avg";
CM_ SG_ 1318 DIF_a079_adcRefChan "Front drive inverter: a079 adc ref chan";
CM_ SG_ 1318 DIF_a079_adcRefHighAvg "Front drive inverter: a079 adc ref high avg";
CM_ SG_ 1318 DIF_a087_gtwCarConfig "Front drive inverter: a087 gtw car config";
CM_ SG_ 1318 DIF_a087_gtwTime "Front drive inverter: a087 gtw time";
CM_ SG_ 1318 DIF_a087_gtwUpdateStatus "Front drive inverter: a087 gtw update status";
CM_ SG_ 1318 DIF_a087_gearControl "Front drive inverter: a087 gear control";
CM_ SG_ 1318 DIF_a087_carState "Front drive inverter: a087 car state";
CM_ SG_ 1318 DIF_a090_reason "Front drive inverter: a090 reason";
CM_ SG_ 1318 DIF_a090_systemState "Front drive inverter: a090 system state";
CM_ SG_ 1318 DIF_a090_state "Front drive inverter: a090 state";
CM_ SG_ 1318 DIF_a090_locState "Front drive inverter: a090 loc state";
CM_ SG_ 1318 DIF_a090_state2 "Front drive inverter: a090 state2";
CM_ SG_ 1318 DIF_a090_state4 "Front drive inverter: a090 state4";
CM_ SG_ 1318 DIF_a091_ESP_brakeTorque "Front drive inverter: a091 ESP brake torque";
CM_ SG_ 1318 DIF_a091_ESP_wheelSpeeds "Front drive inverter: a091 ESP wheel speeds";
CM_ SG_ 1318 DIF_a091_ESP_wheelRotation "Front drive inverter: a091 ESP wheel rotation";
CM_ SG_ 1318 DIF_a091_ESP_motorLimits "Front drive inverter: a091 ESP motor limits";
CM_ SG_ 1318 DIF_a091_ESP_offsets "Front drive inverter: a091 ESP offsets";
CM_ SG_ 1318 DIF_a091_ESP_status "Front drive inverter: a091 ESP status";
CM_ SG_ 1318 DIF_a091_ESP_party3 "Front drive inverter: a091 ESP party3";
CM_ SG_ 1318 DIF_a092_bmsStatus "Front drive inverter: a092 bms status";
CM_ SG_ 1318 DIF_a092_bmsDriveLimits "Front drive inverter: a092 bms drive limits";
CM_ SG_ 1318 DIF_a092_bmsHvBusStatus "Front drive inverter: a092 bms hv bus status";
CM_ SG_ 1318 DIF_a092_bmsPowerAvailable "Front drive inverter: a092 bms power available";
CM_ SG_ 1318 DIF_a092_bmsBmbMinMax "Front drive inverter: a092 bms bmb min max";
CM_ SG_ 1318 DIF_a092_bmsSocStatus "Front drive inverter: a092 bms soc status";
CM_ SG_ 1318 DIF_a092_bmsThermalStatus "Front drive inverter: a092 bms thermal status";
CM_ SG_ 1318 DIF_a092_bmsCtrStatus "Front drive inverter: a092 bms ctr status";
CM_ SG_ 1318 DIF_a092_bmsVoltageRegGain "Front drive inverter: a092 bms voltage reg gain";
CM_ SG_ 1318 DIF_a092_bmsPackConfig "Front drive inverter: a092 bms pack config";
CM_ SG_ 1318 DIF_a092_bmsSystemStatus "Front drive inverter: a092 bms system status";
CM_ SG_ 1318 DIF_a094_canID "Front drive inverter: a094 can ID";
CM_ SG_ 1318 DIF_a094_errorType "Front drive inverter: a094 error type";
CM_ SG_ 1318 DIF_a094_badValue1 "Front drive inverter: a094 bad value1";
CM_ SG_ 1318 DIF_a094_badValue2 "Front drive inverter: a094 bad value2";
CM_ SG_ 1318 DIF_a096_const_fast "Front drive inverter: a096 const fast";
CM_ SG_ 1318 DIF_a096_text_fast "Front drive inverter: a096 text fast";
CM_ SG_ 1318 DIF_a096_text_flash "Front drive inverter: a096 text flash";
CM_ SG_ 1318 DIF_a096_mem_data "Front drive inverter: a096 mem data";
CM_ SG_ 1318 DIF_a096_mem_regs "Front drive inverter: a096 mem regs";
CM_ SG_ 1318 DIF_a096_boot_flash "Front drive inverter: a096 boot flash";
CM_ SG_ 1318 DIF_a096_word1 "Front drive inverter: a096 word1";
CM_ SG_ 1318 DIF_a096_word2 "Front drive inverter: a096 word2";
CM_ SG_ 1318 DIF_a097_errorType "Front drive inverter: a097 error type";
CM_ SG_ 1318 DIF_a097_lineNumber "Front drive inverter: a097 line number";
CM_ SG_ 1318 DIF_a097_argument "Front drive inverter: a097 argument";
CM_ SG_ 1318 DIF_a098_pwmCount "Front drive inverter: a098 pwm count";
CM_ SG_ 1318 DIF_a098_fluxState "Front drive inverter: a098 flux state";
CM_ SG_ 1318 DIF_a103_fluidTorDeltaT "Front drive inverter: a103 fluid tor delta t";
CM_ SG_ 1318 DIF_a103_noFlowDetected "Front drive inverter: a103 no flow detected";
CM_ SG_ 1318 DIF_a103_lowFlowDetected "Front drive inverter: a103 low flow detected";
CM_ SG_ 1318 DIF_a103_fluidImplausible "Front drive inverter: a103 fluid implausible";
CM_ SG_ 1318 DIF_a103_inverterTemp "Front drive inverter: a103 inverter temp";
CM_ SG_ 1318 DIF_a103_rmsCurrent "Front drive inverter: a103 rms current";
CM_ SG_ 1318 DIF_a103_ambientTemp "Front drive inverter: a103 ambient temp";
CM_ SG_ 1318 DIF_a103_sensorTempEst "Front drive inverter: a103 sensor temp est";
CM_ SG_ 1318 DIF_a107_fpgaVersion "Front drive inverter: a107 fpga version";
CM_ SG_ 1318 DIF_a107_fpgaBootVersion "Front drive inverter: a107 fpga boot version";
CM_ SG_ 1318 DIF_a107_fpgaMasterActive "Front drive inverter: a107 fpga master active";
CM_ SG_ 1318 DIF_a107_fpgaFaultActive "Front drive inverter: a107 fpga fault active";
CM_ SG_ 1318 DIF_a107_fpgaWarningActive "Front drive inverter: a107 fpga warning active";
CM_ SG_ 1318 DIF_a108_fromState "Front drive inverter: a108 from state";
CM_ SG_ 1318 DIF_a108_toState "Front drive inverter: a108 to state";
CM_ SG_ 1318 DIF_a108_blockingAlert "Front drive inverter: a108 blocking alert";
CM_ SG_ 1318 DIF_a110_EPBL_status "Front drive inverter: a110 EPBL status";
CM_ SG_ 1318 DIF_a110_EPBR_status "Front drive inverter: a110 EPBR status";
CM_ SG_ 1318 DIF_a111_phAcalib "Front drive inverter: a111 ph acalib";
CM_ SG_ 1318 DIF_a111_phBcalib "Front drive inverter: a111 ph bcalib";
CM_ SG_ 1318 DIF_a112_phaseAcurrent "Front drive inverter: a112 phase acurrent";
CM_ SG_ 1318 DIF_a112_phaseBcurrent "Front drive inverter: a112 phase bcurrent";
CM_ SG_ 1318 DIF_a113_heatsink1Temp "Front drive inverter: a113 heatsink1 temp";
CM_ SG_ 1318 DIF_a113_heatsink2Temp "Front drive inverter: a113 heatsink2 temp";
CM_ SG_ 1318 DIF_a113_heatsink3Temp "Front drive inverter: a113 heatsink3 temp";
CM_ SG_ 1318 DIF_a115_faultAddress "Front drive inverter: a115 fault address";
CM_ SG_ 1318 DIF_a115_isWriteNotRead "Front drive inverter: a115 is write not read";
CM_ SG_ 1318 DIF_a117_torque "Front drive inverter: a117 torque";
CM_ SG_ 1318 DIF_a117_slaveCommand "Front drive inverter: a117 slave command";
CM_ SG_ 1318 DIF_a117_power "Front drive inverter: a117 power";
CM_ SG_ 1318 DIF_a117_slaveCommand2 "Front drive inverter: a117 slave command2";
CM_ SG_ 1318 DIF_a117_speed "Front drive inverter: a117 speed";
CM_ SG_ 1318 DIF_a117_chassisControl "Front drive inverter: a117 chassis control";
CM_ SG_ 1318 DIF_a117_systemStatus "Front drive inverter: a117 system status";
CM_ SG_ 1318 DIF_a117_temperature "Front drive inverter: a117 temperature";
CM_ SG_ 1318 DIF_a117_vehicle "Front drive inverter: a117 vehicle";
CM_ SG_ 1318 DIF_a117_AddTcLimit "Front drive inverter: a117 add tc limit";
CM_ SG_ 1318 DIF_a117_dixCommand "Front drive inverter: a117 dix command";
CM_ SG_ 1318 DIF_a117_odometerStatus "Front drive inverter: a117 odometer status";
CM_ SG_ 1318 DIF_a117_maxRatedPower "Front drive inverter: a117 max rated power";
CM_ SG_ 1318 DIF_a119_hvpFaults "Front drive inverter: a119 hvp faults";
CM_ SG_ 1318 DIF_a120_dcLinkInfo "Front drive inverter: a120 dc link info";
CM_ SG_ 1318 DIF_a121_badRegReason "Front drive inverter: a121 bad reg reason";
CM_ SG_ 1318 DIF_a121_torqueDelta "Front drive inverter: a121 torque delta";
CM_ SG_ 1318 DIF_a121_badCurrent "Front drive inverter: a121 bad current";
CM_ SG_ 1318 DIF_a121_badFlux "Front drive inverter: a121 bad flux";
CM_ SG_ 1318 DIF_a123_lossReason "Front drive inverter: a123 loss reason";
CM_ SG_ 1318 DIF_a123_busVoltage "Front drive inverter: a123 bus voltage";
CM_ SG_ 1318 DIF_a123_badFlux "Front drive inverter: a123 bad flux";
CM_ SG_ 1318 DIF_a123_lossRequest "Front drive inverter: a123 loss request";
CM_ SG_ 1318 DIF_a123_badCurrent "Front drive inverter: a123 bad current";
CM_ SG_ 1318 DIF_a123_motorRPM "Front drive inverter: a123 motor RPM";
CM_ SG_ 1318 DIF_a123_varianceD "Front drive inverter: a123 variance d";
CM_ SG_ 1318 DIF_a123_varianceQ "Front drive inverter: a123 variance q";
CM_ SG_ 1318 DIF_a126_limpReason "Front drive inverter: a126 limp reason";
CM_ SG_ 1318 DIF_a127_gpoReason "Front drive inverter: a127 gpo reason";
CM_ SG_ 1318 DIF_a127_temp "Front drive inverter: a127 temp";
CM_ SG_ 1318 DIF_a133_capacitorTemp "Front drive inverter: a133 capacitor temp";
CM_ SG_ 1318 DIF_a133_badValue1 "Front drive inverter: a133 bad value1";
CM_ SG_ 1318 DIF_a133_badValue2 "Front drive inverter: a133 bad value2";
CM_ SG_ 1318 DIF_a134_wheelSpeedDiffFrL "Front drive inverter: a134 wheel speed diff fr l";
CM_ SG_ 1318 DIF_a134_wheelSpeedDiffFrR "Front drive inverter: a134 wheel speed diff fr r";
CM_ SG_ 1318 DIF_a134_wheelSpeedDiffReL "Front drive inverter: a134 wheel speed diff re l";
CM_ SG_ 1318 DIF_a134_wheelSpeedDiffReR "Front drive inverter: a134 wheel speed diff re r";
CM_ SG_ 1318 DIF_a136_spiError_BL "Front drive inverter: a136 spi error BL";
CM_ SG_ 1318 DIF_a136_crcError_BL "Front drive inverter: a136 crc error BL";
CM_ SG_ 1318 DIF_a136_busyError_BL "Front drive inverter: a136 busy error BL";
CM_ SG_ 1318 DIF_a136_spiError_BH "Front drive inverter: a136 spi error BH";
CM_ SG_ 1318 DIF_a136_crcError_BH "Front drive inverter: a136 crc error BH";
CM_ SG_ 1318 DIF_a136_busyError_BH "Front drive inverter: a136 busy error BH";
CM_ SG_ 1318 DIF_a136_spiError_CL "Front drive inverter: a136 spi error CL";
CM_ SG_ 1318 DIF_a136_crcError_CL "Front drive inverter: a136 crc error CL";
CM_ SG_ 1318 DIF_a136_busyError_CL "Front drive inverter: a136 busy error CL";
CM_ SG_ 1318 DIF_a136_spiError_CH "Front drive inverter: a136 spi error CH";
CM_ SG_ 1318 DIF_a136_crcError_CH "Front drive inverter: a136 crc error CH";
CM_ SG_ 1318 DIF_a136_busyError_CH "Front drive inverter: a136 busy error CH";
CM_ SG_ 1318 DIF_a136_spiError_AL "Front drive inverter: a136 spi error AL";
CM_ SG_ 1318 DIF_a136_crcError_AL "Front drive inverter: a136 crc error AL";
CM_ SG_ 1318 DIF_a136_busyError_AL "Front drive inverter: a136 busy error AL";
CM_ SG_ 1318 DIF_a136_spiError_AH "Front drive inverter: a136 spi error AH";
CM_ SG_ 1318 DIF_a136_crcError_AH "Front drive inverter: a136 crc error AH";
CM_ SG_ 1318 DIF_a136_busyError_AH "Front drive inverter: a136 busy error AH";
CM_ SG_ 1318 DIF_a144_autopilot "Front drive inverter: a144 autopilot";
CM_ SG_ 1318 DIF_a144_chassisType "Front drive inverter: a144 chassis type";
CM_ SG_ 1318 DIF_a144_drivetrainType "Front drive inverter: a144 drivetrain type";
CM_ SG_ 1318 DIF_a144_packEnergy "Front drive inverter: a144 pack energy";
CM_ SG_ 1318 DIF_a144_packPerformanceDeviatio "Front drive inverter: a144 pack performance deviation";
CM_ SG_ 1318 DIF_a144_performancePackage "Front drive inverter: a144 performance package";
CM_ SG_ 1318 DIF_a144_vdcType "Front drive inverter: a144 vdc type";
CM_ SG_ 1318 DIF_a144_brakeHWType "Front drive inverter: a144 brake HW type";
CM_ SG_ 1318 DIF_a144_inverterHardware "Front drive inverter: a144 inverter hardware";
CM_ SG_ 1318 DIF_a144_cabinPTCHeaterType "Front drive inverter: a144 cabin PTC heater type";
CM_ SG_ 1318 DIF_a144_frunkLatchType "Front drive inverter: a144 frunk latch type";
CM_ SG_ 1318 DIF_a144_platformMaxBusVoltage "Front drive inverter: a144 platform max bus voltage";
CM_ SG_ 1318 DIF_a144_oilPump1HwType "Front drive inverter: a144 oil pump1 hw type";
CM_ SG_ 1318 DIF_a144_oilPump2HwType "Front drive inverter: a144 oil pump2 hw type";
CM_ SG_ 1318 DIF_a144_heatsinkType "Front drive inverter: a144 heatsink type";
CM_ SG_ 1318 DIF_a144_softPerformanceLimit "Front drive inverter: a144 soft performance limit";
CM_ SG_ 1318 DIF_a144_brakeActuationType "Front drive inverter: a144 brake actuation type";
CM_ SG_ 1318 DIF_a144_dasHw "Front drive inverter: a144 das hw";
CM_ SG_ 1318 DIF_a144_chassisSubType "Front drive inverter: a144 chassis sub type";
CM_ SG_ 1318 DIF_a147_overtorque1UsedCount "Front drive inverter: a147 overtorque1 used count";
CM_ SG_ 1318 DIF_a147_overtorque2UsedCount "Front drive inverter: a147 overtorque2 used count";
CM_ SG_ 1318 DIF_a147_accumulatedWear "Front drive inverter: a147 accumulated wear";
CM_ SG_ 1318 DIF_a147_wearIsValid "Front drive inverter: a147 wear is valid";
CM_ SG_ 1318 DIF_a149_flow "Front drive inverter: a149 flow; raw 255 = signal not available (SNA)";
CM_ SG_ 1318 DIF_a149_voltage "Front drive inverter: a149 voltage";
CM_ SG_ 1318 DIF_a149_temperature "Front drive inverter: a149 temperature";
CM_ SG_ 1318 DIF_a149_state "Front drive inverter: a149 state; raw 7 = signal not available (SNA)";
CM_ SG_ 1318 DIF_a149_fluidTempSNA "Front drive inverter: a149 fluid temp SNA";
CM_ SG_ 1318 DIF_a149_insufficientFlow "Front drive inverter: a149 insufficient flow";
CM_ SG_ 1318 DIF_a149_motorOpenPhase "Front drive inverter: a149 motor open phase";
CM_ SG_ 1318 DIF_a149_motorShorted "Front drive inverter: a149 motor shorted";
CM_ SG_ 1318 DIF_a149_motorFlowSNA "Front drive inverter: a149 motor flow SNA";
CM_ SG_ 1318 DIF_a149_responseError "Front drive inverter: a149 response error";
CM_ SG_ 1318 DIF_a149_pcbaID "Front drive inverter: a149 pcba ID";
CM_ SG_ 1318 DIF_a150_vBatRawMinusFiltered "Front drive inverter: a150 v bat raw minus filtered";
CM_ SG_ 1318 DIF_a150_vBatFilteredRate "Front drive inverter: a150 v bat filtered rate";
CM_ SG_ 1318 DIF_a150_elapsedMs "Front drive inverter: a150 elapsed ms";
CM_ SG_ 1318 DIF_a150_energy "Front drive inverter: a150 energy";
CM_ SG_ 1318 DIF_a152_errorType "Front drive inverter: a152 error type";
CM_ SG_ 1318 DIF_a152_frameId "Front drive inverter: a152 frame id";
CM_ SG_ 1318 DIF_a152_badValue "Front drive inverter: a152 bad value";
CM_ SG_ 1318 DIF_a152_expectedValue "Front drive inverter: a152 expected value";
CM_ SG_ 1318 DIF_a153_oilFlow "Front drive inverter: a153 oil flow; raw 255 = signal not available (SNA)";
CM_ SG_ 1318 DIF_a153_oilTemperature "Front drive inverter: a153 oil temperature; raw 255 = signal not available (SNA)";
CM_ SG_ 1318 DIF_a153_phaseCurrent "Front drive inverter: a153 phase current; raw 255 = signal not available (SNA)";
CM_ SG_ 1318 DIF_a153_dcVoltage "Front drive inverter: a153 dc voltage; raw 255 = signal not available (SNA)";
CM_ SG_ 1318 DIF_a153_lowPressPlausibility "Front drive inverter: a153 low press plausibility";
CM_ SG_ 1318 DIF_a153_state "Front drive inverter: a153 state; raw 7 = signal not available (SNA)";
CM_ SG_ 1318 DIF_a153_oilPumpAlert "Front drive inverter: a153 oil pump alert";
CM_ SG_ 1318 DIF_a153_reason "Front drive inverter: a153 reason";
CM_ SG_ 1318 DIF_a154_motorRPM "Front drive inverter: a154 motor RPM";
CM_ SG_ 1318 DIF_a154_phaseError "Front drive inverter: a154 phase error";
CM_ SG_ 1318 DIF_a154_commonGain "Front drive inverter: a154 common gain";
CM_ SG_ 1318 DIF_a154_noCalibration "Front drive inverter: a154 no calibration";
CM_ SG_ 1318 DIF_a154_noPhaseLock "Front drive inverter: a154 no phase lock";
CM_ SG_ 1318 DIF_a154_noCarrier "Front drive inverter: a154 no carrier";
CM_ SG_ 1318 DIF_a154_notReady "Front drive inverter: a154 not ready";
CM_ SG_ 1318 DIF_a154_errorTableInvalid "Front drive inverter: a154 error table invalid";
CM_ SG_ 1318 DIF_a154_carrierOffset "Front drive inverter: a154 carrier offset";
CM_ SG_ 1318 DIF_a154_trackerIrrational "Front drive inverter: a154 tracker irrational";
CM_ SG_ 1318 DIF_a154_claMIA "Front drive inverter: a154 cla MIA";
CM_ SG_ 1318 DIF_a155_sensors "Front drive inverter: a155 sensors";
CM_ SG_ 1318 DIF_a155_coolant "Front drive inverter: a155 coolant";
CM_ SG_ 1318 DIF_a155_LVPowerState "Front drive inverter: a155 LV power state";
CM_ SG_ 1318 DIF_a155_vehicleStatus "Front drive inverter: a155 vehicle status";
CM_ SG_ 1318 DIF_a155_status "Front drive inverter: a155 status";
CM_ SG_ 1318 DIF_a155_leftDoorStatus "Front drive inverter: a155 left door status";
CM_ SG_ 1318 DIF_a155_rightDoorStatus "Front drive inverter: a155 right door status";
CM_ SG_ 1318 DIF_a155_vcleftSwitchStatus "Front drive inverter: a155 vcleft switch status";
CM_ SG_ 1318 DIF_a155_restraintStatus "Front drive inverter: a155 restraint status";
CM_ SG_ 1318 DIF_a155_systemStatus "Front drive inverter: a155 system status";
CM_ SG_ 1318 DIF_a155_prndStatus "Front drive inverter: a155 prnd status";
CM_ SG_ 1318 DIF_a155_liftgateStatus "Front drive inverter: a155 liftgate status";
CM_ SG_ 1318 DIF_a157_RCM_inertial1 "Front drive inverter: a157 RCM inertial1";
CM_ SG_ 1318 DIF_a157_RCM_inertial2 "Front drive inverter: a157 RCM inertial2";
CM_ SG_ 1318 DIF_a158_IBST_party1 "Front drive inverter: a158 IBST party1";
CM_ SG_ 1318 DIF_a158_BUS1_IBST_status "Front drive inverter: a158 BUS1 IBST status";
CM_ SG_ 1318 DIF_a158_BUS2_IBST_status "Front drive inverter: a158 BUS2 IBST status";
CM_ SG_ 1318 DIF_a160_vBatRawMinusFiltered "Front drive inverter: a160 v bat raw minus filtered";
CM_ SG_ 1318 DIF_a160_vBatFilteredRate "Front drive inverter: a160 v bat filtered rate";
CM_ SG_ 1318 DIF_a160_elapsedMs "Front drive inverter: a160 elapsed ms";
CM_ SG_ 1318 DIF_a160_energy "Front drive inverter: a160 energy";
CM_ SG_ 1318 DIF_a161_EPAS3P_sysStatus "Front drive inverter: a161 EPAS3 p sys status";
CM_ SG_ 1318 DIF_a161_EPAS3P_angleCalib "Front drive inverter: a161 EPAS3 p angle calib";
CM_ SG_ 1318 DIF_a202_reason "Front drive inverter: a202 reason";
CM_ SG_ 1318 DIF_a202_movement "Front drive inverter: a202 movement";
CM_ SG_ 1318 DIF_a202_sysStateExitCondition "Front drive inverter: a202 sys state exit condition";
CM_ SG_ 1318 DIF_a233_missedMsgCount "Front drive inverter: a233 missed msg count";
CM_ SG_ 1318 DIF_a233_serviceModeActive "Signal reported by Front drive inverter";
CM_ SG_ 1318 DIF_a234_PCS_dcdcStatus "Front drive inverter: a234 PCS dcdc status";
CM_ SG_ 1318 DIF_a236_states "Front drive inverter: a236 states";
CM_ SG_ 1318 DIF_a242_RotorOffset "Front drive inverter: a242 rotor offset";
CM_ SG_ 1318 DIF_a242_RotorFlux "Front drive inverter: a242 rotor flux";
CM_ SG_ 1318 DIF_a242_ResolverError "Front drive inverter: a242 resolver error";
CM_ SG_ 1318 DIF_a244_desatHighSide "Front drive inverter: a244 desat high side";
CM_ SG_ 1318 DIF_a244_desatLowSide "Front drive inverter: a244 desat low side";
CM_ SG_ 1318 DIF_a244_singleSwitchShort "Front drive inverter: a244 single switch short";
CM_ SG_ 1318 DIF_a244_flybackFault "Front drive inverter: a244 flyback fault";
CM_ SG_ 1318 DIF_a244_postShortTestFailed "Front drive inverter: a244 post short test failed";
CM_ SG_ 1318 DIF_a244_udsSelfTest "Front drive inverter: a244 uds self test";
CM_ SG_ 1318 DIF_a244_irSensorV "Front drive inverter: a244 ir sensor v";
CM_ SG_ 1318 DIF_a244_gateDriveICUndervoltage "Front drive inverter: a244 gate drive IC undervoltage";
CM_ SG_ 1318 DIF_a244_plausibleSingleSwitchSh "Front drive inverter: a244 plausible single switch short only";
CM_ SG_ 1318 DIF_a246_atSpeedDIResetCount "Front drive inverter: a246 at speed DI reset count";
CM_ SG_ 1318 DIF_a246_didPMCauseASC "Front drive inverter: a246 did PM cause ASC";
CM_ SG_ 1318 DIF_a246_currentSensorRational "Front drive inverter: a246 current sensor rational";
CM_ SG_ 1318 DIF_a246_observerDetectedLS3PS "Front drive inverter: a246 observer detected LS3 PS";
CM_ SG_ 1318 DIF_a246_hvIsGood "Front drive inverter: a246 hv is good";
CM_ SG_ 1318 DIF_a246_lvIsGood "Front drive inverter: a246 lv is good";
CM_ SG_ 1318 DIF_a246_codeBranch "Front drive inverter: a246 code branch";
CM_ SG_ 1318 DIF_a246_motorRPM "Front drive inverter: a246 motor RPM";
CM_ SG_ 1318 DIF_a246_eepromOffsetIa "Front drive inverter: a246 eeprom offset ia";
CM_ SG_ 1318 DIF_a246_eepromOffsetIb "Front drive inverter: a246 eeprom offset ib";
CM_ SG_ 1318 DIF_a247_rotorOffsetEst "Front drive inverter: a247 rotor offset est";
CM_ SG_ 1318 DIF_a247_motorRPM "Front drive inverter: a247 motor RPM";
CM_ SG_ 1318 DIF_a247_torqueMotor "Front drive inverter: a247 torque motor";
CM_ SG_ 1318 DIF_a251_oilFlow "Front drive inverter: a251 oil flow; raw 255 = signal not available (SNA)";
CM_ SG_ 1318 DIF_a251_oilTemperature "Front drive inverter: a251 oil temperature; raw 255 = signal not available (SNA)";
CM_ SG_ 1318 DIF_a251_dcVoltage "Front drive inverter: a251 dc voltage; raw 255 = signal not available (SNA)";
CM_ SG_ 1318 DIF_a251_dcCurrent "Front drive inverter: a251 dc current; raw 255 = signal not available (SNA)";
CM_ SG_ 1318 DIF_a251_phaseCurrent "Front drive inverter: a251 phase current; raw 255 = signal not available (SNA)";
CM_ SG_ 1318 DIF_a251_leadAngle "Front drive inverter: a251 lead angle";
CM_ SG_ 1318 DIF_a251_reason "Front drive inverter: a251 reason";
CM_ BO_ 634 "Front drive inverter message: hv status";
CM_ SG_ 634 DIF_hvStatusChecksum "Front drive inverter: hv status checksum";
CM_ SG_ 634 DIF_hvStatusCounter "Front drive inverter: hv status counter";
CM_ SG_ 634 DIF_hvilCurrent "HVIL Current";
CM_ SG_ 634 DIF_hvilCmVoltage "HVIL Common Mode Voltage";
CM_ SG_ 634 DIF_hvilStatus "Aggregated hardware and measured HVIL unit status; raw 3 = signal not available (SNA)";
CM_ SG_ 634 DIF_hvilSupplyState "Front drive inverter: hvil supply state";
CM_ SG_ 634 DIF_activeDischargeCtrl "Front drive inverter: active discharge ctrl";
CM_ SG_ 634 DIF_activeDischargeStatus "Active discharge status from HVIL_FAULT signal.";
CM_ SG_ 634 DIF_vBat "Reports the battery voltage measured by the Drive Inverter's local Analog to Digital Converter (ADC).";
CM_ SG_ 634 DIF_vBatQF "Front drive inverter: v bat QF";
CM_ SG_ 634 DIF_powerStageSafeState "Front drive inverter: power stage safe state";
CM_ SG_ 634 DIF_fluxState "Front drive inverter: flux state";
CM_ SG_ 634 DIF_vBusDiag "Front drive inverter: v bus diag";
CM_ SG_ 634 DIF_gateDriveState "Front drive inverter: gate drive state";
CM_ BO_ 741 "Front drive inverter message: power";
CM_ SG_ 741 DIF_elecPower "Front drive inverter: elec power; raw 1024 = signal not available (SNA)";
CM_ SG_ 741 DIF_heatPowerOptimal "Front drive inverter: heat power optimal";
CM_ SG_ 741 DIF_heatPowerMax "Drive Inverter maximum heat power capability";
CM_ SG_ 741 DIF_heatPowerActual "Drive Inverter heat power";
CM_ SG_ 741 DIF_excessHeatCommand "Drive Inverter excess heat command";
CM_ SG_ 741 DIF_drivePowerMax "Front drive inverter: drive power max; raw 511 = signal not available (SNA)";
BA_DEF_ BO_ "GenMsgCycleTime" INT 0 3600000;
BA_DEF_ BO_ "GenMsgSendType" ENUM "Cyclic","NotUsed","NotUsed","NotUsed","NotUsed","NotUsed","NotUsed","IfActive","NoMsgSendType","NotUsed";
BA_DEF_ BO_ "VFrameFormat" ENUM "StandardCAN","ExtendedCAN","reserved","J1939PG","reserved","reserved","reserved","reserved","reserved","reserved","reserved","reserved","reserved","reserved","StandardCAN_FD","ExtendedCAN_FD";
BA_DEF_ BO_ "CANFD_BRS" ENUM "0","1";
BA_DEF_ SG_ "GenSigSNA" STRING;
BA_DEF_ SG_ "SystemSignalLongSymbol" STRING;
BA_DEF_ SG_ "Confidence" ENUM "validated","plausible","layout-only","contradicted";
BA_DEF_DEF_ "GenMsgCycleTime" 0;
BA_DEF_DEF_ "GenMsgSendType" "NoMsgSendType";
BA_DEF_DEF_ "VFrameFormat" "StandardCAN";
BA_DEF_DEF_ "CANFD_BRS" "1";
BA_DEF_DEF_ "GenSigSNA" "";
BA_DEF_DEF_ "SystemSignalLongSymbol" "";
BA_DEF_DEF_ "Confidence" "layout-only";
BA_ "GenMsgCycleTime" BO_ 798 1000;
BA_ "GenMsgSendType" BO_ 798 0;
BA_ "GenMsgCycleTime" BO_ 669 100;
BA_ "GenMsgSendType" BO_ 669 0;
BA_ "GenMsgCycleTime" BO_ 541 100;
BA_ "GenMsgSendType" BO_ 541 0;
BA_ "GenMsgCycleTime" BO_ 1342 1000;
BA_ "GenMsgSendType" BO_ 1342 0;
BA_ "GenMsgCycleTime" BO_ 1885 200;
BA_ "GenMsgSendType" BO_ 1885 0;
BA_ "GenMsgCycleTime" BO_ 989 1000;
BA_ "GenMsgSendType" BO_ 989 0;
BA_ "GenMsgCycleTime" BO_ 605 100;
BA_ "GenMsgSendType" BO_ 605 0;
BA_ "GenMsgCycleTime" BO_ 893 1000;
BA_ "GenMsgSendType" BO_ 893 0;
BA_ "GenMsgCycleTime" BO_ 1001 500;
BA_ "GenMsgSendType" BO_ 1001 0;
BA_ "GenMsgCycleTime" BO_ 634 100;
BA_ "GenMsgSendType" BO_ 634 0;
BA_ "GenMsgCycleTime" BO_ 741 1000;
BA_ "GenMsgSendType" BO_ 741 0;
BA_ "Confidence" SG_ 798 CP_matrixIndex 1;
BA_ "SystemSignalLongSymbol" SG_ 798 CP_a112_inletHeaterIrrationalTem "CP_a112_inletHeaterIrrationalTemperature";
BA_ "SystemSignalLongSymbol" SG_ 798 CP_a117_inletHeaterUnableToRegul "CP_a117_inletHeaterUnableToRegulate";
BA_ "SystemSignalLongSymbol" SG_ 798 CP_a162_pilotEdgeDetectionFailed "CP_a162_pilotEdgeDetectionFailedCN";
BA_ "SystemSignalLongSymbol" SG_ 798 CP_a164_latchRedisengageRequeste "CP_a164_latchRedisengageRequested";
BA_ "SystemSignalLongSymbol" SG_ 798 CP_a166_faultLineMismatchDetecte "CP_a166_faultLineMismatchDetected";
BA_ "SystemSignalLongSymbol" SG_ 798 CP_a177_incompatibleV2lDeviceDet "CP_a177_incompatibleV2lDeviceDetected";
BA_ "Confidence" SG_ 669 CP_evseOutputDcCurrent 0;
BA_ "Confidence" SG_ 669 CP_evseOutputDcVoltage 0;
BA_ "Confidence" SG_ 669 CP_evseOutputDcCurrentStale 0;
BA_ "Confidence" SG_ 541 CP_evseAccept 0;
BA_ "Confidence" SG_ 541 CP_evseRequest 0;
BA_ "Confidence" SG_ 541 CP_proximity 0;
BA_ "GenSigSNA" SG_ 541 CP_proximity "0";
BA_ "Confidence" SG_ 541 CP_pilot 0;
BA_ "GenSigSNA" SG_ 541 CP_pilot "7";
BA_ "Confidence" SG_ 541 CP_digitalCommsEstablished 0;
BA_ "Confidence" SG_ 541 CP_pilotCurrent 0;
BA_ "Confidence" SG_ 541 CP_cableType 0;
BA_ "GenSigSNA" SG_ 541 CP_cableType "4";
BA_ "Confidence" SG_ 541 CP_iecPilotState 0;
BA_ "GenSigSNA" SG_ 541 CP_iecPilotState "9";
BA_ "Confidence" SG_ 541 CP_plcSupported 0;
BA_ "Confidence" SG_ 541 CP_cableCurrentLimit 0;
BA_ "Confidence" SG_ 541 CP_teslaSwcanState 0;
BA_ "Confidence" SG_ 541 CP_evseChargeType_UI 0;
BA_ "Confidence" SG_ 541 CP_gbState 0;
BA_ "Confidence" SG_ 541 CP_gbdcStopChargeReason 0;
BA_ "Confidence" SG_ 541 CP_gbdcFailureReason 0;
BA_ "Confidence" SG_ 541 CP_gbdcChargeAttempts 0;
BA_ "Confidence" SG_ 541 CP_acChargeState 0;
BA_ "Confidence" SG_ 541 CP_teslaDcState 1;
BA_ "Confidence" SG_ 1342 CP_infoIndex 1;
BA_ "Confidence" SG_ 1342 CP_buildType 0;
BA_ "Confidence" SG_ 1342 CP_buildConfigId 0;
BA_ "Confidence" SG_ 1342 CP_hardwareId 0;
BA_ "Confidence" SG_ 1342 CP_componentId 0;
BA_ "Confidence" SG_ 1342 CP_pcbaId 0;
BA_ "Confidence" SG_ 1342 CP_assemblyId 0;
BA_ "Confidence" SG_ 1342 CP_usageId 0;
BA_ "Confidence" SG_ 1342 CP_subUsageId 0;
BA_ "Confidence" SG_ 1342 CP_platformType 0;
BA_ "Confidence" SG_ 1342 CP_appCrc 0;
BA_ "Confidence" SG_ 1342 CP_appGitHash 0;
BA_ "Confidence" SG_ 1342 CP_bootGitHash 0;
BA_ "Confidence" SG_ 1342 CP_bootUdsProtoVersion 0;
BA_ "Confidence" SG_ 1342 CP_bootCrc 0;
BA_ "Confidence" SG_ 1885 CP_loggingFastSelect 1;
BA_ "Confidence" SG_ 1885 CP_inductiveSensor_raw 0;
BA_ "Confidence" SG_ 1885 CP_doorOpenActuationTime 0;
BA_ "Confidence" SG_ 1885 CP_doorCloseActuationTime 0;
BA_ "Confidence" SG_ 1885 CP_chargeCableSecured 0;
BA_ "Confidence" SG_ 1885 CP_chargeCablePresent 0;
BA_ "Confidence" SG_ 1885 CP_latchCheckAvailable 0;
BA_ "Confidence" SG_ 1885 CP_UHF_controlState 0;
BA_ "Confidence" SG_ 1885 CP_proximityV 0;
BA_ "Confidence" SG_ 1885 CP_proximityV_GBCC1 0;
BA_ "Confidence" SG_ 1885 CP_proximityV_GBCC2 0;
BA_ "Confidence" SG_ 1885 CP_doorPot 0;
BA_ "Confidence" SG_ 1885 CP_doorPresenceHallSensorV 1;
BA_ "Confidence" SG_ 1885 CP_doorOpenRequest 0;
BA_ "Confidence" SG_ 1885 CP_doorOpenEndOfDriveReason 0;
BA_ "Confidence" SG_ 1885 CP_coverClosed 0;
BA_ "Confidence" SG_ 1885 CP_doorCloseEndOfDriveReason 0;
BA_ "Confidence" SG_ 1885 CP_doorCloseRequest 0;
BA_ "Confidence" SG_ 1885 CP_latchDisengagingTime 0;
BA_ "Confidence" SG_ 1885 CP_latchEngagingTime 0;
BA_ "Confidence" SG_ 1885 CP_latchDisengagingStopReason 0;
BA_ "Confidence" SG_ 1885 CP_latchEngagingStopReason 1;
BA_ "Confidence" SG_ 1885 CP_doorIdDetectionState 0;
BA_ "GenSigSNA" SG_ 1885 CP_doorIdDetectionState "0";
BA_ "Confidence" SG_ 1885 CP_doorIdDetectedBin 0;
BA_ "Confidence" SG_ 989 CP_loggingSlowSelect 1;
BA_ "Confidence" SG_ 989 CP_UHF_chipState 0;
BA_ "Confidence" SG_ 989 CP_UHF_rssi 0;
BA_ "Confidence" SG_ 989 CP_UHF_rxOverflow 0;
BA_ "Confidence" SG_ 989 CP_UHF_rxNumBytes 0;
BA_ "Confidence" SG_ 989 CP_UHF_selfTestRssi 0;
BA_ "Confidence" SG_ 989 CP_latchI 0;
BA_ "Confidence" SG_ 989 CP_inlet1HarnessIdState 0;
BA_ "GenSigSNA" SG_ 989 CP_inlet1HarnessIdState "0";
BA_ "Confidence" SG_ 989 CP_inlet1HarnessIdValue 0;
BA_ "Confidence" SG_ 989 CP_inlet2HarnessIdState 0;
BA_ "GenSigSNA" SG_ 989 CP_inlet2HarnessIdState "0";
BA_ "Confidence" SG_ 989 CP_inlet2HarnessIdValue 0;
BA_ "Confidence" SG_ 989 CP_inletHeaterState 0;
BA_ "Confidence" SG_ 989 CP_inletHeaterDuty 0;
BA_ "Confidence" SG_ 989 CP_nvm_dataValid 0;
BA_ "Confidence" SG_ 989 CP_doorOpenLimiterMaxCount 1;
BA_ "Confidence" SG_ 989 CP_doorOpenLimiterMaxRequestType 1;
BA_ "Confidence" SG_ 989 CP_doorCloseLimiterMaxCount 1;
BA_ "Confidence" SG_ 989 CP_doorCloseLimiterMaxRequestTyp 1;
BA_ "SystemSignalLongSymbol" SG_ 989 CP_doorCloseLimiterMaxRequestTyp "CP_doorCloseLimiterMaxRequestType";
BA_ "Confidence" SG_ 605 CP_type 0;
BA_ "Confidence" SG_ 605 CP_insertEnableLine 0;
BA_ "Confidence" SG_ 605 CP_latchState 0;
BA_ "GenSigSNA" SG_ 605 CP_latchState "0";
BA_ "Confidence" SG_ 605 CP_permanentPowerRequest 0;
BA_ "Confidence" SG_ 605 CP_chargeDoorOpen 0;
BA_ "Confidence" SG_ 605 CP_doorControlState 0;
BA_ "Confidence" SG_ 605 CP_doorButtonPressed 0;
BA_ "Confidence" SG_ 605 CP_swcanRelayClosed 0;
BA_ "Confidence" SG_ 605 CP_inhibitOta 0;
BA_ "Confidence" SG_ 605 CP_chargeCableState 0;
BA_ "GenSigSNA" SG_ 605 CP_chargeCableState "0";
BA_ "Confidence" SG_ 605 CP_latchControlState 0;
BA_ "Confidence" SG_ 605 CP_ledColor 0;
BA_ "Confidence" SG_ 605 CP_UHF_handleFound 0;
BA_ "Confidence" SG_ 605 CP_faultLineSensed 0;
BA_ "Confidence" SG_ 605 CP_doorPresenceState 0;
BA_ "Confidence" SG_ 605 CP_inductiveSensorState 0;
BA_ "Confidence" SG_ 605 CP_chargeDoorOpenUI 0;
BA_ "Confidence" SG_ 605 CP_vehicleUnlockRequest 0;
BA_ "Confidence" SG_ 605 CP_coldWeatherMode 0;
BA_ "Confidence" SG_ 605 CP_inletHeaterUiState 1;
BA_ "Confidence" SG_ 893 CP_thermalStatusSelect 1;
BA_ "Confidence" SG_ 893 CP_pinTemperature1 0;
BA_ "Confidence" SG_ 893 CP_pinTemperature2 0;
BA_ "Confidence" SG_ 893 CP_pinTemperature3 0;
BA_ "Confidence" SG_ 1001 DAS_headlightRequest 0;
BA_ "Confidence" SG_ 1001 DAS_hazardLightRequest 0;
BA_ "GenSigSNA" SG_ 1001 DAS_hazardLightRequest "3";
BA_ "Confidence" SG_ 1001 DAS_wiperSpeed 0;
BA_ "Confidence" SG_ 1001 DAS_turnIndicatorRequest 0;
BA_ "Confidence" SG_ 1001 DAS_highLowBeamDecision 0;
BA_ "GenSigSNA" SG_ 1001 DAS_highLowBeamDecision "3";
BA_ "Confidence" SG_ 1001 DAS_heaterRequest 0;
BA_ "GenSigSNA" SG_ 1001 DAS_heaterRequest "0";
BA_ "Confidence" SG_ 1001 DAS_highLowBeamOffReason 0;
BA_ "GenSigSNA" SG_ 1001 DAS_highLowBeamOffReason "5";
BA_ "Confidence" SG_ 1001 DAS_forwardCamHeaterDutyCycle 0;
BA_ "Confidence" SG_ 1001 DAS_dynamicBrakeLightRequest 0;
BA_ "Confidence" SG_ 1001 DAS_radarHeaterRequest 0;
BA_ "Confidence" SG_ 1001 DAS_ahlbOverride 0;
BA_ "Confidence" SG_ 1001 DAS_mirrorFoldRequest 0;
BA_ "GenSigSNA" SG_ 1001 DAS_mirrorFoldRequest "3";
BA_ "Confidence" SG_ 1001 DAS_wiperWashRequest 0;
BA_ "Confidence" SG_ 1001 DAS_ulcConfirmationRequestActive 0;
BA_ "Confidence" SG_ 1001 DAS_overrideWiperSetting 0;
BA_ "Confidence" SG_ 1001 DAS_autoWiperState 0;
BA_ "GenSigSNA" SG_ 1001 DAS_autoWiperState "5";
BA_ "Confidence" SG_ 1001 DAS_turnIndicatorRequestReason 0;
BA_ "Confidence" SG_ 1001 DAS_forwardRadarPowerRequest 0;
BA_ "Confidence" SG_ 1001 DAS_driverDomeLightRequest 0;
BA_ "Confidence" SG_ 1001 DAS_drivePowerStateRequest 0;
BA_ "Confidence" SG_ 1001 DAS_enableIcrDataCollection 0;
BA_ "Confidence" SG_ 1001 DAS_rPillarCamHeaterDutyCycle 0;
BA_ "Confidence" SG_ 1001 DAS_adaptiveHighBeamIsFaulted 0;
BA_ "Confidence" SG_ 1001 DAS_restrictDoorReleaseLeft 0;
BA_ "Confidence" SG_ 1001 DAS_restrictDoorReleaseRight 0;
BA_ "Confidence" SG_ 1001 DAS_bodyControlsCounter 0;
BA_ "Confidence" SG_ 1001 DAS_bodyControlsChecksum 0;
BA_ "Confidence" SG_ 1318 DIF_alertID 1;
BA_ "Confidence" SG_ 1318 DIF_alertState 1;
BA_ "Confidence" SG_ 1318 DIF_a007_phaseAcurrent 1;
BA_ "Confidence" SG_ 1318 DIF_a007_phaseBcurrent 1;
BA_ "Confidence" SG_ 1318 DIF_a007_offsetError 1;
BA_ "Confidence" SG_ 1318 DIF_a007_idFdbStdDeviation 1;
BA_ "Confidence" SG_ 1318 DIF_a007_iqFdbStdDeviation 1;
BA_ "Confidence" SG_ 1318 DIF_a011_reason 1;
BA_ "Confidence" SG_ 1318 DIF_a012_hvilStatus 1;
BA_ "GenSigSNA" SG_ 1318 DIF_a012_hvilStatus "3";
BA_ "Confidence" SG_ 1318 DIF_a012_hvilCmVoltage 1;
BA_ "Confidence" SG_ 1318 DIF_a012_hvilCurrent 1;
BA_ "Confidence" SG_ 1318 DIF_a013_errorType 1;
BA_ "Confidence" SG_ 1318 DIF_a014_motorSpeed 1;
BA_ "Confidence" SG_ 1318 DIF_a014_adState 1;
BA_ "Confidence" SG_ 1318 DIF_a014_torqueCommandFwd 1;
BA_ "Confidence" SG_ 1318 DIF_a014_brakeMasterCylPress 1;
BA_ "Confidence" SG_ 1318 DIF_a014_rmsTorqueError 1;
BA_ "Confidence" SG_ 1318 DIF_a016_newSafeState 1;
BA_ "Confidence" SG_ 1318 DIF_a016_oldSafeState 1;
BA_ "Confidence" SG_ 1318 DIF_a016_motorRPM 1;
BA_ "Confidence" SG_ 1318 DIF_a016_torqueMotor 1;
BA_ "Confidence" SG_ 1318 DIF_a016_triggerEvent 1;
BA_ "Confidence" SG_ 1318 DIF_a024_vBat 1;
BA_ "Confidence" SG_ 1318 DIF_a024_failReason 1;
BA_ "Confidence" SG_ 1318 DIF_a024_state 1;
BA_ "Confidence" SG_ 1318 DIF_a024_Ia 1;
BA_ "Confidence" SG_ 1318 DIF_a024_Ib 1;
BA_ "Confidence" SG_ 1318 DIF_a024_maxCurrMagSqrd 1;
BA_ "Confidence" SG_ 1318 DIF_a024_rotorAngle 1;
BA_ "Confidence" SG_ 1318 DIF_a025_Ia 1;
BA_ "Confidence" SG_ 1318 DIF_a025_torqueMotor 1;
BA_ "Confidence" SG_ 1318 DIF_a025_motorSpeed 1;
BA_ "Confidence" SG_ 1318 DIF_a026_Ib 1;
BA_ "Confidence" SG_ 1318 DIF_a026_torqueMotor 1;
BA_ "Confidence" SG_ 1318 DIF_a026_motorSpeed 1;
BA_ "Confidence" SG_ 1318 DIF_a027_Ic 1;
BA_ "Confidence" SG_ 1318 DIF_a027_torqueMotor 1;
BA_ "Confidence" SG_ 1318 DIF_a027_motorSpeed 1;
BA_ "Confidence" SG_ 1318 DIF_a028_phaseAirms 1;
BA_ "Confidence" SG_ 1318 DIF_a028_iArmsTorque 1;
BA_ "Confidence" SG_ 1318 DIF_a028_iArmsSpeed 1;
BA_ "Confidence" SG_ 1318 DIF_a029_phaseBirms 1;
BA_ "Confidence" SG_ 1318 DIF_a029_iBrmsTorque 1;
BA_ "Confidence" SG_ 1318 DIF_a029_iBrmsSpeed 1;
BA_ "Confidence" SG_ 1318 DIF_a030_phaseCirms 1;
BA_ "Confidence" SG_ 1318 DIF_a030_iCrmsTorque 1;
BA_ "Confidence" SG_ 1318 DIF_a030_iCrmsSpeed 1;
BA_ "Confidence" SG_ 1318 DIF_a031_phaseAoffset 1;
BA_ "Confidence" SG_ 1318 DIF_a032_phaseBoffset 1;
BA_ "Confidence" SG_ 1318 DIF_a033_phaseAcurrent 1;
BA_ "Confidence" SG_ 1318 DIF_a033_deltaIa 1;
BA_ "Confidence" SG_ 1318 DIF_a033_vRefIa 1;
BA_ "Confidence" SG_ 1318 DIF_a034_phaseBcurrent 1;
BA_ "Confidence" SG_ 1318 DIF_a034_deltaIb 1;
BA_ "Confidence" SG_ 1318 DIF_a034_vRefIb 1;
BA_ "Confidence" SG_ 1318 DIF_a035_phaseDifference 1;
BA_ "Confidence" SG_ 1318 DIF_a035_phaseCurrent 1;
BA_ "Confidence" SG_ 1318 DIF_a035_frequency 1;
BA_ "Confidence" SG_ 1318 DIF_a036_busVoltage 1;
BA_ "Confidence" SG_ 1318 DIF_a036_busHighLimit 1;
BA_ "Confidence" SG_ 1318 DIF_a037_busVoltage 1;
BA_ "Confidence" SG_ 1318 DIF_a037_busLowLimit 1;
BA_ "Confidence" SG_ 1318 DIF_a038_vBMS 1;
BA_ "Confidence" SG_ 1318 DIF_a038_vBat 1;
BA_ "Confidence" SG_ 1318 DIF_a038_iBat 1;
BA_ "Confidence" SG_ 1318 DIF_a038_reason 1;
BA_ "Confidence" SG_ 1318 DIF_a043_outletTemp 1;
BA_ "Confidence" SG_ 1318 DIF_a044_outletTemp 1;
BA_ "Confidence" SG_ 1318 DIF_a045_inletTemp 1;
BA_ "Confidence" SG_ 1318 DIF_a045_outletTemp 1;
BA_ "Confidence" SG_ 1318 DIF_a045_heatsinkTemp 1;
BA_ "Confidence" SG_ 1318 DIF_a045_outletTempSlope 1;
BA_ "Confidence" SG_ 1318 DIF_a046_statorTemp1 1;
BA_ "Confidence" SG_ 1318 DIF_a046_statorTemp2 1;
BA_ "Confidence" SG_ 1318 DIF_a047_statorTemp1 1;
BA_ "Confidence" SG_ 1318 DIF_a047_statorTslope1 1;
BA_ "Confidence" SG_ 1318 DIF_a050_statorTemp1 1;
BA_ "Confidence" SG_ 1318 DIF_a050_statorTemp2 1;
BA_ "Confidence" SG_ 1318 DIF_a054_outletTemp 1;
BA_ "Confidence" SG_ 1318 DIF_a054_heatsinkTemp 1;
BA_ "Confidence" SG_ 1318 DIF_a055_parameterDI 1;
BA_ "Confidence" SG_ 1318 DIF_a055_parameterPM 1;
BA_ "Confidence" SG_ 1318 DIF_a055_torqueType 1;
BA_ "Confidence" SG_ 1318 DIF_a055_motorRPM 1;
BA_ "Confidence" SG_ 1318 DIF_a056_pcbTemp 1;
BA_ "Confidence" SG_ 1318 DIF_a057_pcbTemp 1;
BA_ "Confidence" SG_ 1318 DIF_a058_pcbTemp 1;
BA_ "Confidence" SG_ 1318 DIF_a058_outletTemp 1;
BA_ "Confidence" SG_ 1318 DIF_a058_heatsinkTemp 1;
BA_ "Confidence" SG_ 1318 DIF_a058_pcbTempSlope 1;
BA_ "Confidence" SG_ 1318 DIF_a059_heatsinkTemp 1;
BA_ "Confidence" SG_ 1318 DIF_a060_heatsinkTemp 1;
BA_ "Confidence" SG_ 1318 DIF_a061_sensor 1;
BA_ "Confidence" SG_ 1318 DIF_a061_reason 1;
BA_ "Confidence" SG_ 1318 DIF_a061_phTemp 1;
BA_ "Confidence" SG_ 1318 DIF_a061_otherTemp 1;
BA_ "Confidence" SG_ 1318 DIF_a062_limpReason 1;
BA_ "Confidence" SG_ 1318 DIF_a064_interventionType 1;
BA_ "Confidence" SG_ 1318 DIF_a064_torqueCmdState 1;
BA_ "GenSigSNA" SG_ 1318 DIF_a064_torqueCmdState "0";
BA_ "Confidence" SG_ 1318 DIF_a066_canID 1;
BA_ "Confidence" SG_ 1318 DIF_a066_errorType 1;
BA_ "Confidence" SG_ 1318 DIF_a069_motorSpeed 1;
BA_ "Confidence" SG_ 1318 DIF_a069_rotorCoolingPower 1;
BA_ "Confidence" SG_ 1318 DIF_a069_rotorMagnetTemp 1;
BA_ "Confidence" SG_ 1318 DIF_a069_fittedTorqueLimit 1;
BA_ "Confidence" SG_ 1318 DIF_a072_reason 1;
BA_ "Confidence" SG_ 1318 DIF_a073_motorSpeedrpm 1;
BA_ "Confidence" SG_ 1318 DIF_a075_motorSpeed 1;
BA_ "Confidence" SG_ 1318 DIF_a075_absSpeed 1;
BA_ "Confidence" SG_ 1318 DIF_a076_lvSupplyV 1;
BA_ "Confidence" SG_ 1318 DIF_a077_lvSupplyV 1;
BA_ "Confidence" SG_ 1318 DIF_a090_reason 1;
BA_ "Confidence" SG_ 1318 DIF_a094_canID 1;
BA_ "Confidence" SG_ 1318 DIF_a094_errorType 1;
BA_ "Confidence" SG_ 1318 DIF_a097_errorType 1;
BA_ "Confidence" SG_ 1318 DIF_a098_fluxState 1;
BA_ "Confidence" SG_ 1318 DIF_a103_fluidTorDeltaT 1;
BA_ "Confidence" SG_ 1318 DIF_a103_inverterTemp 1;
BA_ "Confidence" SG_ 1318 DIF_a103_rmsCurrent 1;
BA_ "Confidence" SG_ 1318 DIF_a103_ambientTemp 1;
BA_ "Confidence" SG_ 1318 DIF_a103_sensorTempEst 1;
BA_ "Confidence" SG_ 1318 DIF_a108_blockingAlert 1;
BA_ "Confidence" SG_ 1318 DIF_a112_phaseAcurrent 1;
BA_ "Confidence" SG_ 1318 DIF_a112_phaseBcurrent 1;
BA_ "Confidence" SG_ 1318 DIF_a113_heatsink1Temp 1;
BA_ "Confidence" SG_ 1318 DIF_a113_heatsink2Temp 1;
BA_ "Confidence" SG_ 1318 DIF_a113_heatsink3Temp 1;
BA_ "Confidence" SG_ 1318 DIF_a121_badRegReason 1;
BA_ "Confidence" SG_ 1318 DIF_a121_torqueDelta 1;
BA_ "Confidence" SG_ 1318 DIF_a121_badCurrent 1;
BA_ "Confidence" SG_ 1318 DIF_a121_badFlux 1;
BA_ "Confidence" SG_ 1318 DIF_a123_lossReason 1;
BA_ "Confidence" SG_ 1318 DIF_a123_busVoltage 1;
BA_ "Confidence" SG_ 1318 DIF_a123_badFlux 1;
BA_ "Confidence" SG_ 1318 DIF_a123_lossRequest 1;
BA_ "Confidence" SG_ 1318 DIF_a123_badCurrent 1;
BA_ "Confidence" SG_ 1318 DIF_a123_motorRPM 1;
BA_ "Confidence" SG_ 1318 DIF_a123_varianceD 1;
BA_ "Confidence" SG_ 1318 DIF_a123_varianceQ 1;
BA_ "Confidence" SG_ 1318 DIF_a126_limpReason 1;
BA_ "Confidence" SG_ 1318 DIF_a127_gpoReason 1;
BA_ "Confidence" SG_ 1318 DIF_a127_temp 1;
BA_ "Confidence" SG_ 1318 DIF_a133_capacitorTemp 1;
BA_ "Confidence" SG_ 1318 DIF_a133_badValue1 1;
BA_ "Confidence" SG_ 1318 DIF_a133_badValue2 1;
BA_ "Confidence" SG_ 1318 DIF_a134_wheelSpeedDiffFrL 1;
BA_ "Confidence" SG_ 1318 DIF_a134_wheelSpeedDiffFrR 1;
BA_ "Confidence" SG_ 1318 DIF_a134_wheelSpeedDiffReL 1;
BA_ "Confidence" SG_ 1318 DIF_a134_wheelSpeedDiffReR 1;
BA_ "SystemSignalLongSymbol" SG_ 1318 DIF_a144_packPerformanceDeviatio "DIF_a144_packPerformanceDeviation";
BA_ "Confidence" SG_ 1318 DIF_a147_accumulatedWear 1;
BA_ "Confidence" SG_ 1318 DIF_a149_flow 1;
BA_ "GenSigSNA" SG_ 1318 DIF_a149_flow "255";
BA_ "Confidence" SG_ 1318 DIF_a149_voltage 1;
BA_ "Confidence" SG_ 1318 DIF_a149_temperature 1;
BA_ "Confidence" SG_ 1318 DIF_a149_state 1;
BA_ "GenSigSNA" SG_ 1318 DIF_a149_state "7";
BA_ "Confidence" SG_ 1318 DIF_a149_pcbaID 1;
BA_ "Confidence" SG_ 1318 DIF_a150_vBatRawMinusFiltered 1;
BA_ "Confidence" SG_ 1318 DIF_a150_vBatFilteredRate 1;
BA_ "Confidence" SG_ 1318 DIF_a150_elapsedMs 1;
BA_ "Confidence" SG_ 1318 DIF_a150_energy 1;
BA_ "Confidence" SG_ 1318 DIF_a152_errorType 1;
BA_ "Confidence" SG_ 1318 DIF_a153_oilFlow 1;
BA_ "GenSigSNA" SG_ 1318 DIF_a153_oilFlow "255";
BA_ "Confidence" SG_ 1318 DIF_a153_oilTemperature 1;
BA_ "GenSigSNA" SG_ 1318 DIF_a153_oilTemperature "255";
BA_ "Confidence" SG_ 1318 DIF_a153_phaseCurrent 1;
BA_ "GenSigSNA" SG_ 1318 DIF_a153_phaseCurrent "255";
BA_ "Confidence" SG_ 1318 DIF_a153_dcVoltage 1;
BA_ "GenSigSNA" SG_ 1318 DIF_a153_dcVoltage "255";
BA_ "Confidence" SG_ 1318 DIF_a153_lowPressPlausibility 1;
BA_ "Confidence" SG_ 1318 DIF_a153_state 1;
BA_ "GenSigSNA" SG_ 1318 DIF_a153_state "7";
BA_ "Confidence" SG_ 1318 DIF_a153_oilPumpAlert 1;
BA_ "Confidence" SG_ 1318 DIF_a153_reason 1;
BA_ "Confidence" SG_ 1318 DIF_a154_motorRPM 1;
BA_ "Confidence" SG_ 1318 DIF_a154_phaseError 1;
BA_ "Confidence" SG_ 1318 DIF_a154_commonGain 1;
BA_ "Confidence" SG_ 1318 DIF_a160_vBatRawMinusFiltered 1;
BA_ "Confidence" SG_ 1318 DIF_a160_vBatFilteredRate 1;
BA_ "Confidence" SG_ 1318 DIF_a160_elapsedMs 1;
BA_ "Confidence" SG_ 1318 DIF_a160_energy 1;
BA_ "Confidence" SG_ 1318 DIF_a202_reason 1;
BA_ "Confidence" SG_ 1318 DIF_a202_movement 1;
BA_ "Confidence" SG_ 1318 DIF_a202_sysStateExitCondition 1;
BA_ "Confidence" SG_ 1318 DIF_a244_irSensorV 1;
BA_ "SystemSignalLongSymbol" SG_ 1318 DIF_a244_plausibleSingleSwitchSh "DIF_a244_plausibleSingleSwitchShortOnly";
BA_ "Confidence" SG_ 1318 DIF_a246_codeBranch 1;
BA_ "Confidence" SG_ 1318 DIF_a246_motorRPM 1;
BA_ "Confidence" SG_ 1318 DIF_a246_eepromOffsetIa 1;
BA_ "Confidence" SG_ 1318 DIF_a246_eepromOffsetIb 1;
BA_ "Confidence" SG_ 1318 DIF_a247_rotorOffsetEst 1;
BA_ "Confidence" SG_ 1318 DIF_a247_motorRPM 1;
BA_ "Confidence" SG_ 1318 DIF_a247_torqueMotor 1;
BA_ "Confidence" SG_ 1318 DIF_a251_oilFlow 1;
BA_ "GenSigSNA" SG_ 1318 DIF_a251_oilFlow "255";
BA_ "Confidence" SG_ 1318 DIF_a251_oilTemperature 1;
BA_ "GenSigSNA" SG_ 1318 DIF_a251_oilTemperature "255";
BA_ "Confidence" SG_ 1318 DIF_a251_dcVoltage 1;
BA_ "GenSigSNA" SG_ 1318 DIF_a251_dcVoltage "255";
BA_ "Confidence" SG_ 1318 DIF_a251_dcCurrent 1;
BA_ "GenSigSNA" SG_ 1318 DIF_a251_dcCurrent "255";
BA_ "Confidence" SG_ 1318 DIF_a251_phaseCurrent 1;
BA_ "GenSigSNA" SG_ 1318 DIF_a251_phaseCurrent "255";
BA_ "Confidence" SG_ 1318 DIF_a251_leadAngle 1;
BA_ "Confidence" SG_ 1318 DIF_a251_reason 1;
BA_ "Confidence" SG_ 634 DIF_hvStatusChecksum 0;
BA_ "Confidence" SG_ 634 DIF_hvStatusCounter 0;
BA_ "Confidence" SG_ 634 DIF_hvilCurrent 0;
BA_ "Confidence" SG_ 634 DIF_hvilCmVoltage 0;
BA_ "Confidence" SG_ 634 DIF_hvilStatus 0;
BA_ "GenSigSNA" SG_ 634 DIF_hvilStatus "3";
BA_ "Confidence" SG_ 634 DIF_hvilSupplyState 0;
BA_ "Confidence" SG_ 634 DIF_activeDischargeCtrl 0;
BA_ "Confidence" SG_ 634 DIF_activeDischargeStatus 0;
BA_ "Confidence" SG_ 634 DIF_vBat 0;
BA_ "Confidence" SG_ 634 DIF_vBatQF 0;
BA_ "Confidence" SG_ 634 DIF_powerStageSafeState 0;
BA_ "Confidence" SG_ 634 DIF_fluxState 0;
BA_ "Confidence" SG_ 634 DIF_vBusDiag 0;
BA_ "Confidence" SG_ 634 DIF_gateDriveState 0;
BA_ "Confidence" SG_ 741 DIF_elecPower 0;
BA_ "GenSigSNA" SG_ 741 DIF_elecPower "1024";
BA_ "Confidence" SG_ 741 DIF_heatPowerOptimal 0;
BA_ "Confidence" SG_ 741 DIF_heatPowerMax 0;
BA_ "Confidence" SG_ 741 DIF_heatPowerActual 0;
BA_ "Confidence" SG_ 741 DIF_excessHeatCommand 0;
BA_ "Confidence" SG_ 741 DIF_drivePowerMax 0;
BA_ "GenSigSNA" SG_ 741 DIF_drivePowerMax "511";
VAL_ 798 CP_matrixIndex 3 "AlertMatrix3" 2 "AlertMatrix2" 1 "AlertMatrix1" 0 "AlertMatrix0" ;
VAL_ 541 CP_proximity 3 "CHG_PROXIMITY_LATCHED" 2 "CHG_PROXIMITY_UNLATCHED" 1 "CHG_PROXIMITY_DISCONNECTED" 0 "CHG_PROXIMITY_SNA" ;
VAL_ 541 CP_pilot 7 "CHG_PILOT_SNA" 6 "CHG_PILOT_UNUSED_6" 5 "CHG_PILOT_INVALID" 4 "CHG_PILOT_IDLE" 3 "CHG_PILOT_FAST_CHARGE" 2 "CHG_PILOT_LINE_CHARGE" 1 "CHG_PILOT_FAULTED" 0 "CHG_PILOT_NONE" ;
VAL_ 541 CP_cableType 5 "CHG_CABLE_TYPE_SNA" 4 "CHG_CABLE_TYPE_MCS" 3 "CHG_CABLE_TYPE_GB_DC" 2 "CHG_CABLE_TYPE_GB_AC" 1 "CHG_CABLE_TYPE_SAE" 0 "CHG_CABLE_TYPE_IEC" ;
VAL_ 541 CP_iecPilotState 9 "IEC_PILOT_SNA" 8 "IEC_PILOT_NUM" 7 "IEC_PILOT_F" 6 "IEC_PILOT_E" 5 "IEC_PILOT_C3" 4 "IEC_PILOT_C2" 3 "IEC_PILOT_C1" 2 "IEC_PILOT_B3" 1 "IEC_PILOT_B2" 0 "IEC_PILOT_B1" ;
VAL_ 541 CP_teslaSwcanState 8 "TESLA_SWCAN_V2L_ESTABLISHED" 7 "TESLA_SWCAN_V2L_RECEIVE" 6 "TESLA_SWCAN_OFFBOARD_UPDATE_IN_PROGRESS" 5 "TESLA_SWCAN_GO_TO_SLEEP" 4 "TESLA_SWCAN_FAULT" 3 "TESLA_SWCAN_ESTABLISHED" 2 "TESLA_SWCAN_RECEIVE" 1 "TESLA_SWCAN_ACCEPT" 0 "TESLA_SWCAN_INACTIVE" ;
VAL_ 541 CP_evseChargeType_UI 2 "AC_CHARGER_PRESENT" 1 "DC_CHARGER_PRESENT" 0 "NO_CHARGER_PRESENT" ;
VAL_ 541 CP_gbState 15 "GBDC_TESTER_PRESENT" 14 "GBDC_FAULTED" 13 "GBDC_RETRY_CHARGE" 12 "GBDC_ERROR_HANDLING" 11 "GBDC_END_OF_CHARGE" 10 "GBDC_CHARGE_DISABLING" 9 "GBDC_STOP_CHARGE_REQUESTED" 8 "GBDC_CHARGING" 7 "GBDC_READY_TO_CHARGE" 6 "GBDC_VEH_PACK_PRECHARGE" 5 "GBDC_CHARGE_PARAM_CONFIG" 4 "GBDC_RECOGNITION" 3 "GBDC_HANDSHAKING_EXT_ISO" 2 "GBDC_COMMS_RECEIVED" 1 "GBDC_WAIT_FOR_COMMS" 0 "GBDC_INACTIVE" ;
VAL_ 541 CP_gbdcStopChargeReason 8 "GBDC_PARAM_MISMATCH" 7 "GBDC_SUPERCHARGER_COMMS_TIMEOUT" 6 "GBDC_LIVE_DISCONNECT" 5 "GBDC_EVSE_CRITICAL_FAULT" 4 "GBDC_EVSE_FAULT" 3 "GBDC_COMMS_TIMEOUT" 2 "GBDC_EVSE_REQUESTED" 1 "GBDC_VEH_REQUESTED" 0 "GBDC_STOP_REASON_NONE" ;
VAL_ 541 CP_gbdcFailureReason 3 "GBDC_CRITICAL_FAILURE" 2 "GBDC_SHUTDOWN_FAILURE" 1 "GBDC_ATTEMPTS_EXPIRED" 0 "GBDC_FAILURE_NONE" ;
VAL_ 541 CP_acChargeState 6 "AC_CHARGE_FAULT" 5 "AC_CHARGE_VEH_SHUTDOWN" 4 "AC_CHARGE_ONBOARD_CHARGER_SHUTDOWN" 3 "AC_CHARGE_ENABLED" 2 "AC_CHARGE_STANDBY" 1 "AC_CHARGE_CONNECTED_CHARGE_BLOCKED" 0 "AC_CHARGE_INACTIVE" ;
VAL_ 541 CP_teslaDcState 10 "TESLA_DC_FAULT" 9 "TESLA_DC_EMERGENCY_SHUTDOWN" 8 "TESLA_DC_VEH_SHUTDOWN" 7 "TESLA_DC_EVSE_SHUTDOWN" 6 "TESLA_DC_ENABLED" 5 "TESLA_DC_EXT_PRECHARGE_ACTIVE" 4 "TESLA_DC_EXT_TEST_ACTIVE" 3 "TESLA_DC_EXT_TESTS_ENABLED" 2 "TESLA_DC_STANDBY" 1 "TESLA_DC_CONNECTED_CHARGE_BLOCKED" 0 "TESLA_DC_INACTIVE" ;
VAL_ 1342 CP_infoIndex 255 "END" 31 "SUBCOMPONENT_GITHASH" 30 "PACKAGE_SN_8_14" 29 "PACKAGE_SN_1_7" 27 "PACKAGE_PN_15_20" 26 "PACKAGE_PN_8_14" 25 "PACKAGE_PN_1_7" 23 "SUBCOMPONENT2" 22 "VARIANTCRC" 20 "UDS_PROTOCOL_BOOTCRC" 19 "VERSION_DEPRECATED" 18 "BOOTLOADER_GITHASH" 17 "APP_GITHASH" 16 "SUBCOMPONENT" 15 "BOOTLOADER_CRC" 14 "BOOTLOADER_SVN" 13 "APP_CRC" 11 "PCBAID_ASSYID_USAGEID" 10 "BUILD_HWID_COMPONENTID" 9 "DEPRECATED_9" 8 "DEPRECATED_8" 7 "DEPRECATED_7" 6 "DEPRECATED_6" 5 "DEPRECATED_5" 4 "DEPRECATED_4" 3 "DEPRECATED_3" 2 "DEPRECATED_2" 1 "DEPRECATED_1" 0 "DEPRECATED_0" ;
VAL_ 1342 CP_buildType 4 "INFO_MFG_BUILD" 3 "INFO_TRACEABLE_CI_BUILD" 2 "INFO_LOCAL_BUILD" 1 "INFO_PLATFORM_BUILD" 0 "INFO_UNKNOWN_BUILD" ;
VAL_ 1885 CP_loggingFastSelect 5 "5" 4 "4" 3 "3" 2 "2" 1 "1" 0 "0" ;
VAL_ 1885 CP_chargeCablePresent 1 "CABLE_PRESENT" 0 "CABLE_NOT_PRESENT" ;
VAL_ 1885 CP_UHF_controlState 10 "CP_UHF_FAULT" 9 "CP_UHF_SLEEP" 8 "CP_UHF_HANDLE_FOUND" 7 "CP_UHF_READ_RXFIFO" 6 "CP_UHF_CHECK_RX" 5 "CP_UHF_RX" 4 "CP_UHF_PREPARE_RX" 3 "CP_UHF_CALIBRATE" 2 "CP_UHF_IDLE" 1 "CP_UHF_CONFIG" 0 "CP_UHF_INIT" ;
VAL_ 1885 CP_doorOpenRequest 8 "CPD_OPEN_REQ_NUM" 7 "CPD_OPEN_REQ_CABLE_RECONNECTED" 6 "CPD_OPEN_REQ_VCFRONT" 5 "CPD_OPEN_REQ_CLOSING_FAILED" 4 "CPD_OPEN_REQ_PUSH_TO_OPEN" 3 "CPD_OPEN_REQ_UHF" 2 "CPD_OPEN_REQ_SEC" 1 "CPD_OPEN_REQ_UI" 0 "CPD_OPEN_REQ_NONE" ;
VAL_ 1885 CP_doorOpenEndOfDriveReason 7 "CP_STOP_DRIVE_REASON_OVERCURRENT" 6 "CP_STOP_DRIVE_REASON_REQ_OVERRIDE" 5 "CP_STOP_DRIVE_REASON_ABSOLUTE_TIMEOUT" 4 "CP_STOP_DRIVE_REASON_MAX_TARGET_V" 3 "CP_STOP_DRIVE_REASON_REACHED_STOP" 2 "CP_STOP_DRIVE_REASON_STOPPED_MOVING_TIMEOUT" 1 "CP_STOP_DRIVE_REASON_STALLED" 0 "CP_STOP_DRIVE_REASON_NONE" ;
VAL_ 1885 CP_doorCloseEndOfDriveReason 7 "CP_STOP_DRIVE_REASON_OVERCURRENT" 6 "CP_STOP_DRIVE_REASON_REQ_OVERRIDE" 5 "CP_STOP_DRIVE_REASON_ABSOLUTE_TIMEOUT" 4 "CP_STOP_DRIVE_REASON_MAX_TARGET_V" 3 "CP_STOP_DRIVE_REASON_REACHED_STOP" 2 "CP_STOP_DRIVE_REASON_STOPPED_MOVING_TIMEOUT" 1 "CP_STOP_DRIVE_REASON_STALLED" 0 "CP_STOP_DRIVE_REASON_NONE" ;
VAL_ 1885 CP_doorCloseRequest 16 "CPD_CLOSE_REQ_NUM" 15 "CPD_CLOSE_REQ_COVER_OPEN" 14 "CPD_CLOSE_REQ_VCFRONT" 13 "CPD_CLOSE_REQ_OPEN_ON_WAKE" 12 "CPD_CLOSE_REQ_SENSOR_COMMS_RECOVERED" 11 "CPD_CLOSE_REQ_SENSOR_MISMATCH" 10 "CPD_CLOSE_REQ_INITIAL_CINCH" 9 "CPD_CLOSE_REQ_OPENED_IN_DRIVE_STATE" 8 "CPD_CLOSE_REQ_ENTER_DRIVE" 7 "CPD_CLOSE_REQ_FAULT_LINE" 6 "CPD_CLOSE_REQ_CAR_WASH" 5 "CPD_CLOSE_REQ_PUSH_TO_CLOSE" 4 "CPD_CLOSE_REQ_SEC" 3 "CPD_CLOSE_REQ_UI" 2 "CPD_CLOSE_REQ_DOOR_OPEN_TIMEOUT" 1 "CPD_CLOSE_REQ_CABLE_UNPLUGGED" 0 "CPD_CLOSE_REQ_NONE" ;
VAL_ 1885 CP_latchDisengagingStopReason 7 "CP_STOP_DRIVE_REASON_OVERCURRENT" 6 "CP_STOP_DRIVE_REASON_REQ_OVERRIDE" 5 "CP_STOP_DRIVE_REASON_ABSOLUTE_TIMEOUT" 4 "CP_STOP_DRIVE_REASON_MAX_TARGET_V" 3 "CP_STOP_DRIVE_REASON_REACHED_STOP" 2 "CP_STOP_DRIVE_REASON_STOPPED_MOVING_TIMEOUT" 1 "CP_STOP_DRIVE_REASON_STALLED" 0 "CP_STOP_DRIVE_REASON_NONE" ;
VAL_ 1885 CP_latchEngagingStopReason 7 "CP_STOP_DRIVE_REASON_OVERCURRENT" 6 "CP_STOP_DRIVE_REASON_REQ_OVERRIDE" 5 "CP_STOP_DRIVE_REASON_ABSOLUTE_TIMEOUT" 4 "CP_STOP_DRIVE_REASON_MAX_TARGET_V" 3 "CP_STOP_DRIVE_REASON_REACHED_STOP" 2 "CP_STOP_DRIVE_REASON_STOPPED_MOVING_TIMEOUT" 1 "CP_STOP_DRIVE_REASON_STALLED" 0 "CP_STOP_DRIVE_REASON_NONE" ;
VAL_ 1885 CP_doorIdDetectionState 2 "DOOR_ID_VALID" 1 "DOOR_ID_INVALID" 0 "DOOR_ID_UNKNOWN_SNA" ;
VAL_ 1885 CP_doorIdDetectedBin 3 "DOOR_ID_BIN_OPAL" 2 "DOOR_ID_BIN_HMC" 1 "DOOR_ID_BIN_NMB" 0 "DOOR_ID_BIN_UNKNOWN" ;
VAL_ 989 CP_loggingSlowSelect 7 "7" 6 "6" 5 "5" 4 "4" 3 "3" 2 "2" 1 "1" 0 "0" ;
VAL_ 989 CP_inlet1HarnessIdState 2 "HARNESS_PEDIGREE_VALID" 1 "HARNESS_PEDIGREE_INVALID" 0 "HARNESS_PEDIGREE_UNKNOWN_SNA" ;
VAL_ 989 CP_inlet2HarnessIdState 2 "HARNESS_PEDIGREE_VALID" 1 "HARNESS_PEDIGREE_INVALID" 0 "HARNESS_PEDIGREE_UNKNOWN_SNA" ;
VAL_ 989 CP_inletHeaterState 3 "INLET_HEATER_FAULTED" 2 "INLET_HEATER_ENABLED_LOWTEMP" 1 "INLET_HEATER_ENABLED_HIGHTEMP" 0 "INLET_HEATER_DISABLED" ;
VAL_ 989 CP_doorOpenLimiterMaxRequestType 8 "CPD_OPEN_REQ_NUM" 7 "CPD_OPEN_REQ_CABLE_RECONNECTED" 6 "CPD_OPEN_REQ_VCFRONT" 5 "CPD_OPEN_REQ_CLOSING_FAILED" 4 "CPD_OPEN_REQ_PUSH_TO_OPEN" 3 "CPD_OPEN_REQ_UHF" 2 "CPD_OPEN_REQ_SEC" 1 "CPD_OPEN_REQ_UI" 0 "CPD_OPEN_REQ_NONE" ;
VAL_ 989 CP_doorCloseLimiterMaxRequestTyp 16 "CPD_CLOSE_REQ_NUM" 15 "CPD_CLOSE_REQ_COVER_OPEN" 14 "CPD_CLOSE_REQ_VCFRONT" 13 "CPD_CLOSE_REQ_OPEN_ON_WAKE" 12 "CPD_CLOSE_REQ_SENSOR_COMMS_RECOVERED" 11 "CPD_CLOSE_REQ_SENSOR_MISMATCH" 10 "CPD_CLOSE_REQ_INITIAL_CINCH" 9 "CPD_CLOSE_REQ_OPENED_IN_DRIVE_STATE" 8 "CPD_CLOSE_REQ_ENTER_DRIVE" 7 "CPD_CLOSE_REQ_FAULT_LINE" 6 "CPD_CLOSE_REQ_CAR_WASH" 5 "CPD_CLOSE_REQ_PUSH_TO_CLOSE" 4 "CPD_CLOSE_REQ_SEC" 3 "CPD_CLOSE_REQ_UI" 2 "CPD_CLOSE_REQ_DOOR_OPEN_TIMEOUT" 1 "CPD_CLOSE_REQ_CABLE_UNPLUGGED" 0 "CPD_CLOSE_REQ_NONE" ;
VAL_ 605 CP_type 3 "CP_TYPE_IEC_CCS" 2 "CP_TYPE_GB" 1 "CP_TYPE_EURO_IEC" 0 "CP_TYPE_US_TESLA" ;
VAL_ 605 CP_latchState 3 "CP_LATCH_BLOCKING" 2 "CP_LATCH_ENGAGED" 1 "CP_LATCH_DISENGAGED" 0 "CP_LATCH_SNA" ;
VAL_ 605 CP_doorControlState 6 "CP_doorSenseClosed" 5 "CP_doorClosing" 4 "CP_doorSenseOpen" 3 "CP_doorOpening" 2 "CP_doorOpenRequested" 1 "CP_doorIdle" 0 "CP_doorInit" ;
VAL_ 605 CP_chargeCableState 2 "CHARGE_CABLE_CONNECTED" 1 "CHARGE_CABLE_NOT_CONNECTED" 0 "CHARGE_CABLE_UNKNOWN_SNA" ;
VAL_ 605 CP_latchControlState 5 "CP_latchEngaging" 4 "CP_latchDisengaged" 3 "CP_latchDisengaging" 2 "CP_latchDisengageRequested" 1 "CP_latchIdle" 0 "CP_latchInit" ;
VAL_ 605 CP_ledColor 13 "CP_LEDS_FLASHING_WHITE" 12 "CP_LEDS_FADING_OUT" 11 "CP_LEDS_FLASHING_PURPLE" 10 "CP_LEDS_FLASHING_BLUE" 9 "CP_LEDS_DEBUG" 8 "CP_LEDS_RAVE" 7 "CP_LEDS_AMBER" 6 "CP_LEDS_FLASHING_AMBER" 5 "CP_LEDS_FLASHING_GREEN" 4 "CP_LEDS_WHITE" 3 "CP_LEDS_BLUE" 2 "CP_LEDS_GREEN" 1 "CP_LEDS_RED" 0 "CP_LEDS_OFF" ;
VAL_ 605 CP_faultLineSensed 1 "FAULT_LINE_SET" 0 "FAULT_LINE_CLEARED" ;
VAL_ 605 CP_doorPresenceState 7 "CP_DOOR_PRESENCE_STATE_FAULT" 6 "CP_DOOR_PRESENCE_STATE_OFF_CHARGE" 5 "CP_DOOR_PRESENCE_STATE_OFF_DRIVE" 4 "CP_DOOR_PRESENCE_STATE_NOT_PRESENT" 3 "CP_DOOR_PRESENCE_STATE_PRESENT" 2 "CP_DOOR_PRESENCE_STATE_INIT_FROM_DRIVE" 1 "CP_DOOR_PRESENCE_STATE_INIT_FROM_CHARGE" 0 "CP_DOOR_PRESENCE_STATE_INIT" ;
VAL_ 605 CP_inductiveSensorState 7 "CP_INDUCTIVE_SENSOR_CONFIG" 6 "CP_INDUCTIVE_SENSOR_RESET" 5 "CP_INDUCTIVE_SENSOR_FAULT" 4 "CP_INDUCTIVE_SENSOR_WAIT_FOR_INIT" 3 "CP_INDUCTIVE_SENSOR_PAUSE" 2 "CP_INDUCTIVE_SENSOR_SHUTDOWN" 1 "CP_INDUCTIVE_SENSOR_POLL" 0 "CP_INDUCTIVE_SENSOR_INIT" ;
VAL_ 605 CP_coldWeatherMode 1 "CP_COLD_WEATHER_LATCH_MITIGATION" 0 "CP_COLD_WEATHER_NONE" ;
VAL_ 605 CP_inletHeaterUiState 4 "CP_HEATER_FAULTED" 3 "CP_HEATER_ENABLED" 2 "CP_HEATER_AVAILABLE" 1 "CP_HEATER_NOT_AVAILABLE" 0 "CP_HEATER_NOT_SUPPORTED" ;
VAL_ 893 CP_thermalStatusSelect 1 "1" 0 "0" ;
VAL_ 1001 DAS_headlightRequest 3 "DAS_HEADLIGHT_REQUEST_INVALID" 2 "DAS_HEADLIGHT_REQUEST_TAIL_LIGHTS_ONLY" 1 "DAS_HEADLIGHT_REQUEST_ON" 0 "DAS_HEADLIGHT_REQUEST_OFF" ;
VAL_ 1001 DAS_hazardLightRequest 3 "DAS_REQUEST_HAZARDS_SNA" 2 "DAS_REQUEST_HAZARDS_ON_FAST" 1 "DAS_REQUEST_HAZARDS_ON" 0 "DAS_REQUEST_HAZARDS_OFF" ;
VAL_ 1001 DAS_wiperSpeed 15 "DAS_WIPER_SPEED_INVALID" 14 "DAS_WIPER_SPEED_14" 13 "DAS_WIPER_SPEED_13" 12 "DAS_WIPER_SPEED_12" 11 "DAS_WIPER_SPEED_11" 10 "DAS_WIPER_SPEED_10" 9 "DAS_WIPER_SPEED_9" 8 "DAS_WIPER_SPEED_8" 7 "DAS_WIPER_SPEED_7" 6 "DAS_WIPER_SPEED_6" 5 "DAS_WIPER_SPEED_5" 4 "DAS_WIPER_SPEED_4" 3 "DAS_WIPER_SPEED_3" 2 "DAS_WIPER_SPEED_2" 1 "DAS_WIPER_SPEED_1" 0 "DAS_WIPER_SPEED_OFF" ;
VAL_ 1001 DAS_turnIndicatorRequest 4 "DAS_TURN_INDICATOR_DEFER" 3 "DAS_TURN_INDICATOR_CANCEL" 2 "DAS_TURN_INDICATOR_RIGHT" 1 "DAS_TURN_INDICATOR_LEFT" 0 "DAS_TURN_INDICATOR_NONE" ;
VAL_ 1001 DAS_highLowBeamDecision 3 "DAS_HIGH_BEAM_SNA" 2 "DAS_HIGH_BEAM_ON" 1 "DAS_HIGH_BEAM_OFF" 0 "DAS_HIGH_BEAM_UNDECIDED" ;
VAL_ 1001 DAS_heaterRequest 2 "DAS_HEATER_ON" 1 "DAS_HEATER_OFF" 0 "DAS_HEATER_SNA" ;
VAL_ 1001 DAS_highLowBeamOffReason 5 "HIGH_BEAM_OFF_REASON_SNA" 4 "HIGH_BEAM_OFF_REASON_HEAD_LIGHT" 3 "HIGH_BEAM_OFF_REASON_AMBIENT_LIGHT" 2 "HIGH_BEAM_OFF_REASON_MOVING_RADAR_TARGET" 1 "HIGH_BEAM_OFF_REASON_MOVING_VISION_TARGET" 0 "HIGH_BEAM_ON" ;
VAL_ 1001 DAS_mirrorFoldRequest 3 "DAS_MIRROR_REQUEST_SNA" 2 "DAS_MIRROR_REQUEST_UNFOLD" 1 "DAS_MIRROR_REQUEST_FOLD" 0 "DAS_MIRROR_REQUEST_NONE" ;
VAL_ 1001 DAS_autoWiperState 5 "DAS_AUTO_WIPER_STATE_SNA" 4 "DAS_AUTO_WIPER_STATE_FAST_CONTINUOUS" 3 "DAS_AUTO_WIPER_STATE_SLOW_CONTINUOUS" 2 "DAS_AUTO_WIPER_STATE_FAST_INTERMITTENT" 1 "DAS_AUTO_WIPER_STATE_SLOW_INTERMITTENT" 0 "DAS_AUTO_WIPER_STATE_OFF" ;
VAL_ 1001 DAS_turnIndicatorRequestReason 24 "DAS_ACTIVE_SIMULTANEOUS_LANE_CHANGE_AVOIDANCE" 23 "DAS_ACTIVE_INFEASIBLE_KINEMATICS_LANE_CHANGE" 22 "DAS_ACTIVE_STAY_OUT_OF_RIGHTMOST_LANE_LANE_CHANGE" 21 "DAS_ACTIVE_AWAY_FROM_MERGE_LANE_CHANGE" 20 "DAS_ACTIVE_EXIT_RIGHT_LANE_LANE_CHANGE" 19 "DAS_ACTIVE_EXIT_PASSING_LANE_LANE_CHANGE" 18 "DAS_ACTIVE_INCORRECT_ROAD_SIDE_LANE_CHANGE" 17 "DAS_ACTIVE_STATIC_OBJECT_LANE_CHANGE" 15 "DAS_CANCEL_MANUAL_BLINKER" 14 "DAS_CANCEL_AUTO_PARK" 13 "DAS_ACTIVE_AUTO_PARK" 12 "DAS_CANCEL_SUMMMON" 11 "DAS_ACTIVE_SUMMMON" 10 "DAS_CANCEL_INTERSECTION" 9 "DAS_ACTIVE_INTERSECTION" 8 "DAS_ACTIVE_COMMANDED_LANE_CHANGE" 7 "DAS_CANCEL_MERGE" 6 "DAS_ACTIVE_MERGE" 5 "DAS_CANCEL_FORK" 4 "DAS_CANCEL_LANE_CHANGE" 3 "DAS_ACTIVE_FORK" 2 "DAS_ACTIVE_SPEED_LANE_CHANGE" 1 "DAS_ACTIVE_NAV_LANE_CHANGE" 0 "DAS_NONE" ;
VAL_ 1001 DAS_restrictDoorReleaseLeft 1 "RESTRICT_DOOR_RELEASE_ACTIVE" 0 "RESTRICT_DOOR_RELEASE_INACTIVE" ;
VAL_ 1001 DAS_restrictDoorReleaseRight 1 "RESTRICT_DOOR_RELEASE_ACTIVE" 0 "RESTRICT_DOOR_RELEASE_INACTIVE" ;
VAL_ 1318 DIF_alertID 255 "a255_currentGainFallback" 254 "a254_activeDischargeRail" 253 "a253_lvBoostedRail" 252 "a252_currentCoreFallback" 251 "a251_oilPumpService" 250 "a250_preregulatorRail" 249 "a249_highStatorTempFromResist" 247 "a247_rotorOffsetError" 246 "a246_recoveryAtSpeedError" 245 "a245_mechSafeStatePreWarn" 244 "a244_mechSafeStateApplied" 243 "a243_ecuLogAvailable" 242 "a242_spinDownLearning" 241 "a241_systemThermallyLimited" 236 "a236_tasMIA" 234 "a234_pcsMIA" 233 "a233_diMsgMissed" 231 "a231_unintendedReset2" 225 "a225_tmpEstPlausibility" 202 "a202_excessHeatUnavailable" 177 "a177_fluxReferenceCorrected" 176 "a176_safetyICFault" 174 "a174_unitMayNotRestart" 162 "a162_endOfLifetimeBurnIn" 161 "a161_epas3pMIA" 160 "a160_busVoltageAnomaly" 158 "a158_ibstMIA" 157 "a157_rcmMIA" 156 "a156_currentObserver" 155 "a155_vcfrontMIA" 154 "a154_resolver" 153 "a153_oilPumpDiagnostics" 152 "a152_linError" 151 "a151_shockTorqueLimiter" 150 "a150_busVD" 149 "a149_oilPumpFailure" 148 "a148_burnInCycleEnded" 147 "a147_highTorqueWearLimit" 144 "a144_configMismatch" 142 "a142_highLashAngle" 136 "a136_spiError" 134 "a134_wheelSpeedIrrational" 133 "a133_capacitorOT" 128 "a128_fpgaVersionMismatch" 127 "a127_gracefulPowerOff" 126 "a126_limpMode" 123 "a123_lossMotorControl" 122 "a122_highStackUsage" 121 "a121_motorControlRegulation" 120 "a120_hvlinkMIA" 119 "a119_hvpMIA" 117 "a117_diMIA" 116 "a116_highSpeedWearCounter" 115 "a115_exceptionDataAbort2" 114 "a114_exceptionDataAbort" 113 "a113_noFuncHeatsinkSensor" 112 "a112_noPhaseCurrent" 111 "a111_badPhaseSensorCalib" 110 "a110_brakeMIA" 109 "a109_ahbWriteError" 108 "a108_stateTrans" 107 "a107_fpgaError" 103 "a103_lowFlow" 102 "a102_exceptionPrefetchAbort" 101 "a101_eccTestData1" 100 "a100_assertion" 99 "a099_threadOverrun" 98 "a098_intTimeTooLong" 97 "a097_eepromError" 96 "a096_memoryError" 95 "a095_canOverrunBusA" 94 "a094_canDataBusA" 93 "a093_canHardwareBusA" 92 "a092_bmsMIA" 91 "a091_espMIA" 90 "a090_pmMIA" 88 "a088_uiMIA" 87 "a087_gtwMIA" 86 "a086_activeDischargeOn" 84 "a084_eccTestData0" 83 "a083_PABCD_DIF_ECU_DemoWindow" 82 "a082_P7837_DIF_ECU_DemoTimer" 81 "a081_P0BFF_DIF_EM_CurrentHigh" 79 "a079_adcRefHigh" 78 "a078_adcRefLow" 77 "a077_lvSupplyUV" 76 "a076_lvSupplyOV" 75 "a075_motorSpeedMismatch" 74 "a074_motorEncoder" 73 "a073_motorSpeed" 72 "a072_gateDriveFaultCounter" 71 "a071_busDisconnected" 70 "a070_udsTransactionInitiated" 69 "a069_rotorTempLimit" 67 "a067_canOverrunBusB" 66 "a066_canDataBusB" 65 "a065_canHardwareBusB" 64 "a064_torqueIntervention" 63 "a063_bbMIA" 62 "a062_systemLimpMode" 61 "a061_heatsinkSensor" 60 "a060_heatsinkUT" 59 "a059_heatsinkOT" 58 "a058_ambientSensor" 57 "a057_ambientUT" 56 "a056_ambientOT" 55 "a055_trqCrossCheck" 54 "a054_driveInverterOT" 53 "a053_unexpectedLatchState" 52 "a052_dirMIA" 50 "a050_noStatorSensor" 49 "a049_statorSensorDiff" 48 "a048_statorSensor2" 47 "a047_statorSensor1" 46 "a046_statorOT" 45 "a045_outletSensor" 44 "a044_outletUT" 43 "a043_outletOT" 42 "a042_inletSensor" 41 "a041_sdcMIA" 40 "a040_difMIA" 39 "a039_exceptionUndefinedInstruction" 38 "a038_busVsensor" 37 "a037_busUV" 36 "a036_busOV" 35 "a035_phaseCurrentBalance" 34 "a034_phaseBcurrentSensor" 33 "a033_phaseAcurrentSensor" 32 "a032_phaseBcurrentOffset" 31 "a031_phaseAcurrentOffset" 30 "a030_phaseCrms" 29 "a029_phaseBrms" 28 "a028_phaseArms" 27 "a027_phaseCpeak" 26 "a026_phaseBpeak" 25 "a025_phaseApeak" 24 "a024_selfTest" 22 "a022_hw5vSupplyUV" 21 "a021_hwBusOV" 20 "a020_hwMotorEncoder" 18 "a018_hwLVSupplyUV" 17 "a017_hwPedalMonitor" 16 "a016_safeStateApplied" 15 "a015_mechSafeStateAnomaly" 14 "a014_activeDamping" 13 "a013_eccError" 12 "a012_hvilNotClosed" 11 "a011_swPowerStageNotReady" 10 "a010_unintendedReset" 9 "a009_hwEncoderB" 8 "a008_hwEncoderA" 7 "a007_statorAnomalyDetected" 6 "a006_hwPhaseCpeak" 5 "a005_hwPhaseBpeak" 4 "a004_hwPhaseApeak" 3 "a003_hwPhaseCgateDrive" 2 "a002_hwPhaseBgateDrive" 1 "a001_hwPhaseAgateDrive" 0 "ALERT_DO_NOT_USE_ZERO" ;
VAL_ 1318 DIF_alertState 1 "SET" 0 "CLEARED" ;
VAL_ 1318 DIF_a011_reason 4 "SPI_ERROR" 3 "FAULT_DURING_CONFIG" 2 "CRC_MISMATCH" 1 "REG_DATA_MISMATCH" 0 "GATE_DRIVE_SUPPLY" ;
VAL_ 1318 DIF_a012_hvilStatus 3 "SNA" 2 "CLOSED" 1 "OPEN" 0 "DISABLED" ;
VAL_ 1318 DIF_a013_errorType 12 "RAM_CORRECTABLE_DMA" 11 "RAM_CORRECTABLE_CLA" 10 "RAM_CORRECTABLE_CPU" 9 "RAM_UNCORRECTABLE_DMA" 8 "RAM_UNCORRECTABLE_CLA" 7 "RAM_UNCORRECTABLE_CPU" 6 "FLASH_FAIL1_HIGH" 5 "FLASH_FAIL1_LOW" 4 "FLASH_FAIL0_HIGH" 3 "FLASH_FAIL0_LOW" 2 "FLASH_UNCORRECTABLE_HIGH" 1 "FLASH_UNCORRECTABLE_LOW" 0 "UNKNOWN" ;
VAL_ 1318 DIF_a014_adState 3 "FAULTED" 2 "BACKUP" 1 "NORMAL" 0 "STARTUP" ;
VAL_ 1318 DIF_a016_newSafeState 3 "3PS_LOW" 2 "3PS_HIGH" 1 "ALL_OFF" 0 "NONE" ;
VAL_ 1318 DIF_a016_oldSafeState 3 "3PS_LOW" 2 "3PS_HIGH" 1 "ALL_OFF" 0 "NONE" ;
VAL_ 1318 DIF_a016_triggerEvent 23 "AT_SPEED_RECOVERY" 22 "CURRENT_OBSERVER" 21 "MECHSS_CALLBACK" 20 "3PS_FEEDBACK" 19 "SWITCH_OFF_PATH_TRIP" 18 "BUS_ANOMALY" 17 "GDIC_FAULT" 16 "SELFTEST_FAIL" 15 "CLEAR_FUSES" 14 "SPEED_INVALID" 13 "BUS_UV" 12 "BUS_IRRATIONAL" 11 "BUS_OV" 10 "PEAK_CURRENT" 9 "NO_CURRENT" 8 "IRRATIONAL_CURRENT_DELTA_PHASEB" 7 "IRRATIONAL_CURRENT_DELTA_PHASEA" 6 "IRRATIONAL_CURRENT_VREF" 5 "IRRATIONAL_CURRENT_PHASEB" 4 "IRRATIONAL_CURRENT_PHASEA" 3 "RESOLVER" 2 "MOTOR_SPEED" 1 "LV_SUPPLY_UV" 0 "UNKNOWN" ;
VAL_ 1318 DIF_a024_failReason 7 "ASC_TEST" 6 "FAULT_PRESENT" 5 "GATE_DRIVE_ERROR" 4 "TIMEDOUT" 3 "DISAGREE" 2 "NEG_CURRENT" 1 "POS_CURRENT" 0 "CACHED" ;
VAL_ 1318 DIF_a024_state 12 "TEST_RESTART" 11 "TEST_FAILED" 10 "TEST_SKIPPED" 9 "TEST_PASSED" 8 "TEST_PRE_PASSED" 7 "CURRENT_TEST_NEG" 6 "CURRENT_TEST_POS" 5 "PWM_ENABLE" 4 "ASC_TEST_PASSED" 3 "ASC_TEST" 2 "PSTG_BRING_UP_AT_SPEED" 1 "PSTG_BRING_UP" 0 "INIT" ;
VAL_ 1318 DIF_a038_reason 2 "DI_BMS_VOLTAGE_MISMATCH" 1 "UNDERVOLTAGE_HV_UP" 0 "UNDERVOLTAGE_PRE_CHARGE" ;
VAL_ 1318 DIF_a055_torqueType 2 "PEDAL_POSITION" 1 "TORQUE_COMMAND" 0 "TORQUE_ESTIMATE" ;
VAL_ 1318 DIF_a061_sensor 2 "PH3" 1 "PH2" 0 "PH1" ;
VAL_ 1318 DIF_a061_reason 1 "RAILED" 0 "RATE_OF_CHANGE" ;
VAL_ 1318 DIF_a062_limpReason 42 "DEGRADED_REQUEST_VCRIGHT" 41 "DEGRADED_REQUEST_VCLEFT" 40 "DEGRADED_REQUEST_PEPS" 39 "DEGRADED_REQUEST_SEPS" 38 "DEGRADED_REQUEST_PSFA" 37 "DEGRADED_REQUEST_SSFA" 36 "XTAL_OSCILLATOR" 35 "CURRENT_CORE_FALLBACK" 34 "MECHANICAL_SAFE_ST_UNAVAIL" 33 "MOTION_IN_DYNO" 32 "RESIST_STATOR_TEMP" 31 "OIL_PRESSURE_LOW" 30 "HEATSINK_SENSOR_IRRATIONAL" 29 "OIL_PUMP_FLUID_OVERTEMP" 28 "OIL_PUMP_FAILURE" 27 "FACTORY_GLIDER" 26 "SLAVE_MIA" 25 "SLAVE_REQUEST" 24 "CONTACTOR_WELD" 23 "CAPACITOR_OVERTEMP" 22 "GTW_MIA" 21 "TRQCMD_VALIDITY_UNKNOWN" 20 "DI_MIA" 19 "CONFIG_MISMATCH" 18 "HEATSINK_TEMP" 17 "PMREQUEST" 16 "PMHEARTBEAT" 15 "TRQ_CROSS_CHECK" 14 "EXTERNAL_COMMAND" 13 "WRONG_CS_CALIBRATION" 12 "STATOR_TEMP" 11 "DELTAT_TOO_NEGATIVE" 10 "DELTAT_TOO_POSITIVE" 9 "AMBIENT_TEMP" 8 "OUTLET_TEMP" 7 "LOW_FLOW" 6 "BMS_MIA" 5 "LV_SUPPLY_UNDERVOLTAGE" 4 "NO_FLUID" 3 "NO_FUNC_HEATSINK_SENSOR" 2 "NO_FUNC_STATORT_SENSOR" 1 "BUSV_SENSOR_IRRATIONAL" 0 "PHASE_IMBALANCE" ;
VAL_ 1318 DIF_a064_interventionType 15 "excessiveMotorMz" 14 "inconsistentAxleTorque" 13 "diHeartbeat" 12 "currentAfterIntervention" 11 "switchingAfterIntervention" 10 "switchOffPathTestFail" 9 "inconsistentTorqueSign" 8 "torqueInNeutral" 7 "excessiveRegenTorque" 6 "torqueReversal" 5 "accumulatedTorque" 4 "motorMovementDetected" 3 "cruiseFault" 2 "torqueCmdInvalid" 1 "resolver" 0 "masterTorqueMonitorShutoff" ;
VAL_ 1318 DIF_a064_torqueCmdState 8 "Invalid" 6 "Valid" 0 "SNA" ;
VAL_ 1318 DIF_a066_canID 2047 "GTW_carConfig" 1910 "XCP_difRequest" 1541 "UDS_difRequest" 1320 "GTW_time" 1280 "UI_debugECU" 950 "DI_odometerStatus" 914 "BMS_packConfig" 820 "UI_powertrainControl" 801 "VCFRONT_sensors" 792 "GTW_carState" 744 "EPBR_status" 680 "EPBL_status" 662 "UI_chassisControlDebug" 659 "UI_chassisControl" 644 "UI_vehicleModes" 577 "VCFRONT_coolant" 548 "PCS_dcdcStatus" 545 "VCFRONT_LVPowerState" 530 "BMS_status" 469 "PMF_state4" 306 "BMS_hvBusStatus" ;
VAL_ 1318 DIF_a066_errorType 6 "UNKNOWN_ID" 5 "DATA_INVALID" 4 "SEQUENCE" 3 "CHECKSUM" 2 "LENGTH_LONG" 1 "LENGTH_SHORT" 0 "NONE" ;
VAL_ 1318 DIF_a072_reason 3 "SWITCH_SHORT_TEST" 2 "MECHSS" 1 "EXTERNAL_OSCILLATOR" 0 "DEFAULT" ;
VAL_ 1318 DIF_a090_reason 1 "TOOFAST" 0 "TOOSLOW" ;
VAL_ 1318 DIF_a094_canID 2047 "GTW_carConfig" 1910 "XCP_difRequest" 1541 "UDS_difRequest" 1320 "GTW_time" 1280 "UI_debugECU" 950 "DI_odometerStatus" 914 "BMS_packConfig" 820 "UI_powertrainControl" 801 "VCFRONT_sensors" 792 "GTW_carState" 744 "EPBR_status" 680 "EPBL_status" 662 "UI_chassisControlDebug" 659 "UI_chassisControl" 644 "UI_vehicleModes" 577 "VCFRONT_coolant" 548 "PCS_dcdcStatus" 545 "VCFRONT_LVPowerState" 530 "BMS_status" 469 "PMF_state4" 306 "BMS_hvBusStatus" ;
VAL_ 1318 DIF_a094_errorType 6 "UNKNOWN_ID" 5 "DATA_INVALID" 4 "SEQUENCE" 3 "CHECKSUM" 2 "LENGTH_LONG" 1 "LENGTH_SHORT" 0 "NONE" ;
VAL_ 1318 DIF_a097_errorType 6 "DPOT_WRITE" 5 "DPOT_READ" 4 "LOST" 3 "CRC" 2 "WRITE" 1 "READ" 0 "OPEN" ;
VAL_ 1318 DIF_a098_fluxState 10 "STATIONARY_WASTE" 9 "FAULT" 7 "VCONTROL" 6 "ICONTROL" 5 "ENABLED" 4 "FLUX_DOWN" 3 "FLUX_UP" 2 "STANDBY" 1 "TEST" 0 "START" ;
VAL_ 1318 DIF_a108_blockingAlert 255 "a255_currentGainFallback" 254 "a254_activeDischargeRail" 253 "a253_lvBoostedRail" 252 "a252_currentCoreFallback" 251 "a251_oilPumpService" 250 "a250_preregulatorRail" 249 "a249_highStatorTempFromResist" 247 "a247_rotorOffsetError" 246 "a246_recoveryAtSpeedError" 245 "a245_mechSafeStatePreWarn" 244 "a244_mechSafeStateApplied" 243 "a243_ecuLogAvailable" 242 "a242_spinDownLearning" 241 "a241_systemThermallyLimited" 236 "a236_tasMIA" 234 "a234_pcsMIA" 233 "a233_diMsgMissed" 231 "a231_unintendedReset2" 225 "a225_tmpEstPlausibility" 202 "a202_excessHeatUnavailable" 177 "a177_fluxReferenceCorrected" 176 "a176_safetyICFault" 174 "a174_unitMayNotRestart" 162 "a162_endOfLifetimeBurnIn" 161 "a161_epas3pMIA" 160 "a160_busVoltageAnomaly" 158 "a158_ibstMIA" 157 "a157_rcmMIA" 156 "a156_currentObserver" 155 "a155_vcfrontMIA" 154 "a154_resolver" 153 "a153_oilPumpDiagnostics" 152 "a152_linError" 151 "a151_shockTorqueLimiter" 150 "a150_busVD" 149 "a149_oilPumpFailure" 148 "a148_burnInCycleEnded" 147 "a147_highTorqueWearLimit" 144 "a144_configMismatch" 142 "a142_highLashAngle" 136 "a136_spiError" 134 "a134_wheelSpeedIrrational" 133 "a133_capacitorOT" 128 "a128_fpgaVersionMismatch" 127 "a127_gracefulPowerOff" 126 "a126_limpMode" 123 "a123_lossMotorControl" 122 "a122_highStackUsage" 121 "a121_motorControlRegulation" 120 "a120_hvlinkMIA" 119 "a119_hvpMIA" 117 "a117_diMIA" 116 "a116_highSpeedWearCounter" 115 "a115_exceptionDataAbort2" 114 "a114_exceptionDataAbort" 113 "a113_noFuncHeatsinkSensor" 112 "a112_noPhaseCurrent" 111 "a111_badPhaseSensorCalib" 110 "a110_brakeMIA" 109 "a109_ahbWriteError" 108 "a108_stateTrans" 107 "a107_fpgaError" 103 "a103_lowFlow" 102 "a102_exceptionPrefetchAbort" 101 "a101_eccTestData1" 100 "a100_assertion" 99 "a099_threadOverrun" 98 "a098_intTimeTooLong" 97 "a097_eepromError" 96 "a096_memoryError" 95 "a095_canOverrunBusA" 94 "a094_canDataBusA" 93 "a093_canHardwareBusA" 92 "a092_bmsMIA" 91 "a091_espMIA" 90 "a090_pmMIA" 88 "a088_uiMIA" 87 "a087_gtwMIA" 86 "a086_activeDischargeOn" 84 "a084_eccTestData0" 83 "a083_PABCD_DIF_ECU_DemoWindow" 82 "a082_P7837_DIF_ECU_DemoTimer" 81 "a081_P0BFF_DIF_EM_CurrentHigh" 79 "a079_adcRefHigh" 78 "a078_adcRefLow" 77 "a077_lvSupplyUV" 76 "a076_lvSupplyOV" 75 "a075_motorSpeedMismatch" 74 "a074_motorEncoder" 73 "a073_motorSpeed" 72 "a072_gateDriveFaultCounter" 71 "a071_busDisconnected" 70 "a070_udsTransactionInitiated" 69 "a069_rotorTempLimit" 67 "a067_canOverrunBusB" 66 "a066_canDataBusB" 65 "a065_canHardwareBusB" 64 "a064_torqueIntervention" 63 "a063_bbMIA" 62 "a062_systemLimpMode" 61 "a061_heatsinkSensor" 60 "a060_heatsinkUT" 59 "a059_heatsinkOT" 58 "a058_ambientSensor" 57 "a057_ambientUT" 56 "a056_ambientOT" 55 "a055_trqCrossCheck" 54 "a054_driveInverterOT" 53 "a053_unexpectedLatchState" 52 "a052_dirMIA" 50 "a050_noStatorSensor" 49 "a049_statorSensorDiff" 48 "a048_statorSensor2" 47 "a047_statorSensor1" 46 "a046_statorOT" 45 "a045_outletSensor" 44 "a044_outletUT" 43 "a043_outletOT" 42 "a042_inletSensor" 41 "a041_sdcMIA" 40 "a040_difMIA" 39 "a039_exceptionUndefinedInstruction" 38 "a038_busVsensor" 37 "a037_busUV" 36 "a036_busOV" 35 "a035_phaseCurrentBalance" 34 "a034_phaseBcurrentSensor" 33 "a033_phaseAcurrentSensor" 32 "a032_phaseBcurrentOffset" 31 "a031_phaseAcurrentOffset" 30 "a030_phaseCrms" 29 "a029_phaseBrms" 28 "a028_phaseArms" 27 "a027_phaseCpeak" 26 "a026_phaseBpeak" 25 "a025_phaseApeak" 24 "a024_selfTest" 22 "a022_hw5vSupplyUV" 21 "a021_hwBusOV" 20 "a020_hwMotorEncoder" 18 "a018_hwLVSupplyUV" 17 "a017_hwPedalMonitor" 16 "a016_safeStateApplied" 15 "a015_mechSafeStateAnomaly" 14 "a014_activeDamping" 13 "a013_eccError" 12 "a012_hvilNotClosed" 11 "a011_swPowerStageNotReady" 10 "a010_unintendedReset" 9 "a009_hwEncoderB" 8 "a008_hwEncoderA" 7 "a007_statorAnomalyDetected" 6 "a006_hwPhaseCpeak" 5 "a005_hwPhaseBpeak" 4 "a004_hwPhaseApeak" 3 "a003_hwPhaseCgateDrive" 2 "a002_hwPhaseBgateDrive" 1 "a001_hwPhaseAgateDrive" 0 "ALERT_DO_NOT_USE_ZERO" ;
VAL_ 1318 DIF_a121_badRegReason 5 "TORQUE_OFF_TARGET" 4 "FLUX_OFF_TARGET" 3 "IQ_OFF_TARGET" 2 "ID_OFF_TARGET" 1 "RMS_I_HIGH" ;
VAL_ 1318 DIF_a123_lossReason 4 "HIGH_FLUX_DISTURBANCE" 3 "HIGH_VAR_CURR" 2 "HIGH_VAR_FLUX" 1 "NO_FLUX_UP" ;
VAL_ 1318 DIF_a126_limpReason 42 "DEGRADED_REQUEST_VCRIGHT" 41 "DEGRADED_REQUEST_VCLEFT" 40 "DEGRADED_REQUEST_PEPS" 39 "DEGRADED_REQUEST_SEPS" 38 "DEGRADED_REQUEST_PSFA" 37 "DEGRADED_REQUEST_SSFA" 36 "XTAL_OSCILLATOR" 35 "CURRENT_CORE_FALLBACK" 34 "MECHANICAL_SAFE_ST_UNAVAIL" 33 "MOTION_IN_DYNO" 32 "RESIST_STATOR_TEMP" 31 "OIL_PRESSURE_LOW" 30 "HEATSINK_SENSOR_IRRATIONAL" 29 "OIL_PUMP_FLUID_OVERTEMP" 28 "OIL_PUMP_FAILURE" 27 "FACTORY_GLIDER" 26 "SLAVE_MIA" 25 "SLAVE_REQUEST" 24 "CONTACTOR_WELD" 23 "CAPACITOR_OVERTEMP" 22 "GTW_MIA" 21 "TRQCMD_VALIDITY_UNKNOWN" 20 "DI_MIA" 19 "CONFIG_MISMATCH" 18 "HEATSINK_TEMP" 17 "PMREQUEST" 16 "PMHEARTBEAT" 15 "TRQ_CROSS_CHECK" 14 "EXTERNAL_COMMAND" 13 "WRONG_CS_CALIBRATION" 12 "STATOR_TEMP" 11 "DELTAT_TOO_NEGATIVE" 10 "DELTAT_TOO_POSITIVE" 9 "AMBIENT_TEMP" 8 "OUTLET_TEMP" 7 "LOW_FLOW" 6 "BMS_MIA" 5 "LV_SUPPLY_UNDERVOLTAGE" 4 "NO_FLUID" 3 "NO_FUNC_HEATSINK_SENSOR" 2 "NO_FUNC_STATORT_SENSOR" 1 "BUSV_SENSOR_IRRATIONAL" 0 "PHASE_IMBALANCE" ;
VAL_ 1318 DIF_a127_gpoReason 14 "MOTION_EXPECTED_DURING_SPINDOWN_LEARNING" 13 "FACTORY_DRIVE_DISTANCE_EXCEEDED" 12 "DEGRADED_LIMP_NO_DECEL" 11 "DEGRADED_LIMP_TIMEOUT" 10 "SBW_NODE_UNAVAILABLE" 9 "MOTION_DURING_SPINDOWN_LEARNING" 8 "MOTOR_HALT_REQUEST" 7 "CAPACITOR_OVERTEMP" 6 "NOT_ENOUGH_12V" 5 "NO_BATTERY_POWER" 4 "AMBIENT_OVERTEMP" 3 "FLUID_DELTAT" 2 "STATOR_OVERTEMP" 1 "HEATSINK_OVERTEMP" 0 "OUTLET_OVERTEMP" ;
VAL_ 1318 DIF_a149_flow 255 "SNA" ;
VAL_ 1318 DIF_a149_state 7 "SNA" 6 "FAULTED" 2 "COLD_STARTUP" 1 "ENABLE" 0 "STANDBY" ;
VAL_ 1318 DIF_a149_pcbaID 1 "5" 0 "LESS_THAN_5" ;
VAL_ 1318 DIF_a152_errorType 6 "TIMEOUT_ERROR" 5 "HEADER_ERROR" 4 "OVERFLOW_ERROR" 3 "SCHEDULE_ERROR" 2 "CHECKSUM_ERROR" 1 "FRAMING_ERROR" 0 "NO_ERROR" ;
VAL_ 1318 DIF_a153_oilFlow 255 "SNA" ;
VAL_ 1318 DIF_a153_oilTemperature 255 "SNA" ;
VAL_ 1318 DIF_a153_phaseCurrent 255 "SNA" ;
VAL_ 1318 DIF_a153_dcVoltage 255 "SNA" ;
VAL_ 1318 DIF_a153_state 7 "SNA" 6 "FAULTED" 2 "COLD_STARTUP" 1 "ENABLE" 0 "STANDBY" ;
VAL_ 1318 DIF_a153_oilPumpAlert 28 "A028_PHASE_CURRENT_IRRATIONAL" 27 "A027_FLUID_PRESSURE_CHECK" 26 "A026_FLUID_PRESSURE_VERY_LOW" 25 "A025_MOTOR_CONTROL" 24 "A024_MEMORY_ERROR" 23 "A023_SPI_ERROR" 22 "A022_MOTOR_STALL" 21 "A021_MOTOR_OVERLOAD" 20 "A020_FLUID_TEMP_IRRAT" 19 "A019_FLUID_PRESS_IRRAT" 18 "A018_FLUID_PRESS_HIGH" 17 "A017_FLUID_PRESS_LOW" 16 "A016_PUMP_TEMP_IRRAT" 15 "A015_PUMP_OVERTEMP" 14 "A014_MOTOR_SPEED_IRRAT" 13 "A013_MOTOR_SPEED_TOO_HIGH" 12 "A012_MOTOR_SPEED_NEG" 11 "A011_MOTOR_CURRENT_IRRAT" 10 "A010_MOTOR_OPEN_PHASE" 9 "A009_MOTOR_SHORTED" 8 "A008_SUPPLY_IRRAT" 7 "A007_SUPPLY_OV" 6 "A006_SUPPLY_UV" 5 "A005_LIN_ID_PARITY_ERR" 4 "A004_LIN_FRAMING_ERR" 3 "A003_LIN_CHECKSUM_ERR" 2 "A002_LIN_DATA_ERR" 1 "A001_ECU_RESET" 0 "A000_NONE" ;
VAL_ 1318 DIF_a153_reason 5 "PRESS_HIGH" 4 "PRESS_LOW" 3 "PRESS_9LPM_OK" 2 "PRESS_6LPM_OK" 1 "OPC_ALERT" 0 "NONE" ;
VAL_ 1318 DIF_a202_reason 12 "HV_DOWN" 11 "CRUISE" 10 "OPD" 9 "DRV_FAULT" 8 "IMMEDIATE" 7 "SERVICE_MODE" 6 "UPDATE_STARTED" 5 "GPO" 4 "LIMP" 3 "MOVEMENT" 2 "PARKBRAKE" 1 "NO_ALERT" 0 "NONE" ;
VAL_ 1318 DIF_a202_sysStateExitCondition 19 "IDLE_TRUNK_OPEN" 18 "UNAVAILABLE_EXIT_OK" 17 "UNAVAILABLE_UNITS_NOT_AVAILABLE" 16 "UNAVAILABLE_SSPD_SPEED_IS_NOT_PUBLISHED" 15 "UNAVAILABLE_ALERTS_ACTIVE" 14 "UNAVAILABLE_HV_IS_NOT_UP" 13 "UNAVAILABLE_SLIM_GPO_OR_CAN_DRIVE_GOING_DOWN" 12 "IDLE_EXIT_OK" 11 "IDLE_FIRMWARE_VERIFICATION" 10 "IDLE_BATTERY_POWER_LIMITS" 9 "IDLE_NON_ZERO_PEDAL_POS" 8 "IDLE_FALCON_DOOR_OPEN" 7 "IDLE_PROX_DETECTED" 6 "IDLE_FRUNK_NOT_LATCHED" 5 "IDLE_IMMOBILIZER_INHIBIT" 4 "IDLE_HV_NOT_UP_FOR_DRIVE" 3 "IDLE_LV_OR_SBW_STATUS_LIMP" 2 "IDLE_LV_OR_SBW_STATUS_NOT_READY" 1 "IDLE_DRIVE_RAIL_NOT_REQUESTED" 0 "IDLE_VEHICLE_POWER_STATE_NOT_DRIVE" ;
VAL_ 1318 DIF_a246_codeBranch 3 "SAFESTATE_RELEASE_LATCH" 2 "SAFESTATE_RELEASE_ASC" 1 "PSTG_INIT" 0 "QUALIFICATION" ;
VAL_ 1318 DIF_a251_oilFlow 255 "SNA" ;
VAL_ 1318 DIF_a251_oilTemperature 255 "SNA" ;
VAL_ 1318 DIF_a251_dcVoltage 255 "SNA" ;
VAL_ 1318 DIF_a251_dcCurrent 255 "SNA" ;
VAL_ 1318 DIF_a251_phaseCurrent 255 "SNA" ;
VAL_ 1318 DIF_a251_reason 4 "INSUFFICIENT_FLOW" 3 "CURRENT_SENSOR" 2 "PRESSURE_HIGH" 1 "PRESSURE_LOW" 0 "NONE" ;
VAL_ 634 DIF_hvilStatus 3 "SNA" 2 "CLOSED" 1 "OPEN" 0 "DISABLED" ;
VAL_ 634 DIF_hvilSupplyState 2 "ACTIVE" 1 "INACTIVE" 0 "NOT_AVAILABLE" ;
VAL_ 634 DIF_vBatQF 1 "QUALIFIED" 0 "NOT_QUALIFIED" ;
VAL_ 634 DIF_powerStageSafeState 3 "PSTG_SAFESTATE_3PS_LOW" 2 "PSTG_SAFESTATE_3PS_HIGH" 1 "PSTG_SAFESTATE_ALL_OFF" 0 "PSTG_SAFESTATE_NONE" ;
VAL_ 634 DIF_fluxState 12 "DI_FLUXSTATE_DISABLED" 11 "DI_FLUXSTATE_MAGNET_FLUX_DETECT" 10 "DI_FLUXSTATE_STATIONARY_WASTE" 9 "DI_FLUXSTATE_FAULT" 7 "DI_FLUXSTATE_VCONTROL" 6 "DI_FLUXSTATE_ICONTROL" 5 "DI_FLUXSTATE_ENABLED" 4 "DI_FLUXSTATE_FLUX_DOWN" 3 "DI_FLUXSTATE_FLUX_UP" 2 "DI_FLUXSTATE_STANDBY" 1 "DI_FLUXSTATE_TEST" 0 "DI_FLUXSTATE_START" ;
VAL_ 634 DIF_gateDriveState 4 "PSTG_GD_STATE_NOT_CONFIGURED" 3 "PSTG_GD_STATE_CONFIGURED" 2 "PSTG_GD_STATE_CONFIGURING" 1 "PSTG_GD_STATE_SELFTEST" 0 "PSTG_GD_STATE_INIT" ;
VAL_ 741 DIF_elecPower -1024 "SNA" ;
VAL_ 741 DIF_drivePowerMax 511 "SNA" ;
